VERSION "HNNBNNNYNNNNNNNNNNNNNNNNNNNNNNNNNNNNNNNNNN/4/%%%/4/'%**4NNN///"

NS_ :

BS_ :

BU_:  Airbag BAP_Tester ICAS1_Gateway ICAS1_KommunikationsServer LE1 LE2 Motor_BEV Schaltbetaetigung

BO_ 1648 Motor_18: 8 Motor_BEV
 SG_ MO_max_Ladedruck  : 0|6@1+ (0.100000,0.000000) [0.000000|6.300000] "Unit_Bar" ICAS1_Gateway
 SG_ MO_ANC_Kennfeld_Anf  : 6|2@1+ (1.000000,0.000000) [0.000000|3.000000] "" ICAS1_Gateway
 SG_ MO_Bremslicht_Reku  : 8|1@1+ (1.000000,0.000000) [0.000000|1.000000] "" ICAS1_Gateway
 SG_ MO_StartStopp_PopUp  : 9|2@1+ (1.000000,0.000000) [0.000000|3.000000] "" ICAS1_Gateway
 SG_ MO1_Sperr_Info_WFS  : 11|1@1+ (1.000000,0.000000) [0.000000|1.000000] "" ICAS1_Gateway
 SG_ MO1_Freigabe_Info_WFS  : 12|1@1+ (1.000000,0.000000) [0.000000|1.000000] "" ICAS1_Gateway
 SG_ MO_EPCL  : 13|3@1+ (1.000000,0.000000) [0.000000|7.000000] "" ICAS1_Gateway ICAS1_KommunikationsServer
 SG_ MO_Zylabsch_Texte_02  : 16|4@1+ (1.000000,0.000000) [0.000000|15.000000] "" ICAS1_Gateway
 SG_ MO_Fahrzeugtyp  : 20|3@1+ (1.000000,0.000000) [0.000000|7.000000] "" ICAS1_Gateway ICAS1_KommunikationsServer
 SG_ MO_NMAX_Schaltanzeige  : 23|9@1+ (25.000000,0.000000) [0.000000|12775.000000] "Unit_MinutInver" ICAS1_Gateway
 SG_ MO_Abstellzeit  : 32|8@1+ (8.000000,0.000000) [0.000000|2024.000000] "Unit_Minut" ICAS1_Gateway
 SG_ MO_Abstellzeit_Status  : 40|2@1+ (1.000000,0.000000) [0.000000|3.000000] "" ICAS1_Gateway
 SG_ MO1_Freigabe_Verfallsinfo_WFS  : 42|1@1+ (1.000000,0.000000) [0.000000|1.000000] "" ICAS1_Gateway
 SG_ MO_Hybrid_StartStopp_LED  : 43|2@1+ (1.000000,0.000000) [0.000000|3.000000] "" ICAS1_Gateway
 SG_ MO_Fehler_Zylabsch  : 45|2@1+ (1.000000,0.000000) [0.000000|3.000000] "" ICAS1_Gateway
 SG_ MO_Anzahl_Abgesch_Zyl  : 47|3@1+ (1.000000,0.000000) [0.000000|7.000000] "" ICAS1_Gateway
 SG_ MO_Zylabsch_Texte  : 50|2@1+ (1.000000,0.000000) [0.000000|3.000000] "" ICAS1_Gateway
 SG_ MO_Ethanol_BS_Texte  : 52|3@1+ (1.000000,0.000000) [0.000000|7.000000] "" ICAS1_Gateway
 SG_ MO_Drehzahl_Warnung  : 55|1@1+ (1.000000,0.000000) [0.000000|1.000000] "" ICAS1_Gateway
 SG_ MO_obere_Drehzahlgrenze  : 56|8@1+ (50.000000,0.000000) [50.000000|12750.000000] "Unit_MinutInver" ICAS1_Gateway

BO_ 967 Motor_26: 8 Motor_BEV
 SG_ MO_Kuehlerluefter_MUX M : 0|1@1+ (1.000000,0.000000) [0.000000|1.000000] "siema ooo" ICAS1_Gateway
 SG_ MO_Kuehlerluefter_1 m0 : 1|7@1+ (1.000000,0.000000) [0.000000|100.000000] "Unit_PerCent" ICAS1_Gateway
 SG_ MO_Kuehlerluefter_2 m1 : 1|7@1+ (1.000000,0.000000) [0.000000|100.000000] "Unit_PerCent" ICAS1_Gateway
 SG_ MO_EFLEX_Lampe  : 8|2@1+ (1.000000,0.000000) [0.000000|3.000000] "" ICAS1_Gateway
 SG_ MO_KJS_nicht_bereit  : 10|1@1+ (1.000000,0.000000) [0.000000|1.000000] "" ICAS1_Gateway
 SG_ MO_ITM_Warnung_Pumpe  : 11|1@1+ (1.000000,0.000000) [0.000000|1.000000] "" ICAS1_Gateway
 SG_ WIV_Anzeige_aktiv  : 12|1@1+ (1.000000,0.000000) [0.000000|1.000000] "" ICAS1_Gateway
 SG_ WIV_Oelmin_Warn  : 13|1@1+ (1.000000,0.000000) [0.000000|1.000000] "" ICAS1_Gateway
 SG_ WIV_Sensorfehler  : 14|1@1+ (1.000000,0.000000) [0.000000|1.000000] "" ICAS1_Gateway
 SG_ WIV_Schieflage  : 15|1@1+ (1.000000,0.000000) [0.000000|1.000000] "" ICAS1_Gateway
 SG_ WIV_Oelstand  : 16|4@1+ (12.500000,0.000000) [0.000000|100.000000] "Unit_PerCent" ICAS1_Gateway
 SG_ MO_Zustand_HWP  : 20|2@1+ (1.000000,0.000000) [0.000000|3.000000] "" ICAS1_Gateway
 SG_ OLEV_Systemstoerung  : 22|1@1+ (1.000000,0.000000) [0.000000|1.000000] "" ICAS1_Gateway
 SG_ MO_Oelwarnung_max  : 23|1@1+ (1.000000,0.000000) [0.000000|1.000000] "" ICAS1_Gateway
 SG_ WIV_Oelsystem_aktiv  : 24|1@1+ (1.000000,0.000000) [0.000000|1.000000] "" ICAS1_Gateway
 SG_ WIV_nicht_betriebswarm  : 25|1@1+ (1.000000,0.000000) [0.000000|1.000000] "" ICAS1_Gateway
 SG_ WIV_Ueberfuell_Warn  : 26|1@1+ (1.000000,0.000000) [0.000000|1.000000] "" ICAS1_Gateway
 SG_ WIV_laufender_Motor  : 27|1@1+ (1.000000,0.000000) [0.000000|1.000000] "" ICAS1_Gateway
 SG_ MO_E_Warnungen  : 28|4@1+ (1.000000,0.000000) [0.000000|15.000000] "" ICAS1_Gateway
 SG_ MO_Text_Motorstart  : 32|4@1+ (1.000000,0.000000) [0.000000|15.000000] "" ICAS1_Gateway
 SG_ MO_E_Texte  : 36|4@1+ (1.000000,0.000000) [0.000000|15.000000] "" ICAS1_Gateway
 SG_ WIV_Oeldyn_avl  : 40|1@1+ (1.000000,0.000000) [0.000000|1.000000] "" ICAS1_Gateway
 SG_ MO_Text_Partikelfil_Reg  : 41|1@1+ (1.000000,0.000000) [0.000000|1.000000] "" ICAS1_Gateway
 SG_ OLEV_Oelstand_nicht_vorhanden  : 42|1@1+ (1.000000,0.000000) [0.000000|1.000000] "" ICAS1_Gateway
 SG_ WIV_Oelmenge  : 43|5@1+ (125.000000,0.000000) [0.000000|3875.000000] "Unit_MilliLiter" ICAS1_Gateway
 SG_ MO_Systemlampe  : 48|1@1+ (1.000000,0.000000) [0.000000|1.000000] "" ICAS1_Gateway
 SG_ MO_OBD2_Lampe  : 49|1@1+ (1.000000,0.000000) [0.000000|1.000000] "" ICAS1_Gateway
 SG_ MO_Heissleuchte  : 50|1@1+ (1.000000,0.000000) [0.000000|1.000000] "" ICAS1_Gateway
 SG_ MO_Partikel_Lampe  : 51|1@1+ (1.000000,0.000000) [0.000000|1.000000] "" ICAS1_Gateway
 SG_ MO_RedFahrleistung_Lampe  : 52|1@1+ (1.000000,0.000000) [0.000000|1.000000] "" ICAS1_Gateway ICAS1_KommunikationsServer
 SG_ WIV_Oelstand_nicht_vorhanden  : 53|1@1+ (1.000000,0.000000) [0.000000|1.000000] "" ICAS1_Gateway
 SG_ WIV_nachfuellanzeige_ein  : 54|1@1+ (1.000000,0.000000) [0.000000|1.000000] "" ICAS1_Gateway
 SG_ WIV_Ueberfuell_deaktiv  : 55|1@1+ (1.000000,0.000000) [0.000000|1.000000] "" ICAS1_Gateway
 SG_ WIV_Unterfuell_Warn  : 56|1@1+ (1.000000,0.000000) [0.000000|1.000000] "" ICAS1_Gateway
 SG_ MO_Tankdeckel_Lampe  : 57|1@1+ (1.000000,0.000000) [0.000000|1.000000] "" ICAS1_Gateway
 SG_ MO_Text_Tankdeckelwarn  : 58|1@1+ (1.000000,0.000000) [0.000000|1.000000] "" ICAS1_Gateway
 SG_ MO_Vorglueh_Lampe  : 59|1@1+ (1.000000,0.000000) [0.000000|1.000000] "" ICAS1_Gateway
 SG_ WIV_Oeldr_Warn_Motor  : 60|1@1+ (1.000000,0.000000) [0.000000|1.000000] "" ICAS1_Gateway
 SG_ MO_E_Mode  : 61|3@1+ (1.000000,0.000000) [0.000000|7.000000] "" ICAS1_Gateway

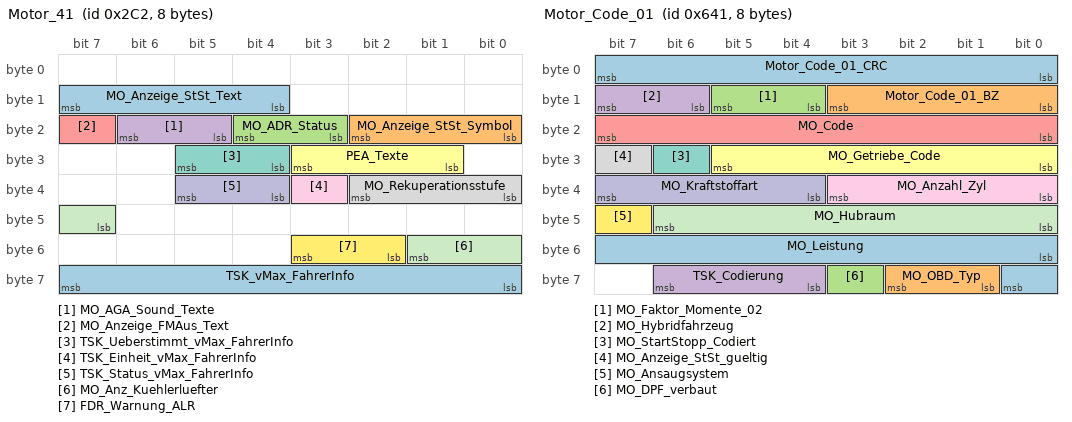
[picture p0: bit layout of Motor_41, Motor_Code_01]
BO_ 706 Motor_41: 8 Motor_BEV
 SG_ MO_Anzeige_StSt_Text  : 12|4@1+ (1.000000,0.000000) [0.000000|15.000000] "" Vector__XXX
 SG_ MO_Anzeige_StSt_Symbol  : 16|3@1+ (1.000000,0.000000) [0.000000|7.000000] "" Vector__XXX
 SG_ MO_ADR_Status  : 19|2@1+ (1.000000,0.000000) [0.000000|3.000000] "" Vector__XXX
 SG_ MO_AGA_Sound_Texte  : 21|2@1+ (1.000000,0.000000) [0.000000|3.000000] "" Vector__XXX
 SG_ MO_Anzeige_FMAus_Text  : 23|1@1+ (1.000000,0.000000) [0.000000|1.000000] "" Vector__XXX
 SG_ PEA_Texte  : 25|3@1+ (1.000000,0.000000) [0.000000|7.000000] "" Vector__XXX
 SG_ TSK_Ueberstimmt_vMax_FahrerInfo  : 28|2@1+ (1.000000,0.000000) [0.000000|3.000000] "" Vector__XXX
 SG_ MO_Rekuperationsstufe  : 32|3@1+ (1.000000,0.000000) [0.000000|7.000000] "" ICAS1_KommunikationsServer
 SG_ TSK_Einheit_vMax_FahrerInfo  : 35|1@1+ (1.000000,0.000000) [0.000000|1.000000] "" ICAS1_KommunikationsServer
 SG_ TSK_Status_vMax_FahrerInfo  : 36|2@1+ (1.000000,0.000000) [0.000000|3.000000] "" ICAS1_KommunikationsServer
 SG_ MO_Anz_Kuehlerluefter  : 47|3@1+ (1.000000,0.000000) [0.000000|7.000000] "" Vector__XXX
 SG_ FDR_Warnung_ALR  : 50|2@1+ (1.000000,0.000000) [0.000000|3.000000] "" ICAS1_KommunikationsServer
 SG_ TSK_vMax_FahrerInfo  : 56|8@1+ (1.000000,15.000000) [16.000000|270.000000] "" ICAS1_KommunikationsServer

BO_ 267 Motor_51: 32 Motor_BEV
 SG_ Motor_51_CRC  : 0|8@1+ (1.000000,0.000000) [0.000000|255.000000] "" ICAS1_Gateway
 SG_ Motor_51_BZ  : 8|4@1+ (1.000000,0.000000) [0.000000|15.000000] "" ICAS1_Gateway
 SG_ MO_Fahrpedalrohwert_01  : 12|8@1+ (0.400000,0.000000) [0.000000|101.600000] "Unit_PerCent" Airbag ICAS1_Gateway
 SG_ MO_QBit_Fahrpedalwerte_01  : 20|1@1+ (1.000000,0.000000) [0.000000|1.000000] "" Airbag ICAS1_Gateway
 SG_ MO_Fahrpedalgradient  : 21|8@1+ (25.000000,0.000000) [0.000000|6350.000000] "Unit_PerCentPerSecon" ICAS1_Gateway
 SG_ MO_Sig_Fahrpedalgradient  : 29|1@1+ (1.000000,0.000000) [0.000000|1.000000] "" ICAS1_Gateway
 SG_ MO_rel_Saugrohrdruck  : 30|6@1+ (18.000000,0.000000) [0.000000|1116.000000] "Unit_MilliBar" ICAS1_Gateway
 SG_ MO_rel_Saugrohrdruck_gem_err  : 36|1@1+ (1.000000,0.000000) [0.000000|1.000000] "" ICAS1_Gateway
 SG_ MO_Moment_im_Leerlauf  : 37|1@1+ (1.000000,0.000000) [0.000000|1.000000] "" ICAS1_Gateway
 SG_ MO_Schubabschaltung  : 38|1@1+ (1.000000,0.000000) [0.000000|1.000000] "" ICAS1_Gateway
 SG_ MO_Solldrehz_Leerlauf  : 40|8@1+ (10.000000,0.000000) [0.000000|2540.000000] "Unit_MinutInver" ICAS1_Gateway
 SG_ MO_Entkopplung_Sollschlupf  : 48|7@1+ (20.000000,0.000000) [0.000000|2480.000000] "Unit_MinutInver" ICAS1_Gateway
 SG_ MO_temporaere_Fahrerabwesenheit  : 55|1@1+ (1.000000,0.000000) [0.000000|1.000000] "" ICAS1_Gateway
 SG_ TSK_a_Soll_gradientenbegrenzt  : 57|7@1+ (0.100000,-7.200000) [-7.200000|5.400000] "Unit_MeterPerSeconSquar" ICAS1_Gateway
 SG_ TSK_Radbremsmom  : 76|12@1+ (8.000000,0.000000) [0.000000|32760.000000] "Unit_NewtoMeter" ICAS1_Gateway
 SG_ TSK_Status  : 88|3@1+ (1.000000,0.000000) [0.000000|7.000000] "" ICAS1_Gateway
 SG_ TSK_v_Begrenzung_aktiv  : 91|1@1+ (1.000000,0.000000) [0.000000|1.000000] "" ICAS1_Gateway
 SG_ TSK_Standby_Anf_ESP  : 92|1@1+ (1.000000,0.000000) [0.000000|1.000000] "" ICAS1_Gateway
 SG_ TSK_Freig_WU  : 93|1@1+ (1.000000,0.000000) [0.000000|1.000000] "" ICAS1_Gateway
 SG_ TSK_Freig_Verzoeg_Anf  : 94|1@1+ (1.000000,0.000000) [0.000000|1.000000] "" ICAS1_Gateway
 SG_ TSK_Limiter_ausgewaehlt  : 95|1@1+ (1.000000,0.000000) [0.000000|1.000000] "" ICAS1_Gateway
 SG_ TSK_Wunsch_Uebersetz  : 96|10@1+ (0.024500,0.000000) [0.024500|25.063500] "" ICAS1_Gateway
 SG_ TSK_Hauptschalter_GRA_ACC  : 106|2@1+ (1.000000,0.000000) [0.000000|3.000000] "" ICAS1_Gateway ICAS1_KommunikationsServer
 SG_ TSK_SRBM_Anf_ASIL  : 108|3@1+ (1.000000,0.000000) [0.000000|7.000000] "" ICAS1_Gateway
 SG_ TSK_ax_Getriebe_02  : 112|9@1+ (0.024000,-2.016000) [-2.016000|10.224000] "Unit_MeterPerSeconSquar" ICAS1_Gateway
 SG_ TSK_Zwangszusch_ESP  : 121|1@1+ (1.000000,0.000000) [0.000000|1.000000] "" ICAS1_Gateway
 SG_ TSK_zul_Regelabw  : 122|6@1+ (0.024000,0.000000) [0.000000|1.512000] "Unit_MeterPerSeconSquar" ICAS1_Gateway
 SG_ MO_Status_MinDrzEingriff  : 235|3@1+ (1.000000,0.000000) [0.000000|7.000000] "" ICAS1_Gateway
 SG_ MO_Status_MaxDrzEingriff  : 238|3@1+ (1.000000,0.000000) [0.000000|7.000000] "" ICAS1_Gateway
 SG_ MO_Status_MinDrzEingriff_sek  : 241|3@1+ (1.000000,0.000000) [0.000000|7.000000] "" ICAS1_Gateway
 SG_ MO_Status_MaxDrzEingriff_sek  : 244|3@1+ (1.000000,0.000000) [0.000000|7.000000] "" ICAS1_Gateway
 SG_ GRA_KuFu_aktiv  : 247|1@1+ (1.000000,0.000000) [0.000000|1.000000] "" ICAS1_Gateway
 SG_ TSK_SRBM_max_Gradient  : 248|7@1+ (50.000000,0.000000) [0.000000|6250.000000] "Unit_NewtoMeterPerSecon" ICAS1_Gateway
 SG_ LIM_KuFu_aktiv  : 255|1@1+ (1.000000,0.000000) [0.000000|1.000000] "" ICAS1_Gateway

BO_ 330 Motor_52: 32 Motor_BEV
 SG_ MO_Hochschaltdrehz  : 21|12@1+ (3.000000,0.000000) [3.000000|12282.000000] "Unit_MinutInver" Vector__XXX
 SG_ MO_Anzeige_Verbr_Einheit  : 33|2@1+ (1.000000,0.000000) [0.000000|3.000000] "" Vector__XXX
 SG_ MO_Schaltblitz_Anz  : 35|7@1+ (1.000000,0.000000) [0.000000|100.000000] "Unit_PerCent" Vector__XXX
 SG_ MO_Anzeige_Drehmoment  : 42|11@1+ (1.000000,0.000000) [0.000000|2045.000000] "Unit_NewtoMeter" Vector__XXX
 SG_ MO_Anzeige_Leistung  : 53|11@1+ (0.600000,0.000000) [0.000000|1227.000000] "Unit_KiloWatt" Vector__XXX
 SG_ MO_rel_Ladedruck  : 64|8@1+ (0.400000,0.000000) [0.000000|100.000000] "Unit_PerCent" Vector__XXX
 SG_ MO_Istgang  : 72|4@1+ (1.000000,0.000000) [0.000000|15.000000] "" Vector__XXX
 SG_ MO_Sollgang  : 76|4@1+ (1.000000,0.000000) [0.000000|15.000000] "" Vector__XXX
 SG_ MO_Oeldruck  : 80|8@1+ (0.040000,0.000000) [0.000000|10.000000] "Unit_Bar" Vector__XXX
 SG_ MO_Anzeigedrehz  : 88|12@1+ (3.000000,0.000000) [0.000000|12282.000000] "Unit_MinutInver" Vector__XXX
 SG_ MO_Effizienzmodus  : 100|1@1+ (1.000000,0.000000) [0.000000|1.000000] "" Vector__XXX
 SG_ MO_Fehler_Oeldrucksensor  : 101|1@1+ (1.000000,0.000000) [0.000000|1.000000] "" Vector__XXX
 SG_ MO_Schaltempf_verfbar  : 102|1@1+ (1.000000,0.000000) [0.000000|1.000000] "" Vector__XXX
 SG_ MO_Ladedruck  : 103|9@1+ (0.010000,0.000000) [0.000000|5.100000] "Unit_Bar" Vector__XXX
 SG_ MO_KVS  : 112|15@1+ (1.000000,0.000000) [0.000000|32767.000000] "Unit_MicroLiter" Vector__XXX
 SG_ MO_KVS_Ueberlauf  : 127|1@1+ (1.000000,0.000000) [0.000000|1.000000] "" Vector__XXX
 SG_ MO_ePowermeter  : 128|8@1+ (0.400000,-0.400000) [0.000000|100.800000] "Unit_PerCent" Vector__XXX
 SG_ MO_ePerformance  : 136|8@1+ (0.400000,-0.400000) [0.000000|100.800000] "Unit_PerCent" ICAS1_KommunikationsServer
 SG_ MO_Zust_Antrieb  : 144|4@1+ (1.000000,0.000000) [0.000000|15.000000] "" Vector__XXX
 SG_ MO_Zust_Betriebsstrategie  : 148|3@1+ (1.000000,0.000000) [0.000000|7.000000] "" Vector__XXX
 SG_ Ladezustand_02  : 152|8@1+ (0.500000,0.000000) [0.000000|100.000000] "Unit_PerCent" ICAS1_Gateway ICAS1_KommunikationsServer
 SG_ MO_Powermeter_Elm_02  : 168|12@1+ (0.050000,-102.400000) [-100.000000|100.000000] "Unit_PerCent" Vector__XXX
 SG_ MO_Powermeter  : 180|12@1+ (1.000000,0.000000) [0.000000|4092.000000] "" ICAS1_KommunikationsServer

BO_ 512 Motor_53: 32 Motor_BEV
 SG_ TSK_Wunschgeschw  : 12|10@1+ (0.320000,0.000000) [0.000000|326.720000] "Unit_KiloMeterPerHour" ICAS1_Gateway ICAS1_KommunikationsServer
 SG_ TSK_praediktiver_Hinweis  : 22|3@1+ (1.000000,0.000000) [0.000000|7.000000] "" ICAS1_Gateway
 SG_ TSK_naechstes_Event  : 25|6@1+ (1.000000,0.000000) [0.000000|63.000000] "" ICAS1_Gateway
 SG_ TSK_Fahrzeugstatus_praed_Fkt  : 31|3@1+ (1.000000,0.000000) [0.000000|7.000000] "" ICAS1_Gateway
 SG_ TSK_Texte  : 40|5@1+ (1.000000,0.000000) [0.000000|31.000000] "" ICAS1_Gateway ICAS1_KommunikationsServer
 SG_ TSK_Akustik  : 45|3@1+ (1.000000,0.000000) [0.000000|7.000000] "" ICAS1_Gateway ICAS1_KommunikationsServer
 SG_ TSK_Texte_Primaeranz  : 48|5@1+ (1.000000,0.000000) [0.000000|31.000000] "" ICAS1_Gateway ICAS1_KommunikationsServer
 SG_ TSK_Limiter_Fahrerinfo  : 53|2@1+ (1.000000,0.000000) [0.000000|3.000000] "" ICAS1_Gateway ICAS1_KommunikationsServer
 SG_ TSK_Limiter_Anzeige  : 55|1@1+ (1.000000,0.000000) [0.000000|1.000000] "" ICAS1_Gateway ICAS1_KommunikationsServer
 SG_ TSK_Fahrzeugstatus_GRA  : 56|1@1+ (1.000000,0.000000) [0.000000|1.000000] "" ICAS1_Gateway ICAS1_KommunikationsServer
 SG_ TSK_Fahrzeugstatus_Limiter  : 57|1@1+ (1.000000,0.000000) [0.000000|1.000000] "" ICAS1_Gateway ICAS1_KommunikationsServer
 SG_ MO_Motorlaufwarnung  : 58|1@1+ (1.000000,0.000000) [0.000000|1.000000] "" ICAS1_Gateway
 SG_ TSK_naechstes_Event_Einheit  : 60|1@1+ (1.000000,0.000000) [0.000000|1.000000] "" ICAS1_Gateway
 SG_ TSK_Status_Anzeige  : 61|3@1+ (1.000000,0.000000) [0.000000|7.000000] "" ICAS1_Gateway ICAS1_KommunikationsServer
 SG_ MO_Sperrung_FahrPr_BZS  : 64|8@1+ (1.000000,0.000000) [0.000000|255.000000] "" ICAS1_Gateway
 SG_ MO_Rampenzeit_Generator_Anf  : 72|4@1+ (1.000000,0.000000) [0.000000|15.000000] "" ICAS1_Gateway
 SG_ MO_Prio_MAX_Wunschdrehzahl  : 76|1@1+ (1.000000,0.000000) [0.000000|1.000000] "" ICAS1_Gateway
 SG_ MO_Prio_MIN_Wunschdrehzahl  : 77|1@1+ (1.000000,0.000000) [0.000000|1.000000] "" ICAS1_Gateway
 SG_ MO_Luftpfad_aktiv  : 78|1@1+ (1.000000,0.000000) [0.000000|1.000000] "" ICAS1_Gateway
 SG_ MO_v_Begrenz_Aktivierbar  : 79|1@1+ (1.000000,0.000000) [0.000000|1.000000] "" ICAS1_Gateway
 SG_ MO_Drehzahlbeeinflussung  : 80|8@1+ (0.390000,0.000000) [0.000000|99.450000] "Unit_PerCent" ICAS1_Gateway
 SG_ MO_MIN_Wunschdrehzahl  : 88|8@1+ (25.000000,0.000000) [0.000000|6350.000000] "Unit_MinutInver" ICAS1_Gateway
 SG_ MO_MAX_Wunschdrehzahl  : 96|9@1+ (25.000000,0.000000) [0.000000|12750.000000] "Unit_MinutInver" ICAS1_Gateway
 SG_ MO_Charisma_FahrPr  : 105|4@1+ (1.000000,0.000000) [0.000000|15.000000] "" ICAS1_Gateway
 SG_ MO_Charisma_Status  : 109|2@1+ (1.000000,0.000000) [0.000000|3.000000] "" ICAS1_Gateway
 SG_ MO_StSt_Charisma_FahrPr  : 111|4@1+ (1.000000,0.000000) [0.000000|15.000000] "" ICAS1_Gateway
 SG_ MO_StSt_Charisma_Status  : 115|2@1+ (1.000000,0.000000) [0.000000|3.000000] "" ICAS1_Gateway
 SG_ MO_BZS_Charisma_FahrPr  : 117|4@1+ (1.000000,0.000000) [0.000000|15.000000] "" ICAS1_Gateway
 SG_ MO_BZS_Charisma_Status  : 121|2@1+ (1.000000,0.000000) [0.000000|3.000000] "" ICAS1_Gateway
 SG_ MO_NGS_Position  : 123|1@1+ (1.000000,0.000000) [0.000000|1.000000] "" ICAS1_Gateway
 SG_ MO_NGS_Status  : 124|2@1+ (1.000000,0.000000) [0.000000|3.000000] "" ICAS1_Gateway
 SG_ MO_v_Begrenzung_Niveau  : 126|2@1+ (1.000000,0.000000) [0.000000|3.000000] "" ICAS1_Gateway
 SG_ MO_Anzeige_Rekuperation  : 128|8@1+ (0.500000,-0.500000) [0.000000|100.000000] "Unit_PerCent" ICAS1_Gateway
 SG_ PEA_Fortschrittsanzeige  : 136|7@1+ (1.000000,0.000000) [0.000000|100.000000] "Unit_PerCent" ICAS1_Gateway
 SG_ MO_Anzeige_Fahrbereitschaft  : 143|1@1+ (1.000000,0.000000) [0.000000|1.000000] "" ICAS1_Gateway ICAS1_KommunikationsServer
 SG_ MO_Boost_verfuegbar  : 144|8@1+ (0.400000,-0.400000) [0.000000|100.400000] "Unit_PerCent" ICAS1_Gateway
 SG_ MO_Overboost  : 152|1@1+ (1.000000,0.000000) [0.000000|1.000000] "" ICAS1_Gateway
 SG_ MO_Boost_aktiv  : 153|1@1+ (1.000000,0.000000) [0.000000|1.000000] "" ICAS1_Gateway
 SG_ MO_Anzeige_Betriebsmodus  : 154|4@1+ (1.000000,0.000000) [0.000000|15.000000] "" ICAS1_Gateway
 SG_ PEA_Hinweis  : 158|2@1+ (1.000000,0.000000) [0.000000|3.000000] "" ICAS1_Gateway
 SG_ PEA_Ereignisanzeige  : 160|5@1+ (1.000000,0.000000) [0.000000|31.000000] "" ICAS1_Gateway
 SG_ PEA_Ereignisanzeige_temporaer  : 165|1@1+ (1.000000,0.000000) [0.000000|1.000000] "" ICAS1_Gateway
 SG_ PEA_Abschalttexte  : 166|2@1+ (1.000000,0.000000) [0.000000|3.000000] "" ICAS1_Gateway
 SG_ PEA_Zielgeschw_Einheit  : 168|1@1+ (1.000000,0.000000) [0.000000|1.000000] "" ICAS1_Gateway
 SG_ PEA_Zielgeschw  : 169|5@1+ (1.000000,0.000000) [0.000000|31.000000] "" ICAS1_Gateway
 SG_ MO_Antriebsstrang_Warnung_HS  : 174|2@1+ (1.000000,0.000000) [0.000000|3.000000] "" ICAS1_Gateway
 SG_ MO_Anzeige_Verbrauch_oE  : 176|16@1+ (0.005000,0.000000) [0.000000|327.675000] "Unit_None" ICAS1_Gateway

BO_ 332 Motor_54: 32 Motor_BEV
 SG_ MO_Anforderung_HMS  : 12|3@1+ (1.000000,0.000000) [0.000000|7.000000] "" ICAS1_Gateway
 SG_ FoD_DTC_TSK_GRA  : 15|1@1+ (1.000000,0.000000) [0.000000|1.000000] "" ICAS1_Gateway
 SG_ TSK_vMax_aktuell  : 16|8@1+ (1.000000,0.000000) [0.000000|253.000000] "Unit_KiloMeterPerHour" ICAS1_Gateway
 SG_ TSK_Status_EA  : 32|3@1+ (1.000000,0.000000) [0.000000|7.000000] "" ICAS1_Gateway
 SG_ FoD_DTC_TSK_ACC  : 35|1@1+ (1.000000,0.000000) [0.000000|1.000000] "" ICAS1_Gateway
 SG_ TSK_ACC_FoD_Status  : 36|2@1+ (1.000000,0.000000) [0.000000|3.000000] "" ICAS1_Gateway
 SG_ TSK_GRA_FoD_Status  : 38|2@1+ (1.000000,0.000000) [0.000000|3.000000] "" ICAS1_Gateway
 SG_ TSK_vMax_Fahrerassistenz  : 40|9@1+ (1.000000,0.000000) [0.000000|510.000000] "" ICAS1_Gateway
 SG_ TSK_Einheit_vMax_Fahrerassistenz  : 49|1@1+ (1.000000,0.000000) [0.000000|1.000000] "" ICAS1_Gateway
 SG_ TSK_Status_PLA  : 50|3@1+ (1.000000,0.000000) [0.000000|7.000000] "" ICAS1_Gateway
 SG_ TSK_aktives_System  : 53|3@1+ (1.000000,0.000000) [0.000000|7.000000] "" ICAS1_Gateway
 SG_ TSK_erhoehter_Fahrwiderstand  : 56|1@1+ (1.000000,0.000000) [0.000000|1.000000] "" ICAS1_Gateway
 SG_ TSK_Anf_Antriebsmoment  : 57|1@1+ (1.000000,0.000000) [0.000000|1.000000] "" ICAS1_Gateway
 SG_ TSK_Status_ARA  : 58|3@1+ (1.000000,0.000000) [0.000000|7.000000] "" ICAS1_Gateway
 SG_ TSK_Status_IPA  : 61|3@1+ (1.000000,0.000000) [0.000000|7.000000] "" ICAS1_Gateway
 SG_ MO_Fahrbereitschaft  : 76|2@1+ (1.000000,0.000000) [0.000000|3.000000] "" ICAS1_Gateway LE1 LE2
 SG_ MO_Freilauf_Info  : 78|2@1+ (1.000000,0.000000) [0.000000|3.000000] "" ICAS1_Gateway
 SG_ MO_Krit_Heckobjekt  : 81|3@1+ (1.000000,0.000000) [0.000000|7.000000] "" ICAS1_Gateway
 SG_ MO_NGS_Gangpos  : 84|3@1+ (1.000000,0.000000) [0.000000|7.000000] "" ICAS1_Gateway
 SG_ MO_Freilauf_Status  : 87|3@1+ (1.000000,0.000000) [0.000000|7.000000] "" ICAS1_Gateway
 SG_ MO_EBoost_verf_praed  : 90|2@1+ (1.000000,0.000000) [0.000000|3.000000] "" ICAS1_Gateway
 SG_ MO_Heckspoiler_Anf  : 92|1@1+ (1.000000,0.000000) [0.000000|1.000000] "" ICAS1_Gateway
 SG_ MO_eLaunch_verf  : 93|2@1+ (1.000000,0.000000) [0.000000|3.000000] "" ICAS1_Gateway
 SG_ MO_Positionierung_aktiv  : 95|1@1+ (1.000000,0.000000) [0.000000|1.000000] "" ICAS1_Gateway
 SG_ MO_Freilauf_Typ  : 98|2@1+ (1.000000,0.000000) [0.000000|3.000000] "" ICAS1_Gateway
 SG_ MO_Startwunsch  : 100|1@1+ (1.000000,0.000000) [0.000000|1.000000] "" ICAS1_Gateway
 SG_ OBD_Calc_Load_Val  : 128|8@1+ (0.392157,0.000000) [0.000000|100.000000] "Unit_PerCent" ICAS1_Gateway LE1 LE2
 SG_ OBD_Eng_Cool_Temp  : 136|8@1+ (1.000000,-40.000000) [-40.000000|215.000000] "Unit_DegreCelsi" ICAS1_Gateway LE1 LE2
 SG_ OBD_Abs_Throttle_Pos  : 144|8@1+ (0.392157,0.000000) [0.000000|100.000000] "Unit_PerCent" ICAS1_Gateway LE1 LE2
 SG_ OBD_Abs_Load_Val  : 152|16@1+ (0.392157,0.000000) [0.000000|25700.000000] "Unit_PerCent" ICAS1_Gateway LE1 LE2
 SG_ OBD_Abs_Pedal_Pos  : 168|8@1+ (0.392157,0.000000) [0.000000|100.000000] "Unit_PerCent" ICAS1_Gateway LE1 LE2
 SG_ MO_Servicemodus  : 176|4@1+ (1.000000,0.000000) [0.000000|15.000000] "" ICAS1_Gateway LE1 LE2
 SG_ OBD_ClearMem_Inhibit  : 183|1@1+ (1.000000,0.000000) [0.000000|1.000000] "" ICAS1_Gateway LE1 LE2
 SG_ OBD_Sperrung_Kaltstart_Denom  : 184|1@1+ (1.000000,0.000000) [0.000000|1.000000] "" ICAS1_Gateway LE1 LE2
 SG_ MO_QBit_Aussen_Temp  : 185|1@1+ (1.000000,0.000000) [0.000000|1.000000] "" ICAS1_Gateway
 SG_ OBD_Sperrung_IUMPR  : 186|1@1+ (1.000000,0.000000) [0.000000|1.000000] "" ICAS1_Gateway LE1 LE2
 SG_ OBD_Kaltstart_Denominator  : 187|1@1+ (1.000000,0.000000) [0.000000|1.000000] "" ICAS1_Gateway LE1 LE2
 SG_ OBD_Minimum_Trip  : 188|1@1+ (1.000000,0.000000) [0.000000|1.000000] "" ICAS1_Gateway LE1 LE2
 SG_ OBD_Driving_Cycle  : 189|1@1+ (1.000000,0.000000) [0.000000|1.000000] "" ICAS1_Gateway LE1 LE2
 SG_ OBD_Warm_Up_Cycle  : 190|1@1+ (1.000000,0.000000) [0.000000|1.000000] "" ICAS1_Gateway LE1 LE2
 SG_ OBD_Normed_Trip  : 191|1@1+ (1.000000,0.000000) [0.000000|1.000000] "" ICAS1_Gateway LE1 LE2
 SG_ OBD_Aussen_Temp_gef  : 248|8@1+ (1.000000,-40.000000) [-40.000000|213.000000] "Unit_DegreCelsi" ICAS1_Gateway

BO_ 246 Motor_55: 32 Motor_BEV
 SG_ Motor_55_CRC  : 0|8@1+ (1.000000,0.000000) [0.000000|255.000000] "" ICAS1_Gateway
 SG_ Motor_55_BZ  : 8|4@1+ (1.000000,0.000000) [0.000000|15.000000] "" ICAS1_Gateway
 SG_ TS_Faktor_Radmomente  : 12|2@1+ (1.000000,0.000000) [0.000000|3.000000] "" ICAS1_Gateway
 SG_ TS_Status_MomRad_Ist  : 14|2@1+ (1.000000,0.000000) [0.000000|3.000000] "" ICAS1_Gateway
 SG_ TS_MomRad_verfuegb_maxReku_Summe  : 16|12@1+ (3.000000,-12279.000000) [-12279.000000|0.000000] "" ICAS1_Gateway
 SG_ TS_MomRad_Ist  : 28|13@1+ (3.000000,-12279.000000) [-12279.000000|12279.000000] "Unit_None" ICAS1_Gateway
 SG_ TS_MomRad_Soll_Summe  : 41|13@1+ (3.000000,-12279.000000) [-12279.000000|12279.000000] "Unit_None" ICAS1_Gateway
 SG_ TS_MomRad_Wunsch  : 54|13@1+ (3.000000,-12279.000000) [-12279.000000|12279.000000] "Unit_None" ICAS1_Gateway
 SG_ TS_MomRad_Wunsch_sek  : 67|13@1+ (3.000000,-12279.000000) [-12279.000000|12279.000000] "Unit_None" ICAS1_Gateway
 SG_ TS_MomRad_verfuegb_max  : 80|12@1+ (3.000000,0.000000) [0.000000|12279.000000] "Unit_None" ICAS1_Gateway
 SG_ TS_MomRad_verfuegb_max_sek  : 92|12@1+ (3.000000,0.000000) [0.000000|12279.000000] "Unit_None" ICAS1_Gateway
 SG_ TS_MomRad_verfuegb_maxReku  : 104|12@1+ (3.000000,-12279.000000) [-12279.000000|0.000000] "Unit_None" ICAS1_Gateway
 SG_ TS_MomRad_verfuegb_maxReku_sek  : 116|12@1+ (3.000000,-12279.000000) [-12279.000000|0.000000] "Unit_None" ICAS1_Gateway
 SG_ TS_MomRad_Ist_sek  : 128|13@1+ (3.000000,-12279.000000) [-12279.000000|12279.000000] "Unit_None" ICAS1_Gateway
 SG_ TS_Allrad_Anteil_sek  : 141|9@1+ (0.200000,0.000000) [0.000000|100.000000] "Unit_PerCent" ICAS1_Gateway
 SG_ FDR_Allrad_Anteil_max_sek  : 150|9@1+ (0.200000,0.000000) [0.000000|100.000000] "Unit_PerCent" ICAS1_Gateway
 SG_ FDR_Allrad_Anteil_min_sek  : 159|9@1+ (0.200000,0.000000) [0.000000|100.000000] "Unit_PerCent" ICAS1_Gateway
 SG_ FDR_MomRad_Eingriff  : 168|13@1+ (3.000000,-12279.000000) [-12279.000000|12279.000000] "Unit_NewtoMeter" ICAS1_Gateway
 SG_ FDR_Status_Eingriff  : 181|1@1+ (1.000000,0.000000) [0.000000|1.000000] "" ICAS1_Gateway
 SG_ FDR_MomRad_Eingriff_sek  : 182|13@1+ (3.000000,-12279.000000) [-12279.000000|12279.000000] "Unit_NewtoMeter" ICAS1_Gateway
 SG_ FDR_Status_Eingriff_sek  : 195|1@1+ (1.000000,0.000000) [0.000000|1.000000] "" ICAS1_Gateway

BO_ 190 Motor_56: 48 Motor_BEV
 SG_ Motor_56_CRC  : 0|8@1+ (1.000000,0.000000) [0.000000|255.000000] "" ICAS1_Gateway LE1 LE2
 SG_ Motor_56_BZ  : 8|4@1+ (1.000000,0.000000) [0.000000|15.000000] "" ICAS1_Gateway LE1 LE2
 SG_ MO_EM1_MinDrehzahl  : 12|14@1+ (2.000000,-10000.000000) [-10000.000000|22764.000000] "Unit_MinutInver" ICAS1_Gateway LE1
 SG_ MO_EM1_MaxDrehzahl  : 26|14@1+ (2.000000,-10000.000000) [-10000.000000|22764.000000] "Unit_MinutInver" ICAS1_Gateway LE1
 SG_ MO_EM1_DynLimit_AR  : 40|8@1+ (1.000000,0.000000) [0.000000|254.000000] "Unit_NewtoMeter" ICAS1_Gateway LE1
 SG_ MO_EM1_Periode_AR  : 48|8@1+ (0.001953,0.000000) [0.000000|0.496094] "Unit_Secon" ICAS1_Gateway LE1
 SG_ MO_EM1_SollMoment  : 56|12@1+ (0.500000,-1023.000000) [-1023.000000|1023.500000] "Unit_NewtoMeter" ICAS1_Gateway LE1
 SG_ MO_EM1_Sollmodus  : 68|4@1+ (1.000000,0.000000) [0.000000|15.000000] "" ICAS1_Gateway LE1
 SG_ MO_EM1_Min_Leistung  : 72|14@1+ (100.000000,-819000.000000) [-819000.000000|819100.000000] "Unit_Watt" ICAS1_Gateway LE1
 SG_ MO_EM1_Max_Leistung  : 86|14@1+ (100.000000,-819000.000000) [-819000.000000|819100.000000] "Unit_Watt" ICAS1_Gateway LE1
 SG_ MO_EM1_Min_Strom_Lim  : 100|13@1+ (0.500000,-2047.000000) [-2047.000000|2047.500000] "Unit_Amper" ICAS1_Gateway LE1
 SG_ MO_EM1_Max_Strom_Lim  : 113|13@1+ (0.500000,-2047.000000) [-2047.000000|2047.500000] "Unit_Amper" ICAS1_Gateway LE1
 SG_ MO_EM1_AR_Anf  : 126|3@1+ (1.000000,0.000000) [0.000000|7.000000] "" ICAS1_Gateway LE1
 SG_ MO_EM1_Kp_AR  : 129|9@1+ (0.003906,0.000000) [0.000000|1.992188] "Unit_NewtoMeterPerRPM" ICAS1_Gateway LE1
 SG_ MO_EM1_SollSpannung  : 138|12@1+ (0.500000,0.000000) [0.000000|2047.000000] "Unit_Volt" ICAS1_Gateway LE1
 SG_ MO_EM2_MinDrehzahl  : 156|14@1+ (2.000000,-10000.000000) [-10000.000000|22764.000000] "Unit_MinutInver" ICAS1_Gateway LE2
 SG_ MO_EM2_MaxDrehzahl  : 170|14@1+ (2.000000,-10000.000000) [-10000.000000|22764.000000] "Unit_MinutInver" ICAS1_Gateway LE2
 SG_ MO_EM2_DynLimit_AR  : 184|8@1+ (1.000000,0.000000) [0.000000|254.000000] "Unit_NewtoMeter" ICAS1_Gateway LE2
 SG_ MO_EM2_Periode_AR  : 192|8@1+ (0.001953,0.000000) [0.000000|0.496094] "Unit_Secon" ICAS1_Gateway LE2
 SG_ MO_EM2_SollMoment  : 200|12@1+ (0.500000,-1023.000000) [-1023.000000|1023.500000] "Unit_NewtoMeter" ICAS1_Gateway LE2
 SG_ MO_EM2_Sollmodus  : 212|4@1+ (1.000000,0.000000) [0.000000|15.000000] "" ICAS1_Gateway LE2
 SG_ MO_EM2_Min_Leistung  : 216|14@1+ (100.000000,-819000.000000) [-819000.000000|819100.000000] "Unit_Watt" ICAS1_Gateway LE2
 SG_ MO_EM2_Max_Leistung  : 230|14@1+ (100.000000,-819000.000000) [-819000.000000|819100.000000] "Unit_Watt" ICAS1_Gateway LE2
 SG_ MO_EM2_Min_Strom_Lim  : 244|13@1+ (0.500000,-2047.000000) [-2047.000000|2047.500000] "Unit_Amper" ICAS1_Gateway LE2
 SG_ MO_EM2_Max_Strom_Lim  : 257|13@1+ (0.500000,-2047.000000) [-2047.000000|2047.500000] "Unit_Amper" ICAS1_Gateway LE2
 SG_ MO_EM2_AR_Anf  : 270|3@1+ (1.000000,0.000000) [0.000000|7.000000] "" ICAS1_Gateway LE2
 SG_ MO_EM2_SollSpannung  : 282|12@1+ (0.500000,0.000000) [0.000000|2047.000000] "Unit_Volt" ICAS1_Gateway LE2
 SG_ MO_DC_Max_Strom_HV  : 296|8@1+ (0.200000,0.000000) [0.000000|50.800000] "Unit_Amper" ICAS1_Gateway
 SG_ MO_DC_SollSpannung_HV  : 304|8@1+ (2.000000,0.000000) [0.000000|508.000000] "Unit_Volt" ICAS1_Gateway
 SG_ MO_EM1_Max_Moment  : 312|12@1+ (0.500000,-1023.000000) [-1023.000000|1023.500000] "Unit_NewtoMeter" ICAS1_Gateway LE1
 SG_ MO_EM1_Min_Moment  : 324|12@1+ (0.500000,-1023.000000) [-1023.000000|1023.500000] "Unit_NewtoMeter" ICAS1_Gateway LE1
 SG_ MO_EM2_Max_Moment  : 336|12@1+ (0.500000,-1023.000000) [-1023.000000|1023.500000] "Unit_NewtoMeter" ICAS1_Gateway LE2
 SG_ MO_EM2_Min_Moment  : 348|12@1+ (0.500000,-1023.000000) [-1023.000000|1023.500000] "Unit_NewtoMeter" ICAS1_Gateway LE2

BO_ 2463978666 Motor_57: 32 Motor_BEV
 SG_ MO_EM1_Min_Spannung_Lim  : 12|10@1+ (1.000000,0.000000) [0.000000|1021.000000] "Unit_Volt" ICAS1_Gateway LE1
 SG_ MO_EM1_Max_Spannung_Lim  : 22|10@1+ (1.000000,0.000000) [0.000000|1021.000000] "Unit_Volt" ICAS1_Gateway LE1
 SG_ MO_EM1_Min_Leistung_Gesamt  : 32|13@1+ (200.000000,-819000.000000) [-819000.000000|818800.000000] "Unit_Watt" ICAS1_Gateway LE1
 SG_ MO_EM1_Max_Leistung_Gesamt  : 45|13@1+ (200.000000,-819000.000000) [-819000.000000|818800.000000] "Unit_Watt" ICAS1_Gateway LE1
 SG_ MO_EM2_Min_Leistung_Gesamt  : 58|13@1+ (200.000000,-819000.000000) [-819000.000000|818800.000000] "Unit_Watt" ICAS1_Gateway LE2
 SG_ MO_EM2_Max_Leistung_Gesamt  : 71|13@1+ (200.000000,-819000.000000) [-819000.000000|818800.000000] "Unit_Watt" ICAS1_Gateway LE2
 SG_ MO_EM2_Min_Spannung_Lim  : 84|10@1+ (1.000000,0.000000) [0.000000|1021.000000] "Unit_Volt" ICAS1_Gateway LE2
 SG_ MO_EM2_Max_Spannung_Lim  : 94|10@1+ (1.000000,0.000000) [0.000000|1021.000000] "Unit_Volt" ICAS1_Gateway LE2
 SG_ MO_EM1_Generator_Leistung  : 104|8@1+ (100.000000,0.000000) [0.000000|25300.000000] "Unit_Watt" ICAS1_Gateway LE1
 SG_ MO_Verbrauch_EM_Ges  : 120|15@1+ (10.000000,0.000000) [0.000000|327670.000000] "Unit_WattSecond" ICAS1_Gateway ICAS1_KommunikationsServer
 SG_ MO_Verbrauch_EM_Ges_Ueberlauf  : 135|1@1+ (1.000000,0.000000) [0.000000|1.000000] "" ICAS1_Gateway ICAS1_KommunikationsServer
 SG_ MO_Rekuperation_Ges_EM  : 136|15@1+ (10.000000,0.000000) [0.000000|327670.000000] "Unit_WattSecond" ICAS1_Gateway ICAS1_KommunikationsServer
 SG_ MO_Rekuperation_EM_Ges_Ueberlauf  : 151|1@1+ (1.000000,0.000000) [0.000000|1.000000] "" ICAS1_Gateway ICAS1_KommunikationsServer
 SG_ MO_Drehzahl_EM  : 152|13@1+ (8.000000,-32768.000000) [-32768.000000|32744.000000] "Unit_RevPerMinute" ICAS1_Gateway
 SG_ MO_Uebersetzung_EM  : 165|10@1+ (0.031250,0.000000) [0.031250|31.906250] "" ICAS1_Gateway
 SG_ MO_Drehzahl_EM_sek  : 175|13@1+ (8.000000,-32768.000000) [-32768.000000|32744.000000] "Unit_RevPerMinute" ICAS1_Gateway
 SG_ MO_Uebersetzung_EM_sek  : 188|10@1+ (0.031250,0.000000) [0.031250|31.906250] "" ICAS1_Gateway

BO_ 1601 Motor_Code_01: 8 Motor_BEV
 SG_ Motor_Code_01_CRC  : 0|8@1+ (1.000000,0.000000) [0.000000|255.000000] "" ICAS1_Gateway
 SG_ Motor_Code_01_BZ  : 8|4@1+ (1.000000,0.000000) [0.000000|15.000000] "" ICAS1_Gateway
 SG_ MO_Faktor_Momente_02  : 12|2@1+ (1.000000,0.000000) [1.000000|3.000000] "Unit_NewtoMeter" ICAS1_Gateway
 SG_ MO_Hybridfahrzeug  : 14|2@1+ (1.000000,0.000000) [0.000000|3.000000] "" ICAS1_Gateway
 SG_ MO_Code  : 16|8@1+ (1.000000,0.000000) [0.000000|255.000000] "" ICAS1_Gateway
 SG_ MO_Getriebe_Code  : 24|6@1+ (1.000000,0.000000) [0.000000|63.000000] "" ICAS1_Gateway
 SG_ MO_StartStopp_Codiert  : 30|1@1+ (1.000000,0.000000) [0.000000|1.000000] "" ICAS1_Gateway
 SG_ MO_Anzeige_StSt_gueltig  : 31|1@1+ (1.000000,0.000000) [0.000000|1.000000] "" ICAS1_Gateway
 SG_ MO_Anzahl_Zyl  : 32|4@1+ (1.000000,0.000000) [0.000000|15.000000] "" ICAS1_Gateway
 SG_ MO_Kraftstoffart  : 36|4@1+ (1.000000,0.000000) [0.000000|15.000000] "" ICAS1_Gateway ICAS1_KommunikationsServer
 SG_ MO_Hubraum  : 40|7@1+ (0.100000,0.000000) [0.000000|12.700000] "Unit_Liter" ICAS1_Gateway
 SG_ MO_Ansaugsystem  : 47|1@1+ (1.000000,0.000000) [0.000000|1.000000] "" ICAS1_Gateway
 SG_ MO_Leistung  : 48|9@1+ (1.000000,0.000000) [0.000000|511.000000] "Unit_KiloWatt" ICAS1_Gateway
 SG_ MO_OBD_Typ  : 57|2@1+ (1.000000,0.000000) [0.000000|3.000000] "" ICAS1_Gateway
 SG_ MO_DPF_verbaut  : 59|1@1+ (1.000000,0.000000) [0.000000|1.000000] "" ICAS1_Gateway
 SG_ TSK_Codierung  : 60|3@1+ (1.000000,0.000000) [0.000000|7.000000] "" ICAS1_Gateway

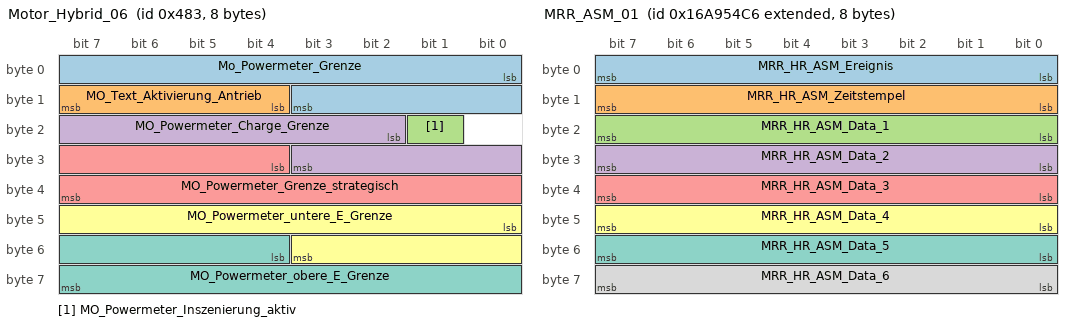
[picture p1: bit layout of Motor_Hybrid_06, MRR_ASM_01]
BO_ 1155 Motor_Hybrid_06: 8 Motor_BEV
 SG_ Mo_Powermeter_Grenze  : 0|12@1+ (1.000000,0.000000) [0.000000|4092.000000] "" ICAS1_KommunikationsServer
 SG_ MO_Text_Aktivierung_Antrieb  : 12|4@1+ (1.000000,0.000000) [0.000000|15.000000] "" ICAS1_KommunikationsServer
 SG_ MO_Powermeter_Inszenierung_aktiv  : 17|1@1+ (1.000000,0.000000) [0.000000|1.000000] "" Vector__XXX
 SG_ MO_Powermeter_Charge_Grenze  : 18|10@1+ (1.000000,0.000000) [0.000000|1021.000000] "Unit_None" ICAS1_KommunikationsServer
 SG_ MO_Powermeter_Grenze_strategisch  : 28|12@1+ (1.000000,0.000000) [0.000000|4093.000000] "Unit_None" ICAS1_KommunikationsServer
 SG_ MO_Powermeter_untere_E_Grenze  : 40|12@1+ (1.000000,0.000000) [0.000000|4093.000000] "Unit_None" Vector__XXX
 SG_ MO_Powermeter_obere_E_Grenze  : 52|12@1+ (1.000000,0.000000) [0.000000|4093.000000] "Unit_None" Vector__XXX

BO_ 2527679686 MRR_ASM_01: 8 ICAS1_Gateway
 SG_ MRR_HR_ASM_Ereignis  : 0|8@1+ (1.000000,0.000000) [1.000000|254.000000] "" Airbag
 SG_ MRR_HR_ASM_Zeitstempel  : 8|8@1+ (0.080000,0.000000) [0.000000|20.320000] "Unit_Secon" Airbag
 SG_ MRR_HR_ASM_Data_1  : 16|8@1+ (1.000000,0.000000) [0.000000|255.000000] "" Airbag
 SG_ MRR_HR_ASM_Data_2  : 24|8@1+ (1.000000,0.000000) [0.000000|255.000000] "" Airbag
 SG_ MRR_HR_ASM_Data_3  : 32|8@1+ (1.000000,0.000000) [0.000000|255.000000] "" Airbag
 SG_ MRR_HR_ASM_Data_4  : 40|8@1+ (1.000000,0.000000) [0.000000|255.000000] "" Airbag
 SG_ MRR_HR_ASM_Data_5  : 48|8@1+ (1.000000,0.000000) [0.000000|255.000000] "" Airbag
 SG_ MRR_HR_ASM_Data_6  : 56|8@1+ (1.000000,0.000000) [0.000000|255.000000] "" Airbag

BO_ 22 MSG3_WFS_Anfrage: 8 LE2
 SG_ WFS_MSG3_RND  : 0|32@1+ (1.000000,0.000000) [0.000000|4294967295.000000] "" ICAS1_Gateway
 SG_ WFS_MSG3_CRC  : 32|32@1+ (1.000000,0.000000) [0.000000|4294967295.000000] "" ICAS1_Gateway

BO_ 24 MSG4_WFS_Anfrage: 8 LE1
 SG_ WFS_MSG4_RND  : 0|32@1+ (1.000000,0.000000) [0.000000|4294967295.000000] "" ICAS1_Gateway
 SG_ WFS_MSG4_CRC  : 32|32@1+ (1.000000,0.000000) [0.000000|4294967295.000000] "" ICAS1_Gateway

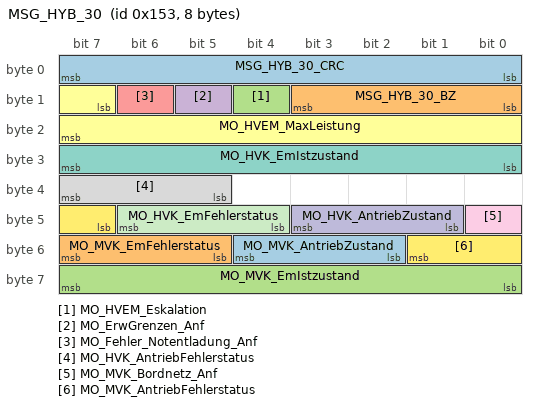
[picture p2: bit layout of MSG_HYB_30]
BO_ 339 MSG_HYB_30: 8 Motor_BEV
 SG_ MSG_HYB_30_CRC  : 0|8@1+ (1.000000,0.000000) [0.000000|255.000000] "" Vector__XXX
 SG_ MSG_HYB_30_BZ  : 8|4@1+ (1.000000,0.000000) [0.000000|15.000000] "" Vector__XXX
 SG_ MO_HVEM_Eskalation  : 12|1@1+ (1.000000,0.000000) [0.000000|1.000000] "" ICAS1_Gateway
 SG_ MO_ErwGrenzen_Anf  : 13|1@1+ (1.000000,0.000000) [0.000000|1.000000] "" LE1 LE2
 SG_ MO_Fehler_Notentladung_Anf  : 14|1@1+ (1.000000,0.000000) [0.000000|1.000000] "" Vector__XXX
 SG_ MO_HVEM_MaxLeistung  : 15|9@1+ (50.000000,0.000000) [0.000000|25450.000000] "Unit_Watt" ICAS1_Gateway
 SG_ MO_HVK_EmIstzustand  : 24|8@1+ (1.000000,0.000000) [0.000000|255.000000] "" Vector__XXX
 SG_ MO_HVK_AntriebFehlerstatus  : 37|3@1+ (1.000000,0.000000) [0.000000|7.000000] "" Vector__XXX
 SG_ MO_MVK_Bordnetz_Anf  : 40|1@1+ (1.000000,0.000000) [0.000000|1.000000] "" Vector__XXX
 SG_ MO_HVK_AntriebZustand  : 41|3@1+ (1.000000,0.000000) [0.000000|7.000000] "" Vector__XXX
 SG_ MO_HVK_EmFehlerstatus  : 44|3@1+ (1.000000,0.000000) [0.000000|7.000000] "" Vector__XXX
 SG_ MO_MVK_AntriebFehlerstatus  : 47|3@1+ (1.000000,0.000000) [0.000000|7.000000] "" Vector__XXX
 SG_ MO_MVK_AntriebZustand  : 50|3@1+ (1.000000,0.000000) [0.000000|7.000000] "" Vector__XXX
 SG_ MO_MVK_EmFehlerstatus  : 53|3@1+ (1.000000,0.000000) [0.000000|7.000000] "" Vector__XXX
 SG_ MO_MVK_EmIstzustand  : 56|8@1+ (1.000000,0.000000) [0.000000|255.000000] "" Vector__XXX

CM_ BO_ 1648 "Kombischnittstelle";
CM_ BO_ 967 "MQB-vorherMotor_06/Umbenennungwg.ID-Wechsel";
CM_ BO_ 1601 "abMQBmitCRC-8";
CM_ BO_ 339 "CAN-Botschaft";
CM_ SG_ 1648 MO_max_Ladedruck "maximalmöglicherLadedruck(zurAnpassungdesAnzeigebereichsbeiabsoluterLadedruckanzeige)";
CM_ SG_ 1648 MO_ANC_Kennfeld_Anf "AnforderungANCKennfeldumschaltung";
CM_ SG_ 1648 MO_Bremslicht_Reku "Bremslicht(ggf.beiRekuperationdurchE-Motor)wirdangesteuert";
CM_ SG_ 1648 MO_StartStopp_PopUp "DasSignalzeigtan,obderStSt-StatusmittelsDeaktivierungstastergeändertwurde.EinWechselaufdieWerte01oder10löstimKombieinentsprechendesPopUpaus.BeieinemStatuswechseldurchandereSignalquellen(z.B.Charisma,fehlerbedingteAbschal";
CM_ SG_ 1648 MO1_Sperr_Info_WFS "WFS-Sperrinformation";
CM_ SG_ 1648 MO1_Freigabe_Info_WFS "WFS-Freigabeinformation";
CM_ SG_ 1648 MO_EPCL "DieAnforderungderEPC-LampevomMSGansKombisolldurchdasBus-SignalMO_EPCLgemäßfolgenderLogikerfolgen:
MO_EPCL = 0 dez -> EPC Lampe aus, kein Text
MO_EPCL = 1 dez -> gelbe EPC-Symbolik, Text „Antrieb: Störung! Bitte Service aufsuchen“
MO_EPC";
CM_ SG_ 1648 MO_Zylabsch_Texte_02 "ZAS-AnzeigefürdenFahrerimKombi
0: kein ZAS (generell keinerlei ZAS-Anzeigen)  (Init für nicht ZAS-Motor)
1: ZAS im Vollmotorbetrieb  (Init für ZAS-Motor)
2: ZAS im Abschaltbetrieb: 1 Zyl aktiv
3: ZAS im Abschaltbetrieb: 2 Zyl aktiv
4: ZAS im Abs";
CM_ SG_ 1648 MO_Fahrzeugtyp "UnterscheidetdieFahrzeugtypenbzgl.derAntriebsart";
CM_ SG_ 1648 MO_NMAX_Schaltanzeige "MaximaldrehzahlfürSchaltanzeige";
CM_ SG_ 1648 MO_Abstellzeit "AbstelldauernachletztemKL15aus

Hinweis:
Ehemaliger Fehlerwert 0xFF wird senderseitig nicht unterstützt.
Diesen Wert aus Kompatibilitätsgründen nicht neu belegen!";
CM_ SG_ 1648 MO_Abstellzeit_Status "StatusinformationzurAbstellzeit
0: Die dem Status zugeordnete Variable konnte noch nicht berechnet werden.
1: Die dem Status zugehörige Variable wurde korrekt berechnet.
2: Der Wert der zugehörigen Variablen ist nur ein Minimalwert.
3: Der Wert d";
CM_ SG_ 1648 MO1_Freigabe_Verfallsinfo_WFS "WFS-Freigabeverfallsinformation";
CM_ SG_ 1648 MO_Hybrid_StartStopp_LED "AnsteuerungderFunktions-LEDderHybridTastebzw.Start/StopDeaktivierungstaste.
Der Start/Stopp-Master (derzeit im MSG) (oder ein künftiger Hybrid-Master) soll die Ansteuerung senden.";
CM_ SG_ 1648 MO_Fehler_Zylabsch "FehlerstatusderFunktionZylinderabschaltung";
CM_ SG_ 1648 MO_Anzahl_Abgesch_Zyl "GibtdieAnzahlderabgeschaltetenZylinderan.InÜbergangszuständenwirdderZielbetriebszustandangezeigt.";
CM_ SG_ 1648 MO_Zylabsch_Texte "ZylinderabschaltungmodeinKombi,fuerZylinderabschaltung";
CM_ SG_ 1648 MO_Ethanol_BS_Texte "EthanolBrennstoff-TexteimKombi

0 = kein Text
1 = E85 Warm_Up
2 = FlexFuel Warnung 3.Stufe (Too cold for ethanol)
3 = Warmfahrempfehlung MQB / FlexFuel Warnung 1.Stufe (Refuel with gasoline)
4 = FlexFuel Warnung 2. Stufe (Refuel with gasoline)
5";
CM_ SG_ 1648 MO_Drehzahl_Warnung "WarnhinweiszumKombiimFalleinerfehlerbehaftetenDrehzahlbegrenzung";
CM_ SG_ 1648 MO_obere_Drehzahlgrenze "obereDrehzahlgrenzedesMotors";
CM_ SG_ 967 MO_Kuehlerluefter_MUX "MultiplexerfürdasSignal'MO_Kuehlerlüfter'";
CM_ SG_ 967 MO_Kuehlerluefter_1 "Ansteuertastverhaeltnis(PWM)derKuehlerluefterendstufe1";
CM_ SG_ 967 MO_Kuehlerluefter_2 "Ansteuertastverhaeltnis(PWM)derKuehlerluefterendstufe2";
CM_ SG_ 967 MO_EFLEX_Lampe "UmeinStartenmitE100zuermöglichen,wirdKraftstoffggf.vorgeheizt.DasSignaldientderAnzeigedesHeizungsstatus.

Heizung aus -> Lampe aus
Heizung ein -> Lampe ein
Heizung ein und Startversuch -> Lampe blinkend
Heizung nicht möglich -> Lampe";
CM_ SG_ 967 MO_KJS_nicht_bereit "DiesesSignalzeigeneinenFehlerderKühlerjalousiemitunbekannterStellungderLamellen.";
CM_ SG_ 967 MO_ITM_Warnung_Pumpe "Textanzeige:'Motorsofortabstellen,geschalteteWasserpumpedefekt/klemmt'";
CM_ SG_ 967 WIV_Anzeige_aktiv "Peilstabsanzeigefunktionaktiv";
CM_ SG_ 967 WIV_Oelmin_Warn "SignalgibtanwennderÖlstanddieMin-Schwelleunterschrittenhat";
CM_ SG_ 967 WIV_Sensorfehler "Ölstand/Öltemperatursensor(TOG)defekt";
CM_ SG_ 967 WIV_Schieflage "Fahrzeugstehtnichtwaagerecht,Messungungenau";
CM_ SG_ 967 WIV_Oelstand "8SegmentezurBalkenanzeigedesÖlstands";
CM_ SG_ 967 MO_Zustand_HWP "RückmeldungdesAnsteuerzustandderHauptwasserpumpeandasKlima-SG.
Der Zustand 'HWP fördert' wird übermittelt, wenn die Schaufeln der Hauptwasserpumpe frei drehen können und die Motordrehzahl und damit die Wasserpumpendrehzahl größer als Null ist. B";
CM_ SG_ 967 OLEV_Systemstoerung "SystemstörungimÖlsystem";
CM_ SG_ 967 MO_Oelwarnung_max "ÖlstandswarnungmitderAufforderungzumÖlwechsel.
Hintergrund: Bei Kraftstoffeintrag (B20) ins Öl verbleibt der RME-Anteil irreversibel im Öl.";
CM_ SG_ 967 WIV_Oelsystem_aktiv "Gesamtölsystemaktiv(entsprichtÖlsensorverbaut)unddasÖlstand-UntermenuimMMIaktiv";
CM_ SG_ 967 WIV_nicht_betriebswarm "Motornichtbetriebswarm,Messungungenau";
CM_ SG_ 967 WIV_Ueberfuell_Warn "ÖlstandhatdieÜberfüllschwelleüberschritten";
CM_ SG_ 967 WIV_laufender_Motor "MessungbeilaufendemMotornichtmöglich";
CM_ SG_ 967 MO_E_Warnungen "AnforderungvonWarnanzeigendesE-SystemsseparatfürHEV/BEVbzw.erweiterbarfürPHEV";
CM_ SG_ 967 MO_Text_Motorstart "AnzeigetextefürStart/StoppundMotor-Start
0xB Fehler_Kupplungsschalter nur für PAG-MLB";
CM_ SG_ 967 MO_E_Texte "AnforderungvonHinweistextendesE-SystemsseparatfürHEV/BEVbzw.erweiterbarfürPHEV";
CM_ SG_ 967 WIV_Oeldyn_avl "ÖlstandausdynamischerMessungvorhanden";
CM_ SG_ 967 MO_Text_Partikelfil_Reg "ÜberdiesesBitimKombiwirdeinKlartextanzeigeerzeugtwerden:'PartikelfilterbenötigtRegeneration'.
";
CM_ SG_ 967 OLEV_Oelstand_nicht_vorhanden "KeinaktuellerÖlstandvorhanden";
CM_ SG_ 967 WIV_Oelmenge "ÖlmengezwischenMinundMax";
CM_ SG_ 967 MO_Systemlampe "EGasSystemlampe(EPC)oderVorglühlampeimKombi,Kombisteuertimmergleiche
LED an, nur über Ziffernblatt wird die EPC von der Vorglühlampe differenziert";
CM_ SG_ 967 MO_OBD2_Lampe "OBDbzw.MIL-LampewirdvomMotorsteuergerätangesteuert,dieInformationimSignalGE_OBD_StatuswirdvomMotorsteuergerätandasKombiweitergereicht";
CM_ SG_ 967 MO_Heissleuchte "AnsteuerungderKühlwassertemperatur-Heißleuchte(SensornurnochamMotorsteuergerät):TemperaturschaltschwellenmitHysterese(beiVWD1/ColoradoKombiderzeitnochnichtgenutzt).";
CM_ SG_ 967 MO_Partikel_Lampe "Partikelfilter-Lampewirdeingeschaltet";
CM_ SG_ 967 MO_RedFahrleistung_Lampe "AnsteuerungderTurtle-ModeLampefürE-TraktionFahrzeuge";
CM_ SG_ 967 WIV_Oelstand_nicht_vorhanden "KeinaktuellerÖlstandvorhanden";
CM_ SG_ 967 WIV_nachfuellanzeige_ein "SteuertdasAufblendenderNachfüllanzeigeimKombi,nachKlemme15einundgeöffneterMotorhaube";
CM_ SG_ 967 WIV_Ueberfuell_deaktiv "UnterdrückungderWarnungimKombidiedurchSignalWIV_Ueberfuel_Warnausgelöstwird";
CM_ SG_ 967 WIV_Unterfuell_Warn "ÖlstandhatdieUnterfüllschwelleunterschritten";
CM_ SG_ 967 MO_Tankdeckel_Lampe "AnsteuerungTankdeckel-WarnlampeKombiinstrument(nurOttomotoren)z.Zt.VorhaltVW";
CM_ SG_ 967 MO_Text_Tankdeckelwarn "TextbitderTankdeckelwarnung,z.Zt.VorhaltVW";
CM_ SG_ 967 MO_Vorglueh_Lampe "VorglühlampeimKombi,KombisteuertimmergleicheLEDan.
Mit Einführung des Einheits-Kombis sind getrennte Signalwege für Vorglühlampe und EPCL notwendig.";
CM_ SG_ 967 WIV_Oeldr_Warn_Motor "LöstimKombiinstrumentdierotePrio1-Öldruckwarnung(inkl.3xBeep)aus.
nur MLB: die Warnauslösung erfolgt nur bei gleichzeitig gesetztem 'WIV_Enable_Oeldr_Motor'";
CM_ SG_ 967 MO_E_Mode "AnforderungderE-ModeStatusanzeige";
CM_ SG_ 706 MO_Anzeige_StSt_Text "SteuertdieAnzeigederStSt-TexteimKombi";
CM_ SG_ 706 MO_Anzeige_StSt_Symbol "SteuertdieAnzeigederStSt-SymbolikimKombi";
CM_ SG_ 706 MO_ADR_Status "StatusderArbeitsdrehzahlregelung";
CM_ SG_ 706 MO_AGA_Sound_Texte "TextausgabedesaktuellenSound-ZustandesderAbgasklappensteuerung";
CM_ SG_ 706 MO_Anzeige_FMAus_Text "FehlerstatusdesFMAus-Systems(z.B.FehlerimZusatzspeicher)";
CM_ SG_ 706 PEA_Texte "StatusderFunktionPEA";
CM_ SG_ 706 TSK_Ueberstimmt_vMax_FahrerInfo "InformationueberdenZustandwanndievMax-LimitierungvomFahrerueberstimmtwird.";
CM_ SG_ 706 MO_Rekuperationsstufe "InProjektenmitvariablenoderanwählbarenRekuperationsstufensolldemFahrerdieaktuellausgewählteStufeübereinIconindenAnzeigeinstrumentenvisualisiertwerdenkönnen.DiesdientderNachvollziehbarkeitfürdenKundeninBezugaufeinezukünfti";
CM_ SG_ 706 TSK_Einheit_vMax_FahrerInfo "EinheitzuTSK_vMax_FahrerInfo.DasMSGspiegelthierKBI_MFA_v_EinheitundstelltdenAnzeigewertindieserEinheitzurVerfügung(keinzyklischesMux)";
CM_ SG_ 706 TSK_Status_vMax_FahrerInfo "StatusderTSK_vMax_FahrerInfozurSteuerungvonPopUps,Fahrzeugstatusundggf.einerLED.BeiWert0inTSK_vMax_FahrerinfosollaufeineunspezifischeBegrenzunghingewiesenwerden(z.B.wegenMomentenbegrenzung),beiallenanderenWertensolldiesera";
CM_ SG_ 706 MO_Anz_Kuehlerluefter "SignalbeiaktivemKühlerlüfternachlauf(Motoraus)imAllgemeinenfürdieAnzeigeimKombi-InstumentzurInformationdesKundenüberdiesenLüfterlauf";
CM_ SG_ 706 FDR_Warnung_ALR "WarnmeldungenderAllradverteilung";
CM_ SG_ 706 TSK_vMax_FahrerInfo "anzuzeigendeBegrenzungsgeschwindigkeitbeiaktiverHGB";
CM_ SG_ 267 Motor_51_CRC "FürMLB:
Berechnung siehe Lastenheft 'Kommunikationsabsicherung für FlexRay und CAN'
Ab MQB und MLBevo:
Berechnung siehe Lastenheft 'End-to-End Kommunikationsabsicherung'

Endwerte siehe Begleitdokument 'S-PDU Kennungsfolgen'";
CM_ SG_ 267 Motor_51_BZ "4bitBotschaftszähler,wirdmitjederSendebotschaftinkrementiert";
CM_ SG_ 267 MO_Fahrpedalrohwert_01 "AUDID4:Zykluszeit:10ms(sieheZykluszeitschnell/CycletimeFast)

Stellung des Fahrpedales (Rohwert, ohne Überlagerung durch GRA-Eingriffe etc.)

Die Funktionen zur Berechung des Fahrpedalrohwerts laufen im 10ms Raster. Der Fahrpedalwert berechnet ";
CM_ SG_ 267 MO_QBit_Fahrpedalwerte_01 "AUDID4:Zykluszeit:10ms(sieheZykluszeitschnell/CycletimeFast)

QBit für beide Fahrpedalwerte des Motors (Fahrpedalrohsignal für ESP, EPB, ACC; Fahrpedalwert für Getriebe)

Achtung:
Reduktion der Zykluszeit Motor_03 auf 10ms geplant.
Projektabh";
CM_ SG_ 267 MO_Fahrpedalgradient "DasMotorsteuergerätbesitzt2analogeFahrpedalsignale.DasSignaldeserstenKanalswirdalle4msabgetastet.UmBitschwankungendesA/D-WandlerherauszufilternwirddasSignalentjittert.AnschließendwirdderGradientberechnet.EntsprechendderZyklu";
CM_ SG_ 267 MO_Sig_Fahrpedalgradient "KennzeichnetdasVorzeichendesSignal'Fahrpedalgradient'.DieAusgabeerfolgtnurparallelstatischmitgesendetemSignal:'SteuerungsbitFahrpedalgradient'";
CM_ SG_ 267 MO_rel_Saugrohrdruck "DerWertgibtan,umwievielmbarderSaugrohrdruckunterhalbdesUmgebungsdrucksliegt.ÜberdruckimSaugrohrwirdnichtausgegeben.
0: Saugrohrdruck=Umgebungsdruck";
CM_ SG_ 267 MO_rel_Saugrohrdruck_gem_err "0:mind.eineModellrechnungwirdzurBerechnungdesrelativenSaugdrucksherangezogen
1: Relativer Saugrohrdruck wird ausschließlich über Messgrößen bestimmt";
CM_ SG_ 267 MO_Moment_im_Leerlauf "Fahrerwunschmomentistminimal:keineMomentenanforderungdurchFahrpedal,ACCoderGRA+;(DasSignalistunabhängigvonMomentenerhöhungendurchLeerlaufregleroderMSR).

AUDI D4: Zykluszeit: 10ms (siehe Zykluszeit schnell/Cycletime Fast)

Achtung:";
CM_ SG_ 267 MO_Schubabschaltung "ESPplausibilisiertUnterdrucksensornurbeiaktiverSchubabschaltung

MLBevo:
Signal wird nur in MLBevo Projekten mit PDKII Getriebe bedient. In allen anderen MLBevo Projekten wird das Signal mit '0' bedient
PDKII berücksichtigt Verzugszeiten, die in";
CM_ SG_ 267 MO_Solldrehz_Leerlauf "Leerlaufsolldrehzahl,dieimMotoreingestelltist(BeiParallelhybridimE-Fahr-BetriebLeerlaufsolldrehzahlderE-Maschine).DerMotorpaßtaufgrundderAnforderungvonanderenSteuergerätenseineLeerlaufsolldrehzahlan,bspw.Kat-Heizen,Anforderungv";
CM_ SG_ 267 MO_Entkopplung_Sollschlupf "MSGfordertvonGSGan,dasAnfahrelement(Fahr-/Wandlerkupplung)zuentkoppeln;dasGSGsolldiegesendeteDrehzahlalsSchlupfeinstellenundggf.dieRegler-Parameterumschalten,damitRuckeausdemAntriebnichtimFahrzeugspürbarwerden;nutzbarz.B";
CM_ SG_ 267 MO_temporaere_Fahrerabwesenheit "DasSignaldientzurSignalisierungeinertemporärenAbwesenheitdesFahrers.IndieserZeitistesihmmöglich,sichdurchgewisse¿imVerlassenskonzeptdefinierte¿FahreraktionenimaktuellenFahrzykluszurückzumelden.
Das Signal wird gesetzt, sobald";
CM_ SG_ 267 TSK_a_Soll_gradientenbegrenzt "TSKSollbeschleunigungfürFahrerassistenzsystememitaktiverLängsführung(GRA,ACC,IPA...).DerWertstelltdenruckbegrenztenSollwertderTSK-RegelungdarundistBasisderTSK-Antriebs-undBremsmomentenvorsteuerung.";
CM_ SG_ 267 TSK_Radbremsmom "BeiderSchnittstellevomTSKzumESPsollinFolgeprojektendesB8undinsbesonderebeiVW-ProjektendieAnsteuerungderBremsenichtüberSollbeschleunigungsondernBremsmomenterfolgen.EshandeltsichgenauerumdasSummenradbremsmoment,welchesdie";
CM_ SG_ 267 TSK_Status "BetriebszustanddesTSK-Reglers";
CM_ SG_ 267 TSK_v_Begrenzung_aktiv "LimiteroderHGBbegrenzendieBeschleunigung/dasMoment";
CM_ SG_ 267 TSK_Standby_Anf_ESP "MitdiesemBitwirddasaktiveBremssystemaufeineanstehendeTSK-Verzögerungsanforderungvorbereitet(ÜberfahrenLeerweg,AnlegenBremsbeläge)";
CM_ SG_ 267 TSK_Freig_WU "FreigabedesTSK_ÜbersetzungswunschesbeiACC/GRABetriebbergabfürdieVerstellungnachkurzbzw.RückschaltungimGetriebe.";
CM_ SG_ 267 TSK_Freig_Verzoeg_Anf "FreigabederVerzögerungsanforderungderACCoderggf.GRA+FunktionfürECDRegelungimESP";
CM_ SG_ 267 TSK_Limiter_ausgewaehlt "ACC/GRA-BetriebnurbeinichtausgewähltemLimitermöglich";
CM_ SG_ 267 TSK_Wunsch_Uebersetz "BeiACC/GRABetriebbergabteiltderTSKdemGetriebemit,dasseineDrehzahlerhöhungerwünschtist,ummehrSchleppmomentunddamitverbundendienötigeVerzögerungzuerzeugen,umdieGeschwindigkeitkonstantzuhalten.

Nutzung im VL: das Getriebe v";
CM_ SG_ 267 TSK_Hauptschalter_GRA_ACC "StellungdesGRA/ACCHauptschalters.DasSignalwirdauchbeiFehlerabschaltungenvonGRA/ACCweiterhinbedientundermöglichtfürACCdieSteuerungderACC-AnzeigeauchinFehlerfällen.";
CM_ SG_ 267 TSK_SRBM_Anf_ASIL "ASIL-LeveldesTSK-Anforderers,deraktuelleineBremsmomentenanforderungauslöst";
CM_ SG_ 267 TSK_ax_Getriebe_02 "BeschleunigungsanforderungdesBeschleunigungsreglers(u.a.fürACC,GRA,SpeedLimiter).DasSignalwirdvomGetriebebenutzt,umdievonGRA/ACCgeforderteSollbeschleunigungindemverbrauchsgünstigstenGangeinzustellen.
MQB: Im MQB wird die Sollbes";
CM_ SG_ 267 TSK_Zwangszusch_ESP "MitdiesemBitwirddasESP/ASRzwangsweiseaktiviert.BeigesetztemBitisteinausgetastetesESP(oderASR)wiederaktiviertbzw.wirddieAustastungverhindert.";
CM_ SG_ 267 TSK_zul_Regelabw "AnforderungderzulässigenRegelabweichungvomTriebstrangkoordinator.ZulässigerBetragderAbweichungzwischenangeforderter'TSK_Sollbeschleunigung_Getriebe'undumzusetzenderSollbeschleunigungimGetriebe.ImTSKwird,abhängigvomArbeitspunktdie";
CM_ SG_ 267 MO_Status_MinDrzEingriff "AktuelldrehzahlführenderAnfordererderMinimaldrehzahl(Begrenzungsregelung)desPulswechselrichtersderPrimärachse";
CM_ SG_ 267 MO_Status_MaxDrzEingriff "AktuelldrehzahlführenderAnfordererderMaximaldrehzahl(Begrenzungsregelung)desPulswechselrichtersderPrimärachse";
CM_ SG_ 267 MO_Status_MinDrzEingriff_sek "AktuelldrehzahlführenderAnfordererderMinimaldrehzahl(Begrenzungsregelung)desPulswechselrichtersderSekundärachse";
CM_ SG_ 267 MO_Status_MaxDrzEingriff_sek "AktuelldrehzahlführenderAnfordererderMaximaldrehzahl(Begrenzungsregelung)desPulswechselrichtersderSekundärachse";
CM_ SG_ 267 GRA_KuFu_aktiv "StatusderKundenfunktionGeschwindigkeitsregelanlagefürVMM1.0";
CM_ SG_ 267 TSK_SRBM_max_Gradient "IndiesemSignalwirddervomTSKmaximalgeforderteSummenRadBremsMomentengradientgesendet,dervonderBremsebeiderUmsetzungderTSK-Verzögerungnichtüberschrittenwerdendarf.";
CM_ SG_ 267 LIM_KuFu_aktiv "StatusderKundenfunktionbedienbarerSpeedLimiterfürVMM1.0";
CM_ SG_ 330 MO_Hochschaltdrehz "HochschaltdrehzahlbeimanuellemGangwechselüberLenkradTip-UpoderGangwahlhebelfallsdieserinTippgasse.
Nur AUDI RS-Modelle!";
CM_ SG_ 330 MO_Anzeige_Verbr_Einheit "SignalstehtimKontextMO_Anzeige_VerbrauchundüberträgtdieVerbrauchseinheitderaktuellenAntriebsart.SignalmussindergleichenBotschaftwieMO_Anzeige_Verbrauchübertragenwerden";
CM_ SG_ 330 MO_Schaltblitz_Anz "SignalisierungderdrehzahlabhängigenSchaltblitzanzeigeimKombiinstrument(0-100%)";
CM_ SG_ 330 MO_Anzeige_Drehmoment "DrehmomentssignalfürSport-HMIimKombi.";
CM_ SG_ 330 MO_Anzeige_Leistung "LeistungssignalfürSport-HMIimKombi.";
CM_ SG_ 330 MO_rel_Ladedruck "relativerLadedruck(fürBoostanzeige)";
CM_ SG_ 330 MO_Istgang "AktuellerGangfürAnzeigeHochschaltempfehlung(gültig,wennMO_Schaltempf_verfbar=1).

Anzeige im Kombi:
Sollgang == Istgang         ==> Anzeige Istgang
Sollgang !=   Istgang         ==> Schaltempfehlung
Sollgang == Istgang == 0 ==> keine Anzeige";
CM_ SG_ 330 MO_Sollgang "MotorsendetdenSollgangindenderFahrerschaltensoll.WirdimKombialsHochschaltempfehlunghervorgehoben(gültig,wennMO_Schaltempf_verfbar=1).

Anzeige im Kombi:
Sollgang == Istgang          ==> Anzeige Istgang
Sollgang !=  Istgang         ";
CM_ SG_ 330 MO_Oeldruck "ÖldruckanalogzurAnzeige";
CM_ SG_ 330 MO_Anzeigedrehz "OptimierteAnzeigedrehzahlwegensportlicheremDrehzahlmesserimKombi.
Bei Parallelhybrid: Anzeige VKM- Drehzahl nach Anzeigekonzept

Hinweis: Ehemaliger Fehlerwert 0xFFF wird senderseitig nicht unterstützt. Diesen Wert aus Kompatibilitätsgründen nic";
CM_ SG_ 330 MO_Effizienzmodus "BeiHandschalternwirddasFahrprogrammEffizienzsignalisiert.
Bei Automatikgetrieben wird das Fahrprogramm 'D' durch 'E' ersetzt.";
CM_ SG_ 330 MO_Fehler_Oeldrucksensor "SteuertimKombiinstrumentdiegelbezentraleWarnlampeunddasSymbol'gelbeÖlkanne'mitderTextmeldung'Sensorfehler:Werkstattaufsuchen'an
";
CM_ SG_ 330 MO_Schaltempf_verfbar "Info,obSchaltempfehlungimFzg.verfügbar.StatischerWert,ändertsichfüreinFzg.nicht!";
CM_ SG_ 330 MO_Ladedruck "absoluterLadedruck";
CM_ SG_ 330 MO_KVS "MotorsteuergerätinternerVerbrauchszähler,dervomKombizyklischausgelesenwird,umdieEinspritzmengezurVerbrauchsmessungaufzusummieren;ausdiesemZählerstandwerdenMomentan-undDurchschnittsverbrauchberechnet;dasÜberlauf-Bitistzuberücksich";
CM_ SG_ 330 MO_KVS_Ueberlauf "DermotorsteuergeräteinterneVerbrauchszähleristmindestenseinmalübergelaufen.DiesesBitwirdgenutzt,umerkennenzukönnen,daßdasMotorsteuergerätausdemReset-Zustandhochläuft.";
CM_ SG_ 330 MO_ePowermeter "AnzeigeePowermeter(FahrreserveelektrischbisStartVerbrennungsmotor(Verbrennerstartetbei100%))";
CM_ SG_ 330 MO_ePerformance "ZeigtdieelektrischeLeistungreservebeiBEVundPHEVProjektenan.
Bei Init und Fehler soll keine Anzeige erfolgen. ";
CM_ SG_ 330 MO_Zust_Antrieb "SignalisiertdieZuordnungderAntriebsverbräuchezudenAntriebsmaschinenfürdieRestreichweitenberechnung,nichtgleichbedeutendmitMotorlaufEModerVM";
CM_ SG_ 330 MO_Zust_Betriebsstrategie "SignalisiertdenaktuellenZustandderBetriebsstrategie";
CM_ SG_ 330 Ladezustand_02 "AktuellerrelativerLadezustandderHV-Batterie
";
CM_ SG_ 330 MO_Powermeter_Elm_02 "relativesMoment/relativeLeistungderelektrischenMaschine";
CM_ SG_ 330 MO_Powermeter "AnzeigewerteimKombi
0       = Unteres Ende Bremsen/gra";
CM_ SG_ 512 TSK_Wunschgeschw "ZurAnzeigederWunschgeschwindigkeitvonGRA/SpeedlimiterimKombiinstrument";
CM_ SG_ 512 TSK_praediktiver_Hinweis "AnzeigesteuerungobGeschwindigkeitshinweisalsVorschlag(zurÜbernahme)oderalsHinweis(beiautomatischerÜbernahme)behandeltwerdensoll";
CM_ SG_ 512 TSK_naechstes_Event "AnzeigedesnaechstenStreckenereignisses,welchesinderPGRA-PLIMRegelungeineÄnderungderZielgeschwindigkeitzurFolgehat";
CM_ SG_ 512 TSK_Fahrzeugstatus_praed_Fkt "ZeigtdenStatusderPrädiktionderKundenfunktionenP_LIMundP_GRAan";
CM_ SG_ 512 TSK_Texte "TextmeldungendesTSKzurDarstellungimKombi";
CM_ SG_ 512 TSK_Akustik "AnforderungzurAusgabeAkustischerMeldungendesTriebstrangkoordinators";
CM_ SG_ 512 TSK_Texte_Primaeranz "TriggerfürAnzeigetextevonGRAundLimiter,GRATemporäranzeige(Audi)undLimiterWarnungen

0 keine Anzeige
1 GRA Symbol passiv xxx km/h / mph (nur Audi)
2 GRA Symbol aktiv xxx km/h / mph (nur Audi)
3 Bremse überhitzt ! (reserv.)
4 Limiter Modu";
CM_ SG_ 512 TSK_Limiter_Fahrerinfo "FahrerhinweiseundWarnungendesSpeedlimiters";
CM_ SG_ 512 TSK_Limiter_Anzeige "SignalisiertdenWunschdesMSGandasKombiinstrument,seineAnzeigeaufLimiterumzuschalten";
CM_ SG_ 512 TSK_Fahrzeugstatus_GRA "ZurAnzeigederNicht-VerfuegbarkeitdesGeschwindigkeitsregelanlageimFahrzeugstatus";
CM_ SG_ 512 TSK_Fahrzeugstatus_Limiter "ZurAnzeigederNicht-VerfuegbarkeitdesSpeedlimitersimFahrzeugstatus";
CM_ SG_ 512 MO_Motorlaufwarnung "SignalzurAnforderungder'Motorlaufwarnung'imKombi.";
CM_ SG_ 512 TSK_naechstes_Event_Einheit "DasSignalzeigtaninwelcherEinheitderHinweisanzuzeigenist.Bspw.SchilderinmphundAnzeigeinKm/h";
CM_ SG_ 512 TSK_Status_Anzeige "SignalisiertdenStatusvonGRAoderLimiterzurAnzeigeimKombiinstrument.
Der Signalwert 'Limitierung_aktiv' wird nur verwendet für den Audi Speedlimiter und zeigt bei aktivier Funktion an, dass nahe an der Abregelgeschwindigkeit gefahren wird und die";
CM_ SG_ 512 MO_Sperrung_FahrPr_BZS "SperrungeinzelnerBetriebszuständebzgl.KommunikationzwischenMotor-SGundCharisma-SG(Gateway)";
CM_ SG_ 512 MO_Rampenzeit_Generator_Anf "DasMotorsteuergerätkanneineLoad-Response-ZeitdesGeneratorsvomNiedervoltenergiemanagement(NVEM)anfordern.DieLoad-Response-ZeitwirdvomNVEMumgesetzt,wenndiesbordnetzverträglichmöglichist.";
CM_ SG_ 512 MO_Prio_MAX_Wunschdrehzahl "PrioritätsbitderMotorwunschdrehzahlalsMAX";
CM_ SG_ 512 MO_Prio_MIN_Wunschdrehzahl "PrioritätsbitderMotorwunschdrehzahlalsMIN";
CM_ SG_ 512 MO_Luftpfad_aktiv "GetriebeeingriffwirdzusätzlichzumZündungspfadauchüberdenLuftpfadumgesetzt,kommtzuMLBneuindiePL48-Getriebe";
CM_ SG_ 512 MO_v_Begrenz_Aktivierbar "FehlerbitwirdvomMotor-SGgesetzt,wenndiesesnichtindieGeschwindigkeits-begrenzunggehenkann,einFehlerwährendderv-Begrenzungauftrittoderv>v_Begrenzung-v_Delta";
CM_ SG_ 512 MO_Drehzahlbeeinflussung "FaktorzurAnhebungderFahrdrehzahlimWarmlauf";
CM_ SG_ 512 MO_MIN_Wunschdrehzahl "minimaleMotorwunschdrehzahlaufgrundRegeneration,dievomGetriebenichtunterschrittenwerdendarf

Hinweis:
Ehemaliger Fehlerwert 0xFF wird senderseitig nicht unterstützt.
Diesen Wert aus Kompatibilitätsgründen nicht neu belegen!";
CM_ SG_ 512 MO_MAX_Wunschdrehzahl "maximaleMotorwunschdrehzahl,dievomGetriebenichtüberschrittenwerdendarf

Signal darf GE_Synchro_Wunschdrehzahl nicht spiegeln";
CM_ SG_ 512 MO_Charisma_FahrPr "MLBevo:AktuellesFahrprogrammdesCharisma-Teilnehmers(sieheSystemlastenheftDriveSelect)
MQB: Istwert der Kennlinie (siehe Systemlastenheft MQB FPA)";
CM_ SG_ 512 MO_Charisma_Status "CharismaSystemstatusdesCharisma-Teilnehmers

Wert 0x3 ist nur für Fahrzeuge ab MQB relevant";
CM_ SG_ 512 MO_StSt_Charisma_FahrPr "MLBevo:AktuellesFahrprogrammdesCharisma-Teilnehmers(sieheSystemlastenheftDriveSelect)
MQB: Istwert der Kennlinie (siehe Systemlastenheft MQB FPA)";
CM_ SG_ 512 MO_StSt_Charisma_Status "CharismaSystemstatusdesCharisma-Teilnehmers

Wert 0x3 ist nur für Fahrzeuge ab MQB relevant";
CM_ SG_ 512 MO_BZS_Charisma_FahrPr "RückmeldungdesaktuellenCharisma-FahrprogrammsderMSGBetriebsstrategie

MLBevo: Aktuelles Fahrprogramm des Charisma-Teilnehmers (siehe Systemlastenheft Drive Select)
MQB: Istwert der Kennlinie (siehe Systemlastenheft MQB FPA)";
CM_ SG_ 512 MO_BZS_Charisma_Status "CharismaSystemstatusdesCharisma-TeilnehmersMSG(Betriebszustände)

Wert 0x3 ist nur für Fahrzeuge ab MQB relevant";
CM_ SG_ 512 MO_NGS_Position "MesswertdesNeutralgangsensors
(nur Handschalter)";
CM_ SG_ 512 MO_NGS_Status "StatusdesSignalsMO_NGS_Position.DasMSGprüftdiePlausibilitätnurhinsichtlichsichergeöffnetemTriebstrang.";
CM_ SG_ 512 MO_v_Begrenzung_Niveau "Zeigtan,obeinev-BegrenzungaufgrundAnforderungderNiveauregelungimMSGaktivistodernicht(SignalfürNiveauzumSteuernderKombianzeige).";
CM_ SG_ 512 MO_Anzeige_Rekuperation "SignalstehtimKontextzuMO_Anzeige_VerbrauchundwirdfürdieAnzeigedesReku-BereichesimgrafischenMomentanverbrauchverwendet";
CM_ SG_ 512 PEA_Fortschrittsanzeige "AblaufbalkenfürPEA-Hinweise";
CM_ SG_ 512 MO_Anzeige_Fahrbereitschaft "SignalisiertdauerhaftandasKombi,obdieFahrbereitschaftvorhandenist(DrehzahlmesseraufREADY)";
CM_ SG_ 512 MO_Boost_verfuegbar "AnzeigedesaktuellverfügbarenBoostpotentialsimKombiinstrument.";
CM_ SG_ 512 MO_Overboost "NurTurbo.AnzeigeeinesOverboostpfeilsimKombiwährendOverboostzustandderLadedruckregelung.";
CM_ SG_ 512 MO_Boost_aktiv "AnzeigeimKombiobBoostaktivist.
Die Anzeige wird zusätzlich über das Signal MO_Boost_verfuegbar gesteuert.
";
CM_ SG_ 512 MO_Anzeige_Betriebsmodus "InfoandasKombizurAnzeigeverschiedenerBetriebsmodi";
CM_ SG_ 512 PEA_Hinweis "AufforderungfürFahrerhandlungdurchPEA";
CM_ SG_ 512 PEA_Ereignisanzeige "DasSignaldientderAnzeigedesHinweisgrundes";
CM_ SG_ 512 PEA_Ereignisanzeige_temporaer "SignaldientzurSteuerungeinerTPAAnzeigeimKombi";
CM_ SG_ 512 PEA_Abschalttexte "DasSignaldientdemAnzeigenvonAbschalttexten,wennPEAnichtverfügbarist";
CM_ SG_ 512 PEA_Zielgeschw_Einheit "EinheitderanzuzeigendenZielgeschwindigkeitfürPEA(PrädiktiverEffizienzAssistent)";
CM_ SG_ 512 PEA_Zielgeschw "DasSignaldientderAnzeigeeinerGeschwindigkeiteinesGeschwindigkeitsereignissesfürPEA";
CM_ SG_ 512 MO_Antriebsstrang_Warnung_HS "StatusderFehlerlampen-AnsteuerungundTextausgabefürFehlerspeichereinträgeausderKupplungsschutz-FunktionfürHandschaltgetriebe.";
CM_ SG_ 512 MO_Anzeige_Verbrauch_oE "AnzeigeVerbrauchssignalfürsKombi.ImBezugaufVerbrennerbeteiligung.DasSignalisteinheitenlos.DiezugehörigeEinheitwirdinMO_Anzeige_Verbr_Einheitübertragen.";
CM_ SG_ 332 MO_Anforderung_HMS "HalteanforderungvomMotoranHMS";
CM_ SG_ 332 FoD_DTC_TSK_GRA "DTCistentwederbereitseingetragenoderwirdeingetragen,sobalddiezugehörigeFoDFunktionfreigeschaltetwird.";
CM_ SG_ 332 TSK_vMax_aktuell "ImaktuellenBetriebszustandglobalgültigeGeschwindigkeitslimitierung.";
CM_ SG_ 332 TSK_Status_EA "FunktionsstatusdesTriebstrangkoordinatorsfürdenAnfordererEmergencyAssist";
CM_ SG_ 332 FoD_DTC_TSK_ACC "DTCistentwederbereitseingetragenoderwirdeingetragen,sobalddiezugehörigeFODFunktionfreigeschaltetwird.";
CM_ SG_ 332 TSK_ACC_FoD_Status "Information,obdieTSK-ACC-Funktionfreigeschaltetistodernicht.";
CM_ SG_ 332 TSK_GRA_FoD_Status "Information,obdieTSK-GRA-Funktionfreigeschaltetistodernicht.";
CM_ SG_ 332 TSK_vMax_Fahrerassistenz "maximaleSollgeschwindigkeitfürGRA/ACC/Limiter
Hinweis: Signal ist mit Signal TSK_Einheit_vMax_Fahrerassistenz zu interpretieren.  Das Signal wird abwechselnd in km/h und mph gesendet.";
CM_ SG_ 332 TSK_Einheit_vMax_Fahrerassistenz "EinheitzuSignalTSK_vMax_Fahrerassistenz";
CM_ SG_ 332 TSK_Status_PLA "FunktionsstatusdesTriebstrangkoordinatorsfürdenSpeedlimiterdesParkassistenten";
CM_ SG_ 332 TSK_aktives_System "AnzeigederinderTSK-LängsführungaktivenFunktion";
CM_ SG_ 332 TSK_erhoehter_Fahrwiderstand "RueckmeldungvomTriebstrangkoordinator,dasseinegroßeReglerdifferenzdetektiertwurde.Sollermoeglichen,einenggfs.unbekanntenFahrwiderstandamBodenzuerkennen.";
CM_ SG_ 332 TSK_Anf_Antriebsmoment "DasSignalzeigtan,obdieTSK-LaengsregelungaktuellAntriebsmomentanfordert,zurVerwendunginderASR/EDS-Funktion";
CM_ SG_ 332 TSK_Status_ARA "FunktionsstatusdesTriebstrangkoordinatorsfürdenAnhängerrangierassistenten";
CM_ SG_ 332 TSK_Status_IPA "FunktionsstatusdesTriebstrangkoordinatorsfürdieLängsführungdesEinparkassistenten";
CM_ SG_ 332 MO_Fahrbereitschaft "DasSignalMO_FahrbereitschaftzeigtinmehrerenStufenan,obderMotorineinemanfahrbereitenZustandist.";
CM_ SG_ 332 MO_Freilauf_Info "FreilaufInformationssignalvomMotorsteuergerätzumGetriebesteuergerät.DasMotorsteuergerätkannüberdiesesSignaldenFreilauffreigeben,verhindernbzw.explizitanfordern.";
CM_ SG_ 332 MO_Krit_Heckobjekt "BeschreibtdieKritikalitätdeshintereineminderSpurfahrendenFahrzeuges";
CM_ SG_ 332 MO_NGS_Gangpos "Gang-bzw.NeutralinformationdeserweitertenNeutralgangsensors.BedingtdurchdeneingeschränktenErfassungssbereichdesSensorssinddieGanginformationenalseingelegtbzw.fasteingelegt/vorausgewähltzuinterpretieren(nurHandschalter)";
CM_ SG_ 332 MO_Freilauf_Status "Freilauf-Status-SignalvomFrailauf-MasteranaktiveFreilauf-Teilnehmer.IndiesemSignalzeigtderFreilauf-Masteran,welchenaktuellenStatusdieFreilauf-Betriebsstrategiehat.";
CM_ SG_ 332 MO_EBoost_verf_praed "Zeigtan,obfüreineimProjektdefinierteZeit(max.10s)E-BoostinHöhevonEM1_maxPred_Momentverfügbarseinwird.

0 - Init_oder_nicht_verfügbar
1 - EBoost_kurzzeit_verfügbar (~3Sek.)
2 - EBoost_langzeit_verfügbar (~10Sek)";
CM_ SG_ 332 MO_Heckspoiler_Anf "AnforderungdenHeckspoilerzurLadeluft-bzw.Motorraumkühlungauszufahren.";
CM_ SG_ 332 MO_eLaunch_verf "Zeigtan,obausAntriebssichtE-Launchverfügbarist.";
CM_ SG_ 332 MO_Positionierung_aktiv "Zeigtan,dassdieMotorpositionierungmitHilfedesRiemenstartergeneratormomentanaktivist.";
CM_ SG_ 332 MO_Freilauf_Typ "BeschreibtdievomMSGunterstützteFreilauffunktionalität:
Koordinator GSG = Freilauf nur in Eco
Koordinator GSG mit FP-Grad = Freilauf 'Default on', GSG kann Freilauf auch in D und in Abhängigkeit des Fahrpedalgradienten steuern
Koordinator MSG = Fr";
CM_ SG_ 332 MO_Startwunsch "o	SetzenbeiErfüllungderkomplettenFahrerbedienhandlung(z.B.Zündanlasstaster+Bremse+FahrstufeP/N[klassisch]oderFahrstufeD/R+Bremse[MEB]),jenachFahrzeugz.T.bereitsvoroderimmererstnachEinschaltenderKlemme1";
CM_ SG_ 332 OBD_Calc_Load_Val "CalculatedLoadValue

Übertragung von Meßgrößen an das Getriebesteuergerät für Freeze Frame Abspeicherung bei Getriebefehlern

PID $04 Calculated Load Value; 0 .. 100% mit 100/255 % per bit
";
CM_ SG_ 332 OBD_Eng_Cool_Temp "EngineCoolantTemperature

Übertragung von Meßgrößen an das Getriebesteuergerät für Freeze Frame Abspeicherung bei Getriebefehlern

PID $05 Engine Coolant Temperature; -40 .. +215°C mit 1°C/bit und 40°C Offset";
CM_ SG_ 332 OBD_Abs_Throttle_Pos "AbsoluteThrottlePosition

Übertragung von Meßgrößen an das Getriebesteuergerät für Freeze Frame Abspeicherung bei Getriebefehlern

PID $11 Absolute Throttle Position; 0 .. 100% mit 100/255 %/bit";
CM_ SG_ 332 OBD_Abs_Load_Val "AbsoluteLoadValue

Übertragung von Meßgrößen an das Getriebesteuergerät für Freeze Frame Abspeicherung bei Getriebefehlern

PID $43 Absolute Load Value; 0 .. 25700%  mit 100/255 %/bit";
CM_ SG_ 332 OBD_Abs_Pedal_Pos "AbsolutePedalPosition

Übertragung von Meßgrößen an das Getriebesteuergerät für Freeze Frame Abspeicherung bei Getriebefehlern

PID $49 Accelerator Pedal Position D; 0 .. 100% mit 100/255 %/bit";
CM_ SG_ 332 MO_Servicemodus "AusgabeaktiverService-Mode";
CM_ SG_ 332 OBD_ClearMem_Inhibit "DasFehlerspeicherlöschensollnurnochbeistehendemFahrzeugüberService-04hexausgeführtwerden,dafürwirdvomMIL-MastereinCANSignalbenötigt,dasdasLöschenunterbestimmtenRandbedingungennichtzulässigist";
CM_ SG_ 332 OBD_Sperrung_Kaltstart_Denom "InformationvomMILMaster,dassdieBildungdesEVAPDenominatorsimMotornichtmöglichistunddamitdernoECM-Denominatorgesperrtwerdendarf.";
CM_ SG_ 332 MO_QBit_Aussen_Temp "QBitderAussentemperatur.GesetztbeiErsatzwert,InitoderFehler.";
CM_ SG_ 332 OBD_Sperrung_IUMPR "WennderGeneralDenominatoraufGrundeinesFehlersindenEingangsgrößengesperrtwird,wirddieseInformationüberBussystemalsOBD-StatusinformationOBD_Sperrung_IUMPRfürandereOBD-Steuergerätebereitgestellt.

Das MSG (MIL-Master) setzt dieses ";
CM_ SG_ 332 OBD_Kaltstart_Denominator "BestimmteDiagnosenwerdennurunterKaltstartbedingungendurchgeführt,derentsprechendeDenominatorbeiIUMPR-pflichtigenSystemenwirdanhanddiesesvomMSGgebildetenSignalsinkrementiert.(EntsprichtEVAP-Denominator)";
CM_ SG_ 332 OBD_Minimum_Trip "GrundlageOBD-GesetzCCR1968.2(d)(4.3)DenominatorSpecifications
Bildung des General Denominator 'Normed Trip':
600 sec. (kumulativ) Zeit nach Motorstart
300 sec. (kumulativ) mit Fahrzeuggeschwindigkeit > 25 mph (40 km/h)
30 sec. (kontinuierlich";
CM_ SG_ 332 OBD_Warm_Up_Cycle "MitdemWarm-Up-CyclewirdderzentraleVerlernzählervomGatewayinkrementiert";
CM_ SG_ 332 OBD_Normed_Trip "Gesetzlichdefinierte'NormedCondition'erfüllt,'GeneralDenominator'darferhöhtwerden";
CM_ SG_ 332 OBD_Aussen_Temp_gef "GefilterteAussentemperaturvomMotorfürOBDFunktionen.";
CM_ SG_ 246 Motor_55_CRC "FürMLB:
Berechnung siehe Lastenheft 'Kommunikationsabsicherung für FlexRay und CAN'
Ab MQB und MLBevo:
Berechnung siehe Lastenheft 'End-to-End Kommunikationsabsicherung'

Endwerte siehe Begleitdokument 'S-PDU Kennungsfolgen'";
CM_ SG_ 246 Motor_55_BZ "4bitBotschaftszähler,wirdmitjederSendebotschaftinkrementiert";
CM_ SG_ 246 TS_Faktor_Radmomente "SchaltetdenWertebereichvonRad-Momenten-SignalediverserSGum,sodasszumeinendiemax.möglichenWerteübertragenwerdenkönnenundzumanderendieAuflösungmöglichsthochist.
Faktor ist über Laufzeit konstant, variiert nur zwischen Fahrzeug-Pro";
CM_ SG_ 246 TS_Status_MomRad_Ist "QualitätsstatuszuTS_MomRad_IstundTS_MomRad_Ist_Sek
Qualifiziert bei antriebstechnisch getrennten Achsen sowohl das Moment der primären Achse als auch das Moment der sekundären Achse, und bei mechanischem Allradantrieb das Gesamtmoment für beide Achse";
CM_ SG_ 246 TS_MomRad_verfuegb_maxReku_Summe "ImaktuellenBetriebszustandkurzfristig(ca.100..200ms)verfügbaresmax.negativesSummenmoment;definiertaufBezugsebeneRad.
Faktor in TS_Faktor_Radmomente beachten!";
CM_ SG_ 246 TS_MomRad_Ist "Gesamt-IstmomentderAntriebsmaschinen,umgerechnetaufRadebene,unterBerücksichtigungderMassenträgheitenderAntriebsmaschinenunddesGetriebes,unterBerücksichtigungderVerlustederAntriebsmaschinen,derNebenaggregateunddesGetriebes(d.h.ke";
CM_ SG_ 246 TS_MomRad_Soll_Summe "FaktorinTS_Faktor_Radmomentebeachten!

Momentenanforderung aus Fahrpedal bzw. von ACC/GRA bzw. aus dem Leerlaufregler (quasistatischer Anteil); keine Begrenzungen, keine Fahrverhaltensformung, keine Abbildung externer Eingriffsanforderungen; definier";
CM_ SG_ 246 TS_MomRad_Wunsch "FaktorinTS_Faktor_Radmomentebeachten!

Wunsch-Moment nach MSG-Betriebs-Strategie-Aufteilung und Umverteilung der Achs-Aufteilung durch EF; nach Lastschlagdämpfung der jeweiligen Achse; incl. Deckelung aufgrund von Schutz-Eingriffen, ohne Berücksichti";
CM_ SG_ 246 TS_MomRad_Wunsch_sek "FaktorinTS_Faktor_Radmomentebeachten!

Wunsch-Moment nach MSG-Betriebs-Strategie-Aufteilung und Umverteilung der Achs-Aufteilung durch EF; nach Lastschlagdämpfung der jeweiligen Achse; incl. Deckelung aufgrund von Schutz-Eingriffen, ohne Berücksichti";
CM_ SG_ 246 TS_MomRad_verfuegb_max "FaktorinTS_Faktor_Radmomentebeachten!

In aktuellem Betriebszustand (u.a. Übersetzung) kurzfristig (ca. 100..200 ms) verfügbares max. positives Momen";
CM_ SG_ 246 TS_MomRad_verfuegb_max_sek "FaktorinTS_Faktor_Radmomentebeachten!

In aktuellem Betriebszustand (u.a. Übersetzung) kurzfristig (ca. 100..200 ms) verfügbares max. positives Momen";
CM_ SG_ 246 TS_MomRad_verfuegb_maxReku "FaktorinTS_Faktor_Radmomentebeachten!

In aktuellem Betriebszustand (u.a. Übersetzung) kurzfristig (ca. 100..200 ms) verfügbares max. negatives Momen";
CM_ SG_ 246 TS_MomRad_verfuegb_maxReku_sek "FaktorinTS_Faktor_Radmomentebeachten!

In aktuellem Betriebszustand (u.a. Übersetzung) kurzfristig (ca. 100..200 ms) verfügbares max. negatives Momen";
CM_ SG_ 246 TS_MomRad_Ist_sek "Gesamt-IstmomentderAntriebsmaschinen,umgerechnetaufRadebene,unterBerücksichtigungderMassenträgheitenderAntriebsmaschinenunddesGetriebes,unterBerücksichtigungderVerlustederAntriebsmaschinen,derNebenaggregateunddesGetriebes.
Zeigt ";
CM_ SG_ 246 TS_Allrad_Anteil_sek "VomAntriebgewünschterprozentualerAnteildersekundärenAntriebsachseamGesamtmoment";
CM_ SG_ 246 FDR_Allrad_Anteil_max_sek "MaximalerprozentualerAnteildersekundärenAntriebsachseamGesamtmoment-wirdsoweitdiesdurchdieLeistungsfähigkeitderAchsemöglichisteingehalten";
CM_ SG_ 246 FDR_Allrad_Anteil_min_sek "MinimalerprozentualerAnteildersekundärenAntriebsachseamGesamtmoment-wirdsoweitdiesdurchdieLeistungsfähigkeitderAchsemöglichisteingehalten";
CM_ SG_ 246 FDR_MomRad_Eingriff "maximalzulässigesMomentprimäreAntriebsachse";
CM_ SG_ 246 FDR_Status_Eingriff "EingriffprimäreAntriebsachseaktiv";
CM_ SG_ 246 FDR_MomRad_Eingriff_sek "maximalzulässigesMomentsekundäreAntriebsachse";
CM_ SG_ 246 FDR_Status_Eingriff_sek "EingriffsekundäreAntriebsachseaktiv";
CM_ SG_ 190 Motor_56_CRC "FürMLB:
Berechnung siehe Lastenheft 'Kommunikationsabsicherung für FlexRay und CAN'
Ab MQB und MLBevo:
Berechnung siehe Lastenheft 'End-to-End Kommunikationsabsicherung'

Endwerte siehe Begleitdokument 'S-PDU Kennungsfolgen'";
CM_ SG_ 190 Motor_56_BZ "4bitBotschaftszähler,wirdmitjederSendebotschaftinkrementiert";
CM_ SG_ 190 MO_EM1_MinDrehzahl "MinimaleE-Maschinen-Drehzahl";
CM_ SG_ 190 MO_EM1_MaxDrehzahl "MaximaleE-Maschinen-Drehzahl";
CM_ SG_ 190 MO_EM1_DynLimit_AR "AuslöseschwellefürdynamischeRuckeldämpfung

Der Momentenwert ergibt sich aus der Multiplikation mit dem Faktor MO_EM1_Faktor_AR_Momente (Skalierung Wertebereich und Auflösung).";
CM_ SG_ 190 MO_EM1_Periode_AR "Zeitkonstante(Periodendauer)derRuckelschwingung(abhängigvomGangundggf.elektrischem/hybridischemFahren)";
CM_ SG_ 190 MO_EM1_SollMoment "E-MaschinenSoll-MomentvomHybridcontroller";
CM_ SG_ 190 MO_EM1_Sollmodus "Werte:
Anforderung der Betriebsart der E-Maschine
0: Standby; Kommunikation aktiv; aktiver Kurzschluss
1: Momentenregelung
2: Drehzahlregelung (interner Regelkreis)
3: Spannungsregelung
4: Drehzahlregelung (externer Regelkreis)
5: nicht verfügbar";
CM_ SG_ 190 MO_EM1_Min_Leistung "zugeteilteelektrischeLeistungfürdengeneratorischenBetrieb(betragsmäßigmaximalaberi.d.R.negativ,daher‚Min‘);;elektrischeLeistungzurBerechnungeinesmomentanmöglichenminimalenMomentsundeinermomentanmöglichenminimalenmechanischenLe";
CM_ SG_ 190 MO_EM1_Max_Leistung "zugeteilteelektrischeLeistungfürdenmotorischenBetrieb;elektrischeLeistungzurBerechnungeinesmomentanmöglichenmaximalenMomentsundeinermomentanmöglichenmaximalenmechanischenLeistung";
CM_ SG_ 190 MO_EM1_Min_Strom_Lim "minimalzulässigerHV-Strom,dervonderLEimgeneratorischenBetriebabgegebenwerdendarf(betragsmäßigmaximalaberi.d.R.negativ,daher‚Min‘);AbregelstromzurBegrenzungdesminimalenMomentsimgeneratorischenBetrieb";
CM_ SG_ 190 MO_EM1_Max_Strom_Lim "maximalzulässigerHV-Strom,dervonderLEimmotorischenBetriebaufgenommenwerdendarf;AbregelstromzurBegrenzungdesmaximalenMomentsimmotorischenBetrieb";
CM_ SG_ 190 MO_EM1_AR_Anf "AnforderungderAnti-RuckelFunktionaufderE-Maschine

0: aus
1: nicht belegt
2: D2T2 Regelung
3: Referenzdrehzahl Regelung
4: interne Referenzdrehzahlregelung";
CM_ SG_ 190 MO_EM1_Kp_AR "dynamischerVerstärkungsfaktorzurUmrechnungDrehzahlschwingunginEingriffsmoment";
CM_ SG_ 190 MO_EM1_SollSpannung "E-MaschinenSoll-Spannung";
CM_ SG_ 190 MO_EM2_MinDrehzahl "MinimaleE-Maschinen-Drehzahl";
CM_ SG_ 190 MO_EM2_MaxDrehzahl "MaximaleE-Maschinen-Drehzahl";
CM_ SG_ 190 MO_EM2_DynLimit_AR "AuslöseschwellefürdynamischeRuckeldämpfung

Der Momentenwert ergibt sich aus der Multiplikation mit dem Faktor MO_EM2_Faktor_AR_Momente (Skalierung Wertebereich und Auflösung).";
CM_ SG_ 190 MO_EM2_Periode_AR "Zeitkonstante(Periodendauer)derRuckelschwingung(abhängigvomGangundggf.elektrischem/hybridischemFahren)";
CM_ SG_ 190 MO_EM2_SollMoment "E-MaschinenSoll-MomentvomHybridcontroller";
CM_ SG_ 190 MO_EM2_Sollmodus "Werte:
Anforderung der Betriebsart der E-Maschine
0: Standby; Kommunikation aktiv; aktiver Kurzschluss
1: Momentenregelung
2: Drehzahlregelung (interner Regelkreis)
3: Spannungsregelung
4: Drehzahlregelung (externer Regelkreis)
5: nicht verfügbar";
CM_ SG_ 190 MO_EM2_Min_Leistung "zugeteilteelektrischeLeistungfürdengeneratorischenBetrieb(betragsmäßigmaximalaberi.d.R.negativ,daher‚Min‘);;elektrischeLeistungzurBerechnungeinesmomentanmöglichenminimalenMomentsundeinermomentanmöglichenminimalenmechanischenLe";
CM_ SG_ 190 MO_EM2_Max_Leistung "zugeteilteelektrischeLeistungfürdenmotorischenBetrieb;elektrischeLeistungzurBerechnungeinesmomentanmöglichenmaximalenMomentsundeinermomentanmöglichenmaximalenmechanischenLeistung";
CM_ SG_ 190 MO_EM2_Min_Strom_Lim "minimalzulässigerHV-Strom,dervonderLEimgeneratorischenBetriebabgegebenwerdendarf(betragsmäßigmaximalaberi.d.R.negativ,daher‚Min‘);AbregelstromzurBegrenzungdesminimalenMomentsimgeneratorischenBetrieb";
CM_ SG_ 190 MO_EM2_Max_Strom_Lim "maximalzulässigerHV-Strom,dervonderLEimmotorischenBetriebaufgenommenwerdendarf;AbregelstromzurBegrenzungdesmaximalenMomentsimmotorischenBetrieb";
CM_ SG_ 190 MO_EM2_AR_Anf "AnforderungderAnti-RuckelFunktionaufderE-Maschine

0: aus
1: nicht belegt
2: D2T2 Regelung
3: Referenzdrehzahl Regelung
4: interne Referenzdrehzahlregelung";
CM_ SG_ 190 MO_EM2_SollSpannung "E-MaschinenSoll-Spannung";
CM_ SG_ 190 MO_DC_Max_Strom_HV "Abregelgrenze:maximalfreigegebenerStromaufderHochvolt-SeiteimTiefsetzbetrieb(StromausdemTraktionsnetzinsBordnetz)";
CM_ SG_ 190 MO_DC_SollSpannung_HV "SollwertfürdieTraktionsnetzspannungimHochsetzbetriebvomBordnetzinsTraktionsnetz
vorgehaltenes Signal; wird in PQ35/PL71 nicht berücksichtigt";
CM_ SG_ 190 MO_EM1_Max_Moment "maximalerlaubtespositives(motorisches)MomentderE-MaschineausHybridstrategie";
CM_ SG_ 190 MO_EM1_Min_Moment "maximalerlaubtesnegatives(generatorisches)MomentderE-MaschineausHybridstrategie";
CM_ SG_ 190 MO_EM2_Max_Moment "maximalerlaubtespositives(motorisches)MomentderE-MaschineausHybridstrategie";
CM_ SG_ 190 MO_EM2_Min_Moment "maximalerlaubtesnegatives(generatorisches)MomentderE-MaschineausHybridstrategie";
CM_ SG_ 2463978666 MO_EM1_Min_Spannung_Lim "minimalzulässigeHV-Spannung(DC),dievonderLEimmotorischenBetriebnichtunterschrittenwerdendarf;AbregelspannungzurBegrenzungdesmaximalenMomentsimmotorischenBetrieb";
CM_ SG_ 2463978666 MO_EM1_Max_Spannung_Lim "maximalzulässigeHV-Spannung(DC),dievonderLEimgeneratorischenBetriebnichtüberschrittenwerdendarf;AbregelspannungzurBegrenzungdesminimalenMomentsimgeneratorischenBetrieb";
CM_ SG_ 2463978666 MO_EM1_Min_Leistung_Gesamt "vomGesamtsystemaufnehmbareelektrischeLeistungfürdengeneratorischenBetrieb(betragsmäßigmaximalaberi.d.R.negativ,daher‚Min‘);elektrischeLeistungzurBerechnungeinesmomentanmöglichenminimalenMoments(maximalgenaratorisch)";
CM_ SG_ 2463978666 MO_EM1_Max_Leistung_Gesamt "imGesamtsystemverfügbareelektrischeLeistungfürdenmotorischenBetrieb;elektrischeLeistungzurBerechnungeinesmomentanmöglichen";
CM_ SG_ 2463978666 MO_EM2_Min_Leistung_Gesamt "vomGesamtsystemaufnehmbareelektrischeLeistungfürdengeneratorischenBetrieb(betragsmäßigmaximalaberi.d.R.negativ,daher‚Min‘);elektrischeLeistungzurBerechnungeinesmomentanmöglichenminimalenMoments(maximalgenaratorisch)";
CM_ SG_ 2463978666 MO_EM2_Max_Leistung_Gesamt "imGesamtsystemverfügbareelektrischeLeistungfürdenmotorischenBetrieb;elektrischeLeistungzurBerechnungeinesmomentanmöglichen";
CM_ SG_ 2463978666 MO_EM2_Min_Spannung_Lim "minimalzulässigeHV-Spannung(DC),dievonderLEimmotorischenBetriebnichtunterschrittenwerdendarf;AbregelspannungzurBegrenzungdesmaximalenMomentsimmotorischenBetrieb";
CM_ SG_ 2463978666 MO_EM2_Max_Spannung_Lim "maximalzulässigeHV-Spannung(DC),dievonderLEimgeneratorischenBetriebnichtüberschrittenwerdendarf;AbregelspannungzurBegrenzungdesminimalenMomentsimgeneratorischenBetrieb";
CM_ SG_ 2463978666 MO_EM1_Generator_Leistung "elektrischeWunschleistungzurBerechnungeinesmomentanerforderlichenMomentsimGeneratorbetrieb";
CM_ SG_ 2463978666 MO_Verbrauch_EM_Ges "Antriebs-EnergiedesAntriebs";
CM_ SG_ 2463978666 MO_Verbrauch_EM_Ges_Ueberlauf "Verbrauchssignalmindest1xübergelaufen";
CM_ SG_ 2463978666 MO_Rekuperation_Ges_EM "Rekuperation-EnergiedesAntriebs";
CM_ SG_ 2463978666 MO_Rekuperation_EM_Ges_Ueberlauf "Rekuperationleistungssignalmindest1xübergelaufen";
CM_ SG_ 2463978666 MO_Drehzahl_EM "Effektivdrehzahl,dieamE-Maschinenausgangermitteltwird,diefürdiePrimärachsezurVerfügungsteht";
CM_ SG_ 2463978666 MO_Uebersetzung_EM "ÜbersetzungvonMO_Drehzahl_EMzurPrimärachse,wenneineVerbindungsicherhergestelltist";
CM_ SG_ 2463978666 MO_Drehzahl_EM_sek "Effektivdrehzahl,dieamE-Maschinenausgangermitteltwird,diefürdieSekundärachsezurVerfügungsteht";
CM_ SG_ 2463978666 MO_Uebersetzung_EM_sek "ÜbersetzungvonMO_Drehzahl_EM_sekzurSekundärachse,wenneineVerbindungsicherhergestelltist";
CM_ SG_ 1601 Motor_Code_01_CRC "FürMLB:
'Berechnung siehe Lastenheft 'Kommunikationsabsicherung für FlexRay und CAN''

Ab MQB und MLBevo:
'Berechnung siehe Lastenheft 'End-to-End Kommunikationsabsicherung''

Endwerte siehe Begleitdokument 'S-PDU Kennungsfolgen'";
CM_ SG_ 1601 MO_Faktor_Momente_02 "DiesesSignalschaltetdenWertebereichallerMomentevomMotor,Getriebe,TSK,Bremse...um!DieMomentebesitzensomiteinenvariablenWertebereich,weilsichdurchdenFaktordieMomentesowohlinAuflösungalsauchMaximalwertenändert.

0x0 nicht ";
CM_ SG_ 1601 MO_Hybridfahrzeug "AnhanddiesesSignalsplausibilisiertdieLenkhilfedasBitFahrbereitschaft.

Im Projekt Cayenne PHEV (und ggf. auch VW526 PHEV) ist aus Gründen der Abwärtskompatibilität der Wert '2' zu senden.";
CM_ SG_ 1601 MO_Code "MotorcodierinformationVersion13(DetailssieheAnhang)";
CM_ SG_ 1601 MO_Getriebe_Code "GetriebecodierungdesMotors";
CM_ SG_ 1601 MO_StartStopp_Codiert "FunktionStartStoppimaktuellenKlemmenzyklusverbaut";
CM_ SG_ 1601 MO_Anzeige_StSt_gueltig "ZeigtdieGültigkeitderneuenStSt-Anzeigesignalean,MO_Anzeige_StSt_TextundMO_Anzeige_Symbol.Mo_Text_Motorstart1..5sindzuignorieren.";
CM_ SG_ 1601 MO_Anzahl_Zyl "ZylinderzahldesVerbrennungsmotors";
CM_ SG_ 1601 MO_Kraftstoffart "PrimärkraftstoffzumAntriebdesFahrzeugs";
CM_ SG_ 1601 MO_Hubraum "HubraumdesVerbrennungsmotors";
CM_ SG_ 1601 MO_Ansaugsystem "ArtdesAnsaugsystemsdesVerbrennungsmotors";
CM_ SG_ 1601 MO_Leistung "NennleistungdesVerbrennungsmotors";
CM_ SG_ 1601 MO_OBD_Typ "AbgastypOBD";
CM_ SG_ 1601 MO_DPF_verbaut "VerbauinformationDiesel-Partikel-Filter
";
CM_ SG_ 1601 TSK_Codierung "InformationüberdenplausibilisiertenCodierungszustanddesTriebstrangskoordinatorsaufACCoderGRA.";
CM_ SG_ 1155 Mo_Powermeter_Grenze "AnzeigedesverfügbarenPowermeterstandsimKombi.BeiEVUnterscheidungzwischenBoost-undDauerbereich,beiHEVfürdieZustartgrenzenutzber";
CM_ SG_ 1155 MO_Text_Aktivierung_Antrieb "FahrerinformationzurAntriebsstrangaktivierung.";
CM_ SG_ 1155 MO_Powermeter_Inszenierung_aktiv "MitHilfedesSignalskanneineDynamikabfahrtfürdenKundeninszeniertwerden.DieInszenierungwirdimPowermeterdesKombi-Instrumentsverortet.";
CM_ SG_ 1155 MO_Powermeter_Charge_Grenze "ZeigteineEinschränkungderRekuperationsleistungan
";
CM_ SG_ 1155 MO_Powermeter_Grenze_strategisch "ZeigteinestrategischeLeistungsbeschränkungdesAntriebs,
zum Beispiel kein Boost im Efficiency Modus";
CM_ SG_ 1155 MO_Powermeter_untere_E_Grenze "ZeigtdieuntereGrenzefürdaselektrischeFahrenan";
CM_ SG_ 1155 MO_Powermeter_obere_E_Grenze "ZeigtdieobereGrenzefürdaselektrischeFahrenan";
CM_ SG_ 2527679686 MRR_HR_ASM_Ereignis "DiesesSignaldefiniert,welcheFunktionundwelcheArtvonAktivitätdasSendenderBotschaftandenAssistenzsystemmonitorASMveranlassthat.";
CM_ SG_ 2527679686 MRR_HR_ASM_Zeitstempel "DiesesSignalermöglichtdiezeitlicheZuordnungdervonmehrerenFunktionenaufdemMRRandenAssistenzsystemmonitorASMgesendetenStatusbot-schaften.";
CM_ SG_ 2527679686 MRR_HR_ASM_Data_1 "DiesesSignalwirdvonMRR_HRbefülltundandenAssistenzsystemmonitorASM(HostSG:SafetyComputer)gesendet.";
CM_ SG_ 2527679686 MRR_HR_ASM_Data_2 "DiesesSignalwirdvonMRR_HRbefülltundandenAssistenzsystemmonitorASM(HostSG:SafetyComputer)gesendet.";
CM_ SG_ 2527679686 MRR_HR_ASM_Data_3 "DiesesSignalwirdvonMRR_HRbefülltundandenAssistenzsystemmonitorASM(HostSG:SafetyComputer)gesendet.";
CM_ SG_ 2527679686 MRR_HR_ASM_Data_4 "DiesesSignalwirdvonMRR_HRbefülltundandenAssistenzsystemmonitorASM(HostSG:SafetyComputer)gesendet.";
CM_ SG_ 2527679686 MRR_HR_ASM_Data_5 "DiesesSignalwirdvonMRR_HRbefülltundandenAssistenzsystemmonitorASM(HostSG:SafetyComputer)gesendet.";
CM_ SG_ 2527679686 MRR_HR_ASM_Data_6 "DiesesSignalwirdvonMRR_HRbefülltundandenAssistenzsystemmonitorASM(HostSG:SafetyComputer)gesendet.";
CM_ SG_ 339 MSG_HYB_30_CRC "CRCfürdieBotschaftMSG_HYB_30";
CM_ SG_ 339 MSG_HYB_30_BZ "BZfürdieBotschaftMSG_HYB_30";
CM_ SG_ 339 MO_HVEM_Eskalation "Eskalationsbit,mitdiesemzusammendarfMO_HVEM_MaxLeistung<derminimalangefordertenLeistungseinundistdurchdasHVEMdurchErgreifungallerEskalationsmaßnahmenumzusetzen(Beineg.Ladebilanzz.B.imLeerlaufnötig,umdieHVBattvorEntladunge";
CM_ SG_ 339 MO_ErwGrenzen_Anf "temporäreAnforderungerweiterterLeistungsgrenzen
0 = normaler Betrieb angefordert
1 = erweiterte Leistungsgrenzen angefordert
BMS und EMS liefern ggf. erweiterte Leistungsgrenzen, um VKM-Start auch unter schwierigen Bedingungen gewährleisten zu könne";
CM_ SG_ 339 MO_Fehler_Notentladung_Anf "AufforderungzurschnellstmöglichenEntladeungdesHV-ZwischenkreisesaufgrundCrash-Erkennung/AbrissPilotlinie";
CM_ SG_ 339 MO_HVEM_MaxLeistung "MaximalzulässigeLeistung,diedasHVEMeinzustellenhat.
Ohne Eskalationsbit ist diese Anforderung >= der Minimal benötigten Leistung des HVEM

Hinweis: Ehemaliger Fehlerwert 0x1FF wird senderseitig nicht unterstützt. Diesen Wert aus Kompatibilitäts";
CM_ SG_ 339 MO_HVK_EmIstzustand "AktuellerIstzustandderElm_State
0 : HvOff
1 : HvStbyReq
2 : HvStbyOk
3 : HvBattOnReq
4 : HvBattOnOk
10 : HvOnIdle
18 : HvOnDrvReq
19 : HvOnDrvOk
20 : HvOnDrvRdy          ";
CM_ SG_ 339 MO_HVK_AntriebFehlerstatus "aktuellerFehlerstatusdesAntriebs
0: Komponente IO (keine HVK relevanter Fehler)
1 - 5: reserve
6: Keine Komponentenfunktion (Aus)
7: Init";
CM_ SG_ 339 MO_MVK_Bordnetz_Anf "ExpliziteAnforderungdesMotorszurAktivierungbzw.AufrechterhaltungdesMittelvolt-BordnetzesfürdieAusführungvonMotorfunktionen";
CM_ SG_ 339 MO_HVK_AntriebZustand "AktuellerZustanddesAntriebs:
0 : Antrieb_AUS
1 : Antrieb_Startphase
2 : E-Fahren
3 : Hybrid-Fahren
4 : reserve
5 : reserve
6 : Keine_Komponentenfunktion ";
CM_ SG_ 339 MO_HVK_EmFehlerstatus "aktuellerFehlerstatusdeselektrischenAntriebes(E-MaschineundPWR)

0: Komponente IO (keine HVK relevanter Fehler)
1: Eingeschränkter Betrieb wg. Teilbetrieb
2: reserve
3: Eingeschr_KompFkt_Interlock
4 - 5: reserve
6: Keine Komponentenfunktion ";
CM_ SG_ 339 MO_MVK_AntriebFehlerstatus "aktuellerFehlerstatusdesAntriebs
0: Komponente IO (keine MVK relevanter Fehler)
1 - 5: reserve
6: Keine Komponentenfunktion (Aus)
7: Init";
CM_ SG_ 339 MO_MVK_AntriebZustand "AktuellerZustanddesAntriebs:
0 : Antrieb_AUS
1 : Antrieb_Startphase
2 : FreilaufMotorAus
3 : reserve
4 : reserve
5 : reserve
6 : Keine_Komponentenfunktio";
CM_ SG_ 339 MO_MVK_EmFehlerstatus "aktuellerFehlerstatusderelektrischenMaschine(RSG)

0: Komponente IO (keine MVK relevanter Fehler)
1: Eingeschränkter Betrieb wg. Teilbetrieb
2: reserve
3 - 5: reserve
6: Keine Komponentenfunktion (Aus)
7: Init";
CM_ SG_ 339 MO_MVK_EmIstzustand "AktuellerIstzustandderElm_State
0 : MvOff
1 : MvStbyReq
2 : MvStbyOk
3 : MvBattOnReq
4 : MvBattOnOk
10 : MvOnIdle
18 : MvOnDrvReq
19 : MvOnDrvOk
20 : MvOnDrv
";
BA_DEF_ BO_ "DiagRequest" ENUM "No", "Yes";
BA_DEF_ BO_ "DiagResponse" ENUM "No", "Yes";
BA_DEF_ BO_ "DiagState" ENUM "No", "Yes";
BA_DEF_ BO_ "GenMsgChkConstant" HEX 0 4095;
BA_DEF_ BO_ "GenMsgCycleTime" INT 0 65535;
BA_DEF_ BO_ "GenMsgCycleTimeFast" INT 0 65535;
BA_DEF_ BO_ "GenMsgDelayTime" INT 0 100000;
BA_DEF_ BO_ "GenMsgILSupport" ENUM "No", "Yes";
BA_DEF_ BO_ "GenMsgNrOfRepetition" INT 0 100;
BA_DEF_ BO_ "GenMsgPDUConstants" STRING;
BA_DEF_ BO_ "GenMsgSendType" ENUM "Cyclic", "not_used", "not_used", "not_used", "not_used", "not_used", "not_used", "IfActive", "NoMsgSendType";
BA_DEF_ BO_ "GenMsgStartDelayTime" INT 0 100000;
BA_DEF_ BO_ "NmMessage" ENUM "No", "Yes";
BA_DEF_ BO_ "NmhMessage" ENUM "No", "Yes";
BA_DEF_ BO_ "MsgType" ENUM "Application", "NM", "NMH", "TP2.0", "ISO-TP", "BAP", "EID", "KS";
BA_DEF_ BO_ "VAGTP20_API" HEX 0 255;
BA_DEF_ BO_ "VAGTP20_DynConnection" ENUM "No", "Yes";
BA_DEF_ BO_ "VAGTP20_DynSetup" ENUM "No", "Yes";
BA_DEF_ BO_ "VAGTP20_StatConnection" ENUM "No", "Yes";
BA_DEF_ BO_ "CANFD_BRS" ENUM "0", "1";
BA_DEF_ BO_ "VFrameFormat" ENUM "StandardCAN", "ExtendedCAN", "reserved", "reserved", "reserved", "reserved", "reserved", "reserved", "reserved", "reserved", "reserved", "reserved", "reserved", "reserved", "StandardCAN_FD", "ExtendedCAN_FD";
BA_DEF_ SG_ "GenSigActiveRepetitions" INT -2147483648 2147483647;
BA_DEF_ SG_ "GenSigInactiveValue" INT -2147483648 2147483647;
BA_DEF_ SG_ "GenSigSendType" ENUM "Cyclic", "OnWrite", "OnWriteWithRepetition", "OnChange", "OnChangeWithRepetition", "IfActive", "IfActiveWithRepetition", "NoSigSendType", "OnChangeAndIfActive", "OnChangeAndIfActiveWithRepetition";
BA_DEF_ SG_ "GenSigStartValue" INT -2147483648 2147483647;
BA_DEF_ SG_ "NWM-WakeupAllowed" ENUM "No", "Yes";
BA_DEF_ SG_ "GenSigFuncType" ENUM "NoFunction", "MsgCounter", "CRC-8", "XOR", "XOR-2", "DatedBit", "SW-Kl15", "CHK", "Constant", "Protocol", "CRC-8-SAE_J1850";
BA_DEF_ SG_ "GenSigSwitchedByIgnition" ENUM "No", "Yes";
BA_DEF_ SG_ "Fehlerwert" HEX 0 2147483647;
BA_DEF_ SG_ "GenSigMissingSourceValue" HEX 0 2147483647;
BA_DEF_DEF_  "DiagRequest" "No";
BA_DEF_DEF_  "DiagResponse" "No";
BA_DEF_DEF_  "DiagState" "No";
BA_DEF_DEF_  "GenMsgChkConstant" 0;
BA_DEF_DEF_  "GenMsgCycleTime" 0;
BA_DEF_DEF_  "GenMsgCycleTimeFast" 0;
BA_DEF_DEF_  "GenMsgDelayTime" 0;
BA_DEF_DEF_  "GenMsgILSupport" "No";
BA_DEF_DEF_  "GenMsgNrOfRepetition" 0;
BA_DEF_DEF_  "GenMsgPDUConstants" "";
BA_DEF_DEF_  "GenMsgSendType" "NoMsgSendType";
BA_DEF_DEF_  "GenMsgStartDelayTime" 0;
BA_DEF_DEF_  "NmMessage" "No";
BA_DEF_DEF_  "NmhMessage" "No";
BA_DEF_DEF_  "MsgType" "Application";
BA_DEF_DEF_  "VAGTP20_API" 0;
BA_DEF_DEF_  "VAGTP20_DynConnection" "No";
BA_DEF_DEF_  "VAGTP20_DynSetup" "No";
BA_DEF_DEF_  "VAGTP20_StatConnection" "No";
BA_DEF_DEF_  "CANFD_BRS" "1";
BA_DEF_DEF_  "VFrameFormat" "StandardCAN";
BA_DEF_DEF_  "GenSigActiveRepetitions" 0;
BA_DEF_DEF_  "GenSigInactiveValue" 0;
BA_DEF_DEF_  "GenSigSendType" "NoSigSendType";
BA_DEF_DEF_  "GenSigStartValue" 0;
BA_DEF_DEF_  "NWM-WakeupAllowed" "No";
BA_DEF_DEF_  "GenSigFuncType" "NoFunction";
BA_DEF_DEF_  "GenSigSwitchedByIgnition" "Yes";
BA_DEF_DEF_  "Fehlerwert" 0;
BA_DEF_DEF_  "GenSigMissingSourceValue" 0;
BA_ "GenMsgCycleTime" BO_ 1648 500;
BA_ "GenMsgDelayTime" BO_ 1648 20;
BA_ "GenMsgILSupport" BO_ 1648 "Yes";
BA_ "GenMsgSendType" BO_ 1648 "Cyclic";
BA_ "VFrameFormat" BO_ 1648 "StandardCAN_FD";
BA_ "GenMsgCycleTime" BO_ 967 100;
BA_ "GenMsgILSupport" BO_ 967 "Yes";
BA_ "GenMsgSendType" BO_ 967 "Cyclic";
BA_ "VFrameFormat" BO_ 967 "StandardCAN_FD";
BA_ "GenMsgCycleTime" BO_ 706 500;
BA_ "GenMsgDelayTime" BO_ 706 100;
BA_ "GenMsgILSupport" BO_ 706 "Yes";
BA_ "GenMsgSendType" BO_ 706 "Cyclic";
BA_ "VFrameFormat" BO_ 706 "StandardCAN_FD";
BA_ "GenMsgCycleTime" BO_ 267 20;
BA_ "GenMsgILSupport" BO_ 267 "Yes";
BA_ "GenMsgPDUConstants" BO_ 267 "0x77,0x5c,0xa0,0x89,0x4b,0x7c,0xbb,0xd6,0x1f,0x6c,0x4f,0xf6,0x20,0x2b,0x43,0xdd";
BA_ "GenMsgSendType" BO_ 267 "Cyclic";
BA_ "VFrameFormat" BO_ 267 "StandardCAN_FD";
BA_ "GenMsgCycleTime" BO_ 330 20;
BA_ "GenMsgILSupport" BO_ 330 "Yes";
BA_ "GenMsgSendType" BO_ 330 "Cyclic";
BA_ "VFrameFormat" BO_ 330 "StandardCAN_FD";
BA_ "GenMsgCycleTime" BO_ 512 50;
BA_ "GenMsgILSupport" BO_ 512 "Yes";
BA_ "GenMsgSendType" BO_ 512 "Cyclic";
BA_ "VFrameFormat" BO_ 512 "StandardCAN_FD";
BA_ "GenMsgCycleTime" BO_ 332 100;
BA_ "GenMsgDelayTime" BO_ 332 10;
BA_ "GenMsgILSupport" BO_ 332 "Yes";
BA_ "GenMsgSendType" BO_ 332 "Cyclic";
BA_ "VFrameFormat" BO_ 332 "StandardCAN_FD";
BA_ "GenMsgCycleTime" BO_ 246 10;
BA_ "GenMsgILSupport" BO_ 246 "Yes";
BA_ "GenMsgPDUConstants" BO_ 246 "0x89,0xd6,0xf6,0xdd,0xe7,0x74,0x0f,0xd2,0x26,0x5a,0x44,0x70,0xd5,0x67,0x79,0x3d";
BA_ "GenMsgSendType" BO_ 246 "Cyclic";
BA_ "VFrameFormat" BO_ 246 "StandardCAN_FD";
BA_ "GenMsgCycleTime" BO_ 190 10;
BA_ "GenMsgILSupport" BO_ 190 "Yes";
BA_ "GenMsgPDUConstants" BO_ 190 "0x18,0x71,0x10,0x8d,0xd7,0xaa,0xb0,0x78,0xac,0x12,0xae,0x0c,0xdd,0xf1,0x85,0x68";
BA_ "GenMsgSendType" BO_ 190 "Cyclic";
BA_ "VFrameFormat" BO_ 190 "StandardCAN_FD";
BA_ "GenMsgCycleTime" BO_ 2463978666 100;
BA_ "GenMsgILSupport" BO_ 2463978666 "Yes";
BA_ "GenMsgSendType" BO_ 2463978666 "Cyclic";
BA_ "VFrameFormat" BO_ 2463978666 "ExtendedCAN_FD";
BA_ "GenMsgChkConstant" BO_ 1601 71;
BA_ "GenMsgCycleTime" BO_ 1601 1000;
BA_ "GenMsgILSupport" BO_ 1601 "Yes";
BA_ "GenMsgPDUConstants" BO_ 1601 "0x47,0x47,0x47,0x47,0x47,0x47,0x47,0x47,0x47,0x47,0x47,0x47,0x47,0x47,0x47,0x47";
BA_ "GenMsgSendType" BO_ 1601 "Cyclic";
BA_ "VFrameFormat" BO_ 1601 "StandardCAN_FD";
BA_ "GenMsgCycleTime" BO_ 1155 500;
BA_ "GenMsgDelayTime" BO_ 1155 50;
BA_ "GenMsgILSupport" BO_ 1155 "Yes";
BA_ "GenMsgSendType" BO_ 1155 "Cyclic";
BA_ "VFrameFormat" BO_ 1155 "StandardCAN_FD";
BA_ "GenMsgCycleTime" BO_ 2527679686 2000;
BA_ "GenMsgDelayTime" BO_ 2527679686 100;
BA_ "GenMsgILSupport" BO_ 2527679686 "Yes";
BA_ "GenMsgSendType" BO_ 2527679686 "Cyclic";
BA_ "VFrameFormat" BO_ 2527679686 "ExtendedCAN_FD";
BA_ "GenMsgILSupport" BO_ 22 "Yes";
BA_ "VFrameFormat" BO_ 22 "StandardCAN_FD";
BA_ "GenMsgILSupport" BO_ 24 "Yes";
BA_ "VFrameFormat" BO_ 24 "StandardCAN_FD";
BA_ "GenMsgCycleTime" BO_ 339 200;
BA_ "GenMsgDelayTime" BO_ 339 10;
BA_ "GenMsgILSupport" BO_ 339 "Yes";
BA_ "GenMsgPDUConstants" BO_ 339 "0x03,0x13,0x23,0x7a,0x40,0x51,0x68,0xba,0xa8,0xbe,0x55,0x02,0x11,0x31,0x76,0xec";
BA_ "GenMsgSendType" BO_ 339 "Cyclic";
BA_ "VFrameFormat" BO_ 339 "StandardCAN_FD";
BA_ "GenSigSendType" SG_ 1648 MO_max_Ladedruck "Cyclic";
BA_ "GenSigFuncType" SG_ 1648 MO_max_Ladedruck "Constant";
BA_ "GenSigSwitchedByIgnition" SG_ 1648 MO_max_Ladedruck "No";
BA_ "GenSigSendType" SG_ 1648 MO_ANC_Kennfeld_Anf "OnChange";
BA_ "GenSigSwitchedByIgnition" SG_ 1648 MO_ANC_Kennfeld_Anf "No";
BA_ "GenSigSendType" SG_ 1648 MO_Bremslicht_Reku "OnChange";
BA_ "GenSigSwitchedByIgnition" SG_ 1648 MO_Bremslicht_Reku "No";
BA_ "GenSigSendType" SG_ 1648 MO_StartStopp_PopUp "OnChange";
BA_ "GenSigSwitchedByIgnition" SG_ 1648 MO_StartStopp_PopUp "No";
BA_ "GenSigSendType" SG_ 1648 MO1_Sperr_Info_WFS "OnChange";
BA_ "GenSigSwitchedByIgnition" SG_ 1648 MO1_Sperr_Info_WFS "No";
BA_ "GenSigSendType" SG_ 1648 MO1_Freigabe_Info_WFS "OnChange";
BA_ "GenSigSwitchedByIgnition" SG_ 1648 MO1_Freigabe_Info_WFS "No";
BA_ "GenSigSendType" SG_ 1648 MO_EPCL "OnChange";
BA_ "GenSigSwitchedByIgnition" SG_ 1648 MO_EPCL "No";
BA_ "GenSigSendType" SG_ 1648 MO_Zylabsch_Texte_02 "OnChange";
BA_ "GenSigSwitchedByIgnition" SG_ 1648 MO_Zylabsch_Texte_02 "No";
BA_ "GenSigSendType" SG_ 1648 MO_Fahrzeugtyp "Cyclic";
BA_ "GenSigFuncType" SG_ 1648 MO_Fahrzeugtyp "Constant";
BA_ "GenSigSwitchedByIgnition" SG_ 1648 MO_Fahrzeugtyp "No";
BA_ "GenSigSendType" SG_ 1648 MO_NMAX_Schaltanzeige "OnChange";
BA_ "GenSigSwitchedByIgnition" SG_ 1648 MO_NMAX_Schaltanzeige "No";
BA_ "GenSigSendType" SG_ 1648 MO_Abstellzeit "Cyclic";
BA_ "GenSigStartValue" SG_ 1648 MO_Abstellzeit 254;
BA_ "GenSigSwitchedByIgnition" SG_ 1648 MO_Abstellzeit "No";
BA_ "GenSigSendType" SG_ 1648 MO_Abstellzeit_Status "Cyclic";
BA_ "GenSigSwitchedByIgnition" SG_ 1648 MO_Abstellzeit_Status "No";
BA_ "GenSigSendType" SG_ 1648 MO1_Freigabe_Verfallsinfo_WFS "OnChange";
BA_ "GenSigSwitchedByIgnition" SG_ 1648 MO1_Freigabe_Verfallsinfo_WFS "No";
BA_ "GenSigSendType" SG_ 1648 MO_Hybrid_StartStopp_LED "OnChange";
BA_ "GenSigSwitchedByIgnition" SG_ 1648 MO_Hybrid_StartStopp_LED "No";
BA_ "GenSigSendType" SG_ 1648 MO_Fehler_Zylabsch "Cyclic";
BA_ "GenSigSwitchedByIgnition" SG_ 1648 MO_Fehler_Zylabsch "No";
BA_ "GenSigSendType" SG_ 1648 MO_Anzahl_Abgesch_Zyl "OnChange";
BA_ "GenSigSwitchedByIgnition" SG_ 1648 MO_Anzahl_Abgesch_Zyl "No";
BA_ "GenSigSendType" SG_ 1648 MO_Zylabsch_Texte "Cyclic";
BA_ "GenSigSwitchedByIgnition" SG_ 1648 MO_Zylabsch_Texte "No";
BA_ "GenSigSendType" SG_ 1648 MO_Ethanol_BS_Texte "Cyclic";
BA_ "GenSigSwitchedByIgnition" SG_ 1648 MO_Ethanol_BS_Texte "No";
BA_ "GenSigSendType" SG_ 1648 MO_Drehzahl_Warnung "Cyclic";
BA_ "GenSigSwitchedByIgnition" SG_ 1648 MO_Drehzahl_Warnung "No";
BA_ "GenSigSendType" SG_ 1648 MO_obere_Drehzahlgrenze "Cyclic";
BA_ "GenSigSwitchedByIgnition" SG_ 1648 MO_obere_Drehzahlgrenze "No";
BA_ "GenSigSendType" SG_ 967 MO_Kuehlerluefter_MUX "Cyclic";
BA_ "GenSigSwitchedByIgnition" SG_ 967 MO_Kuehlerluefter_MUX "No";
BA_ "GenSigStartValue" SG_ 967 MO_Kuehlerluefter_1 126;
BA_ "GenSigSwitchedByIgnition" SG_ 967 MO_Kuehlerluefter_1 "No";
BA_ "Fehlerwert" SG_ 967 MO_Kuehlerluefter_1 127;
BA_ "GenSigStartValue" SG_ 967 MO_Kuehlerluefter_2 126;
BA_ "GenSigSwitchedByIgnition" SG_ 967 MO_Kuehlerluefter_2 "No";
BA_ "Fehlerwert" SG_ 967 MO_Kuehlerluefter_2 127;
BA_ "GenSigSendType" SG_ 967 MO_EFLEX_Lampe "Cyclic";
BA_ "GenSigSwitchedByIgnition" SG_ 967 MO_EFLEX_Lampe "No";
BA_ "GenSigSendType" SG_ 967 MO_KJS_nicht_bereit "Cyclic";
BA_ "GenSigSwitchedByIgnition" SG_ 967 MO_KJS_nicht_bereit "No";
BA_ "Fehlerwert" SG_ 967 MO_KJS_nicht_bereit 1;
BA_ "GenSigSendType" SG_ 967 MO_ITM_Warnung_Pumpe "Cyclic";
BA_ "GenSigSwitchedByIgnition" SG_ 967 MO_ITM_Warnung_Pumpe "No";
BA_ "GenSigSendType" SG_ 967 WIV_Anzeige_aktiv "Cyclic";
BA_ "GenSigSwitchedByIgnition" SG_ 967 WIV_Anzeige_aktiv "No";
BA_ "GenSigSendType" SG_ 967 WIV_Oelmin_Warn "Cyclic";
BA_ "GenSigSwitchedByIgnition" SG_ 967 WIV_Oelmin_Warn "No";
BA_ "GenSigSendType" SG_ 967 WIV_Sensorfehler "Cyclic";
BA_ "GenSigSwitchedByIgnition" SG_ 967 WIV_Sensorfehler "No";
BA_ "GenSigSendType" SG_ 967 WIV_Schieflage "Cyclic";
BA_ "GenSigSwitchedByIgnition" SG_ 967 WIV_Schieflage "No";
BA_ "GenSigSendType" SG_ 967 WIV_Oelstand "Cyclic";
BA_ "GenSigSwitchedByIgnition" SG_ 967 WIV_Oelstand "No";
BA_ "GenSigSendType" SG_ 967 MO_Zustand_HWP "Cyclic";
BA_ "GenSigStartValue" SG_ 967 MO_Zustand_HWP 1;
BA_ "GenSigSwitchedByIgnition" SG_ 967 MO_Zustand_HWP "No";
BA_ "GenSigSendType" SG_ 967 OLEV_Systemstoerung "Cyclic";
BA_ "GenSigSwitchedByIgnition" SG_ 967 OLEV_Systemstoerung "No";
BA_ "GenSigSendType" SG_ 967 MO_Oelwarnung_max "Cyclic";
BA_ "GenSigSwitchedByIgnition" SG_ 967 MO_Oelwarnung_max "No";
BA_ "GenSigSendType" SG_ 967 WIV_Oelsystem_aktiv "Cyclic";
BA_ "GenSigSwitchedByIgnition" SG_ 967 WIV_Oelsystem_aktiv "No";
BA_ "GenSigSendType" SG_ 967 WIV_nicht_betriebswarm "Cyclic";
BA_ "GenSigSwitchedByIgnition" SG_ 967 WIV_nicht_betriebswarm "No";
BA_ "GenSigSendType" SG_ 967 WIV_Ueberfuell_Warn "Cyclic";
BA_ "GenSigSwitchedByIgnition" SG_ 967 WIV_Ueberfuell_Warn "No";
BA_ "GenSigSendType" SG_ 967 WIV_laufender_Motor "Cyclic";
BA_ "GenSigSwitchedByIgnition" SG_ 967 WIV_laufender_Motor "No";
BA_ "GenSigSendType" SG_ 967 MO_E_Warnungen "Cyclic";
BA_ "GenSigSwitchedByIgnition" SG_ 967 MO_E_Warnungen "No";
BA_ "GenSigSendType" SG_ 967 MO_Text_Motorstart "Cyclic";
BA_ "GenSigSwitchedByIgnition" SG_ 967 MO_Text_Motorstart "No";
BA_ "GenSigSendType" SG_ 967 MO_E_Texte "Cyclic";
BA_ "GenSigSwitchedByIgnition" SG_ 967 MO_E_Texte "No";
BA_ "GenSigSendType" SG_ 967 WIV_Oeldyn_avl "Cyclic";
BA_ "GenSigSwitchedByIgnition" SG_ 967 WIV_Oeldyn_avl "No";
BA_ "GenSigSendType" SG_ 967 MO_Text_Partikelfil_Reg "Cyclic";
BA_ "GenSigSwitchedByIgnition" SG_ 967 MO_Text_Partikelfil_Reg "No";
BA_ "GenSigSendType" SG_ 967 OLEV_Oelstand_nicht_vorhanden "Cyclic";
BA_ "GenSigSwitchedByIgnition" SG_ 967 OLEV_Oelstand_nicht_vorhanden "No";
BA_ "GenSigSendType" SG_ 967 WIV_Oelmenge "Cyclic";
BA_ "GenSigSwitchedByIgnition" SG_ 967 WIV_Oelmenge "No";
BA_ "GenSigSendType" SG_ 967 MO_Systemlampe "Cyclic";
BA_ "GenSigSwitchedByIgnition" SG_ 967 MO_Systemlampe "No";
BA_ "GenSigSendType" SG_ 967 MO_OBD2_Lampe "Cyclic";
BA_ "GenSigSwitchedByIgnition" SG_ 967 MO_OBD2_Lampe "No";
BA_ "GenSigSendType" SG_ 967 MO_Heissleuchte "Cyclic";
BA_ "GenSigSwitchedByIgnition" SG_ 967 MO_Heissleuchte "No";
BA_ "GenSigSendType" SG_ 967 MO_Partikel_Lampe "Cyclic";
BA_ "GenSigSwitchedByIgnition" SG_ 967 MO_Partikel_Lampe "No";
BA_ "GenSigSendType" SG_ 967 MO_RedFahrleistung_Lampe "Cyclic";
BA_ "GenSigSwitchedByIgnition" SG_ 967 MO_RedFahrleistung_Lampe "No";
BA_ "GenSigSendType" SG_ 967 WIV_Oelstand_nicht_vorhanden "Cyclic";
BA_ "GenSigSwitchedByIgnition" SG_ 967 WIV_Oelstand_nicht_vorhanden "No";
BA_ "GenSigSendType" SG_ 967 WIV_nachfuellanzeige_ein "Cyclic";
BA_ "GenSigSwitchedByIgnition" SG_ 967 WIV_nachfuellanzeige_ein "No";
BA_ "GenSigSendType" SG_ 967 WIV_Ueberfuell_deaktiv "Cyclic";
BA_ "GenSigSwitchedByIgnition" SG_ 967 WIV_Ueberfuell_deaktiv "No";
BA_ "GenSigSendType" SG_ 967 WIV_Unterfuell_Warn "Cyclic";
BA_ "GenSigSwitchedByIgnition" SG_ 967 WIV_Unterfuell_Warn "No";
BA_ "GenSigSendType" SG_ 967 MO_Tankdeckel_Lampe "Cyclic";
BA_ "GenSigSwitchedByIgnition" SG_ 967 MO_Tankdeckel_Lampe "No";
BA_ "GenSigSendType" SG_ 967 MO_Text_Tankdeckelwarn "Cyclic";
BA_ "GenSigSwitchedByIgnition" SG_ 967 MO_Text_Tankdeckelwarn "No";
BA_ "GenSigSendType" SG_ 967 MO_Vorglueh_Lampe "Cyclic";
BA_ "GenSigSwitchedByIgnition" SG_ 967 MO_Vorglueh_Lampe "No";
BA_ "GenSigSendType" SG_ 967 WIV_Oeldr_Warn_Motor "Cyclic";
BA_ "GenSigSwitchedByIgnition" SG_ 967 WIV_Oeldr_Warn_Motor "No";
BA_ "GenSigSendType" SG_ 967 MO_E_Mode "Cyclic";
BA_ "GenSigSwitchedByIgnition" SG_ 967 MO_E_Mode "No";
BA_ "GenSigSendType" SG_ 706 MO_Anzeige_StSt_Text "OnChange";
BA_ "GenSigSwitchedByIgnition" SG_ 706 MO_Anzeige_StSt_Text "No";
BA_ "GenSigSendType" SG_ 706 MO_Anzeige_StSt_Symbol "OnChange";
BA_ "GenSigSwitchedByIgnition" SG_ 706 MO_Anzeige_StSt_Symbol "No";
BA_ "GenSigSendType" SG_ 706 MO_ADR_Status "OnChange";
BA_ "GenSigSwitchedByIgnition" SG_ 706 MO_ADR_Status "No";
BA_ "GenSigSendType" SG_ 706 MO_AGA_Sound_Texte "OnChange";
BA_ "GenSigSwitchedByIgnition" SG_ 706 MO_AGA_Sound_Texte "No";
BA_ "GenSigSendType" SG_ 706 MO_Anzeige_FMAus_Text "OnChange";
BA_ "GenSigSwitchedByIgnition" SG_ 706 MO_Anzeige_FMAus_Text "No";
BA_ "GenSigSendType" SG_ 706 PEA_Texte "OnChange";
BA_ "GenSigSwitchedByIgnition" SG_ 706 PEA_Texte "No";
BA_ "GenSigSendType" SG_ 706 TSK_Ueberstimmt_vMax_FahrerInfo "OnChange";
BA_ "GenSigSwitchedByIgnition" SG_ 706 TSK_Ueberstimmt_vMax_FahrerInfo "No";
BA_ "GenSigSendType" SG_ 706 MO_Rekuperationsstufe "OnChange";
BA_ "GenSigStartValue" SG_ 706 MO_Rekuperationsstufe 7;
BA_ "GenSigSwitchedByIgnition" SG_ 706 MO_Rekuperationsstufe "No";
BA_ "GenSigSendType" SG_ 706 TSK_Einheit_vMax_FahrerInfo "Cyclic";
BA_ "GenSigSwitchedByIgnition" SG_ 706 TSK_Einheit_vMax_FahrerInfo "No";
BA_ "GenSigSendType" SG_ 706 TSK_Status_vMax_FahrerInfo "Cyclic";
BA_ "GenSigSwitchedByIgnition" SG_ 706 TSK_Status_vMax_FahrerInfo "No";
BA_ "GenSigSendType" SG_ 706 MO_Anz_Kuehlerluefter "Cyclic";
BA_ "GenSigSwitchedByIgnition" SG_ 706 MO_Anz_Kuehlerluefter "No";
BA_ "GenSigSendType" SG_ 706 FDR_Warnung_ALR "OnChange";
BA_ "GenSigSwitchedByIgnition" SG_ 706 FDR_Warnung_ALR "No";
BA_ "GenSigSendType" SG_ 706 TSK_vMax_FahrerInfo "Cyclic";
BA_ "GenSigSwitchedByIgnition" SG_ 706 TSK_vMax_FahrerInfo "No";
BA_ "GenSigSendType" SG_ 267 Motor_51_CRC "Cyclic";
BA_ "GenSigFuncType" SG_ 267 Motor_51_CRC "CRC-8";
BA_ "GenSigSwitchedByIgnition" SG_ 267 Motor_51_CRC "No";
BA_ "GenSigSendType" SG_ 267 Motor_51_BZ "Cyclic";
BA_ "GenSigFuncType" SG_ 267 Motor_51_BZ "MsgCounter";
BA_ "GenSigSwitchedByIgnition" SG_ 267 Motor_51_BZ "No";
BA_ "GenSigSendType" SG_ 267 MO_Fahrpedalrohwert_01 "Cyclic";
BA_ "GenSigSwitchedByIgnition" SG_ 267 MO_Fahrpedalrohwert_01 "No";
BA_ "Fehlerwert" SG_ 267 MO_Fahrpedalrohwert_01 255;
BA_ "GenSigSendType" SG_ 267 MO_QBit_Fahrpedalwerte_01 "Cyclic";
BA_ "GenSigStartValue" SG_ 267 MO_QBit_Fahrpedalwerte_01 1;
BA_ "GenSigSwitchedByIgnition" SG_ 267 MO_QBit_Fahrpedalwerte_01 "No";
BA_ "GenSigSendType" SG_ 267 MO_Fahrpedalgradient "Cyclic";
BA_ "GenSigSwitchedByIgnition" SG_ 267 MO_Fahrpedalgradient "No";
BA_ "Fehlerwert" SG_ 267 MO_Fahrpedalgradient 255;
BA_ "GenSigSendType" SG_ 267 MO_Sig_Fahrpedalgradient "Cyclic";
BA_ "GenSigSwitchedByIgnition" SG_ 267 MO_Sig_Fahrpedalgradient "No";
BA_ "GenSigSendType" SG_ 267 MO_rel_Saugrohrdruck "Cyclic";
BA_ "GenSigSwitchedByIgnition" SG_ 267 MO_rel_Saugrohrdruck "No";
BA_ "Fehlerwert" SG_ 267 MO_rel_Saugrohrdruck 63;
BA_ "GenSigSendType" SG_ 267 MO_rel_Saugrohrdruck_gem_err "Cyclic";
BA_ "GenSigSwitchedByIgnition" SG_ 267 MO_rel_Saugrohrdruck_gem_err "No";
BA_ "GenSigSendType" SG_ 267 MO_Moment_im_Leerlauf "Cyclic";
BA_ "GenSigSwitchedByIgnition" SG_ 267 MO_Moment_im_Leerlauf "No";
BA_ "GenSigSendType" SG_ 267 MO_Schubabschaltung "Cyclic";
BA_ "GenSigSwitchedByIgnition" SG_ 267 MO_Schubabschaltung "No";
BA_ "GenSigSendType" SG_ 267 MO_Solldrehz_Leerlauf "Cyclic";
BA_ "GenSigSwitchedByIgnition" SG_ 267 MO_Solldrehz_Leerlauf "No";
BA_ "GenSigSendType" SG_ 267 MO_Entkopplung_Sollschlupf "Cyclic";
BA_ "GenSigStartValue" SG_ 267 MO_Entkopplung_Sollschlupf 126;
BA_ "GenSigSwitchedByIgnition" SG_ 267 MO_Entkopplung_Sollschlupf "No";
BA_ "GenSigSendType" SG_ 267 MO_temporaere_Fahrerabwesenheit "Cyclic";
BA_ "GenSigSwitchedByIgnition" SG_ 267 MO_temporaere_Fahrerabwesenheit "No";
BA_ "GenSigSendType" SG_ 267 TSK_a_Soll_gradientenbegrenzt "Cyclic";
BA_ "GenSigStartValue" SG_ 267 TSK_a_Soll_gradientenbegrenzt 127;
BA_ "GenSigSwitchedByIgnition" SG_ 267 TSK_a_Soll_gradientenbegrenzt "No";
BA_ "GenSigSendType" SG_ 267 TSK_Radbremsmom "Cyclic";
BA_ "GenSigSwitchedByIgnition" SG_ 267 TSK_Radbremsmom "No";
BA_ "GenSigSendType" SG_ 267 TSK_Status "Cyclic";
BA_ "GenSigStartValue" SG_ 267 TSK_Status 1;
BA_ "GenSigSwitchedByIgnition" SG_ 267 TSK_Status "No";
BA_ "GenSigSendType" SG_ 267 TSK_v_Begrenzung_aktiv "Cyclic";
BA_ "GenSigSwitchedByIgnition" SG_ 267 TSK_v_Begrenzung_aktiv "No";
BA_ "GenSigSendType" SG_ 267 TSK_Standby_Anf_ESP "Cyclic";
BA_ "GenSigSwitchedByIgnition" SG_ 267 TSK_Standby_Anf_ESP "No";
BA_ "GenSigSendType" SG_ 267 TSK_Freig_WU "Cyclic";
BA_ "GenSigSwitchedByIgnition" SG_ 267 TSK_Freig_WU "No";
BA_ "GenSigSendType" SG_ 267 TSK_Freig_Verzoeg_Anf "Cyclic";
BA_ "GenSigSwitchedByIgnition" SG_ 267 TSK_Freig_Verzoeg_Anf "No";
BA_ "GenSigSendType" SG_ 267 TSK_Limiter_ausgewaehlt "Cyclic";
BA_ "GenSigSwitchedByIgnition" SG_ 267 TSK_Limiter_ausgewaehlt "No";
BA_ "GenSigSendType" SG_ 267 TSK_Wunsch_Uebersetz "Cyclic";
BA_ "GenSigSwitchedByIgnition" SG_ 267 TSK_Wunsch_Uebersetz "No";
BA_ "GenSigSendType" SG_ 267 TSK_Hauptschalter_GRA_ACC "Cyclic";
BA_ "GenSigSwitchedByIgnition" SG_ 267 TSK_Hauptschalter_GRA_ACC "No";
BA_ "Fehlerwert" SG_ 267 TSK_Hauptschalter_GRA_ACC 3;
BA_ "GenSigSendType" SG_ 267 TSK_SRBM_Anf_ASIL "Cyclic";
BA_ "GenSigSwitchedByIgnition" SG_ 267 TSK_SRBM_Anf_ASIL "No";
BA_ "GenSigSendType" SG_ 267 TSK_ax_Getriebe_02 "Cyclic";
BA_ "GenSigStartValue" SG_ 267 TSK_ax_Getriebe_02 511;
BA_ "GenSigSwitchedByIgnition" SG_ 267 TSK_ax_Getriebe_02 "No";
BA_ "GenSigSendType" SG_ 267 TSK_Zwangszusch_ESP "Cyclic";
BA_ "GenSigSwitchedByIgnition" SG_ 267 TSK_Zwangszusch_ESP "No";
BA_ "GenSigSendType" SG_ 267 TSK_zul_Regelabw "Cyclic";
BA_ "GenSigSwitchedByIgnition" SG_ 267 TSK_zul_Regelabw "No";
BA_ "GenSigSendType" SG_ 267 MO_Status_MinDrzEingriff "Cyclic";
BA_ "GenSigSwitchedByIgnition" SG_ 267 MO_Status_MinDrzEingriff "No";
BA_ "GenSigSendType" SG_ 267 MO_Status_MaxDrzEingriff "Cyclic";
BA_ "GenSigSwitchedByIgnition" SG_ 267 MO_Status_MaxDrzEingriff "No";
BA_ "GenSigSendType" SG_ 267 MO_Status_MinDrzEingriff_sek "Cyclic";
BA_ "GenSigSwitchedByIgnition" SG_ 267 MO_Status_MinDrzEingriff_sek "No";
BA_ "GenSigSendType" SG_ 267 MO_Status_MaxDrzEingriff_sek "Cyclic";
BA_ "GenSigSwitchedByIgnition" SG_ 267 MO_Status_MaxDrzEingriff_sek "No";
BA_ "GenSigSendType" SG_ 267 GRA_KuFu_aktiv "Cyclic";
BA_ "GenSigSwitchedByIgnition" SG_ 267 GRA_KuFu_aktiv "No";
BA_ "GenSigSendType" SG_ 267 TSK_SRBM_max_Gradient "Cyclic";
BA_ "GenSigStartValue" SG_ 267 TSK_SRBM_max_Gradient 126;
BA_ "GenSigSwitchedByIgnition" SG_ 267 TSK_SRBM_max_Gradient "No";
BA_ "Fehlerwert" SG_ 267 TSK_SRBM_max_Gradient 127;
BA_ "GenSigSendType" SG_ 267 LIM_KuFu_aktiv "Cyclic";
BA_ "GenSigSwitchedByIgnition" SG_ 267 LIM_KuFu_aktiv "No";
BA_ "GenSigSendType" SG_ 330 MO_Hochschaltdrehz "Cyclic";
BA_ "GenSigSwitchedByIgnition" SG_ 330 MO_Hochschaltdrehz "No";
BA_ "Fehlerwert" SG_ 330 MO_Hochschaltdrehz 4095;
BA_ "GenSigSendType" SG_ 330 MO_Anzeige_Verbr_Einheit "Cyclic";
BA_ "GenSigSwitchedByIgnition" SG_ 330 MO_Anzeige_Verbr_Einheit "No";
BA_ "GenSigSendType" SG_ 330 MO_Schaltblitz_Anz "Cyclic";
BA_ "GenSigStartValue" SG_ 330 MO_Schaltblitz_Anz 126;
BA_ "GenSigSwitchedByIgnition" SG_ 330 MO_Schaltblitz_Anz "No";
BA_ "Fehlerwert" SG_ 330 MO_Schaltblitz_Anz 127;
BA_ "GenSigSendType" SG_ 330 MO_Anzeige_Drehmoment "Cyclic";
BA_ "GenSigSwitchedByIgnition" SG_ 330 MO_Anzeige_Drehmoment "No";
BA_ "Fehlerwert" SG_ 330 MO_Anzeige_Drehmoment 2047;
BA_ "GenSigSendType" SG_ 330 MO_Anzeige_Leistung "Cyclic";
BA_ "GenSigSwitchedByIgnition" SG_ 330 MO_Anzeige_Leistung "No";
BA_ "Fehlerwert" SG_ 330 MO_Anzeige_Leistung 2047;
BA_ "GenSigSendType" SG_ 330 MO_rel_Ladedruck "Cyclic";
BA_ "GenSigSwitchedByIgnition" SG_ 330 MO_rel_Ladedruck "No";
BA_ "Fehlerwert" SG_ 330 MO_rel_Ladedruck 255;
BA_ "GenSigSendType" SG_ 330 MO_Istgang "Cyclic";
BA_ "GenSigSwitchedByIgnition" SG_ 330 MO_Istgang "No";
BA_ "GenSigSendType" SG_ 330 MO_Sollgang "Cyclic";
BA_ "GenSigSwitchedByIgnition" SG_ 330 MO_Sollgang "No";
BA_ "GenSigSendType" SG_ 330 MO_Oeldruck "Cyclic";
BA_ "GenSigStartValue" SG_ 330 MO_Oeldruck 254;
BA_ "GenSigSwitchedByIgnition" SG_ 330 MO_Oeldruck "No";
BA_ "Fehlerwert" SG_ 330 MO_Oeldruck 255;
BA_ "GenSigSendType" SG_ 330 MO_Anzeigedrehz "Cyclic";
BA_ "GenSigSwitchedByIgnition" SG_ 330 MO_Anzeigedrehz "No";
BA_ "GenSigSendType" SG_ 330 MO_Effizienzmodus "Cyclic";
BA_ "GenSigSwitchedByIgnition" SG_ 330 MO_Effizienzmodus "No";
BA_ "GenSigSendType" SG_ 330 MO_Fehler_Oeldrucksensor "Cyclic";
BA_ "GenSigSwitchedByIgnition" SG_ 330 MO_Fehler_Oeldrucksensor "No";
BA_ "Fehlerwert" SG_ 330 MO_Fehler_Oeldrucksensor 1;
BA_ "GenSigSendType" SG_ 330 MO_Schaltempf_verfbar "Cyclic";
BA_ "GenSigSwitchedByIgnition" SG_ 330 MO_Schaltempf_verfbar "No";
BA_ "GenSigSendType" SG_ 330 MO_Ladedruck "Cyclic";
BA_ "GenSigSwitchedByIgnition" SG_ 330 MO_Ladedruck "No";
BA_ "Fehlerwert" SG_ 330 MO_Ladedruck 511;
BA_ "GenSigSendType" SG_ 330 MO_KVS "Cyclic";
BA_ "GenSigSwitchedByIgnition" SG_ 330 MO_KVS "No";
BA_ "GenSigSendType" SG_ 330 MO_KVS_Ueberlauf "Cyclic";
BA_ "GenSigSwitchedByIgnition" SG_ 330 MO_KVS_Ueberlauf "No";
BA_ "GenSigSendType" SG_ 330 MO_ePowermeter "Cyclic";
BA_ "GenSigSwitchedByIgnition" SG_ 330 MO_ePowermeter "No";
BA_ "GenSigSendType" SG_ 330 MO_ePerformance "Cyclic";
BA_ "GenSigSwitchedByIgnition" SG_ 330 MO_ePerformance "No";
BA_ "Fehlerwert" SG_ 330 MO_ePerformance 255;
BA_ "GenSigSendType" SG_ 330 MO_Zust_Antrieb "Cyclic";
BA_ "GenSigSwitchedByIgnition" SG_ 330 MO_Zust_Antrieb "No";
BA_ "GenSigSendType" SG_ 330 MO_Zust_Betriebsstrategie "Cyclic";
BA_ "GenSigSwitchedByIgnition" SG_ 330 MO_Zust_Betriebsstrategie "No";
BA_ "GenSigSendType" SG_ 330 Ladezustand_02 "Cyclic";
BA_ "GenSigStartValue" SG_ 330 Ladezustand_02 254;
BA_ "GenSigSwitchedByIgnition" SG_ 330 Ladezustand_02 "No";
BA_ "Fehlerwert" SG_ 330 Ladezustand_02 255;
BA_ "GenSigSendType" SG_ 330 MO_Powermeter_Elm_02 "Cyclic";
BA_ "GenSigStartValue" SG_ 330 MO_Powermeter_Elm_02 4094;
BA_ "GenSigSwitchedByIgnition" SG_ 330 MO_Powermeter_Elm_02 "No";
BA_ "GenSigSendType" SG_ 330 MO_Powermeter "Cyclic";
BA_ "GenSigStartValue" SG_ 330 MO_Powermeter 4093;
BA_ "GenSigSwitchedByIgnition" SG_ 330 MO_Powermeter "No";
BA_ "GenSigSendType" SG_ 512 TSK_Wunschgeschw "Cyclic";
BA_ "GenSigSwitchedByIgnition" SG_ 512 TSK_Wunschgeschw "No";
BA_ "GenSigSendType" SG_ 512 TSK_praediktiver_Hinweis "Cyclic";
BA_ "GenSigSwitchedByIgnition" SG_ 512 TSK_praediktiver_Hinweis "No";
BA_ "GenSigSendType" SG_ 512 TSK_naechstes_Event "Cyclic";
BA_ "GenSigSwitchedByIgnition" SG_ 512 TSK_naechstes_Event "No";
BA_ "GenSigSendType" SG_ 512 TSK_Fahrzeugstatus_praed_Fkt "Cyclic";
BA_ "GenSigSwitchedByIgnition" SG_ 512 TSK_Fahrzeugstatus_praed_Fkt "No";
BA_ "GenSigSendType" SG_ 512 TSK_Texte "Cyclic";
BA_ "GenSigSwitchedByIgnition" SG_ 512 TSK_Texte "No";
BA_ "GenSigSendType" SG_ 512 TSK_Akustik "Cyclic";
BA_ "GenSigSwitchedByIgnition" SG_ 512 TSK_Akustik "No";
BA_ "GenSigSendType" SG_ 512 TSK_Texte_Primaeranz "Cyclic";
BA_ "GenSigSwitchedByIgnition" SG_ 512 TSK_Texte_Primaeranz "No";
BA_ "GenSigSendType" SG_ 512 TSK_Limiter_Fahrerinfo "Cyclic";
BA_ "GenSigSwitchedByIgnition" SG_ 512 TSK_Limiter_Fahrerinfo "No";
BA_ "GenSigSendType" SG_ 512 TSK_Limiter_Anzeige "Cyclic";
BA_ "GenSigSwitchedByIgnition" SG_ 512 TSK_Limiter_Anzeige "No";
BA_ "GenSigSendType" SG_ 512 TSK_Fahrzeugstatus_GRA "Cyclic";
BA_ "GenSigSwitchedByIgnition" SG_ 512 TSK_Fahrzeugstatus_GRA "No";
BA_ "GenSigSendType" SG_ 512 TSK_Fahrzeugstatus_Limiter "Cyclic";
BA_ "GenSigSwitchedByIgnition" SG_ 512 TSK_Fahrzeugstatus_Limiter "No";
BA_ "GenSigSendType" SG_ 512 MO_Motorlaufwarnung "Cyclic";
BA_ "GenSigSwitchedByIgnition" SG_ 512 MO_Motorlaufwarnung "No";
BA_ "GenSigSendType" SG_ 512 TSK_naechstes_Event_Einheit "Cyclic";
BA_ "GenSigSwitchedByIgnition" SG_ 512 TSK_naechstes_Event_Einheit "No";
BA_ "GenSigSendType" SG_ 512 TSK_Status_Anzeige "Cyclic";
BA_ "GenSigStartValue" SG_ 512 TSK_Status_Anzeige 1;
BA_ "GenSigSwitchedByIgnition" SG_ 512 TSK_Status_Anzeige "No";
BA_ "GenSigSendType" SG_ 512 MO_Sperrung_FahrPr_BZS "Cyclic";
BA_ "GenSigSwitchedByIgnition" SG_ 512 MO_Sperrung_FahrPr_BZS "No";
BA_ "GenSigSendType" SG_ 512 MO_Rampenzeit_Generator_Anf "Cyclic";
BA_ "GenSigStartValue" SG_ 512 MO_Rampenzeit_Generator_Anf 15;
BA_ "GenSigSwitchedByIgnition" SG_ 512 MO_Rampenzeit_Generator_Anf "No";
BA_ "GenSigSendType" SG_ 512 MO_Prio_MAX_Wunschdrehzahl "Cyclic";
BA_ "GenSigSwitchedByIgnition" SG_ 512 MO_Prio_MAX_Wunschdrehzahl "No";
BA_ "GenSigSendType" SG_ 512 MO_Prio_MIN_Wunschdrehzahl "Cyclic";
BA_ "GenSigSwitchedByIgnition" SG_ 512 MO_Prio_MIN_Wunschdrehzahl "No";
BA_ "GenSigSendType" SG_ 512 MO_Luftpfad_aktiv "Cyclic";
BA_ "GenSigSwitchedByIgnition" SG_ 512 MO_Luftpfad_aktiv "No";
BA_ "GenSigSendType" SG_ 512 MO_v_Begrenz_Aktivierbar "Cyclic";
BA_ "GenSigSwitchedByIgnition" SG_ 512 MO_v_Begrenz_Aktivierbar "No";
BA_ "GenSigSendType" SG_ 512 MO_Drehzahlbeeinflussung "Cyclic";
BA_ "GenSigSwitchedByIgnition" SG_ 512 MO_Drehzahlbeeinflussung "No";
BA_ "GenSigSendType" SG_ 512 MO_MIN_Wunschdrehzahl "Cyclic";
BA_ "GenSigSwitchedByIgnition" SG_ 512 MO_MIN_Wunschdrehzahl "No";
BA_ "GenSigSendType" SG_ 512 MO_MAX_Wunschdrehzahl "Cyclic";
BA_ "GenSigSwitchedByIgnition" SG_ 512 MO_MAX_Wunschdrehzahl "No";
BA_ "GenSigSendType" SG_ 512 MO_Charisma_FahrPr "Cyclic";
BA_ "GenSigSwitchedByIgnition" SG_ 512 MO_Charisma_FahrPr "No";
BA_ "GenSigSendType" SG_ 512 MO_Charisma_Status "Cyclic";
BA_ "GenSigSwitchedByIgnition" SG_ 512 MO_Charisma_Status "No";
BA_ "GenSigSendType" SG_ 512 MO_StSt_Charisma_FahrPr "Cyclic";
BA_ "GenSigSwitchedByIgnition" SG_ 512 MO_StSt_Charisma_FahrPr "No";
BA_ "GenSigSendType" SG_ 512 MO_StSt_Charisma_Status "Cyclic";
BA_ "GenSigSwitchedByIgnition" SG_ 512 MO_StSt_Charisma_Status "No";
BA_ "GenSigSendType" SG_ 512 MO_BZS_Charisma_FahrPr "Cyclic";
BA_ "GenSigSwitchedByIgnition" SG_ 512 MO_BZS_Charisma_FahrPr "No";
BA_ "GenSigSendType" SG_ 512 MO_BZS_Charisma_Status "Cyclic";
BA_ "GenSigSwitchedByIgnition" SG_ 512 MO_BZS_Charisma_Status "No";
BA_ "GenSigSendType" SG_ 512 MO_NGS_Position "Cyclic";
BA_ "GenSigSwitchedByIgnition" SG_ 512 MO_NGS_Position "No";
BA_ "GenSigSendType" SG_ 512 MO_NGS_Status "Cyclic";
BA_ "GenSigSwitchedByIgnition" SG_ 512 MO_NGS_Status "No";
BA_ "Fehlerwert" SG_ 512 MO_NGS_Status 3;
BA_ "GenSigSendType" SG_ 512 MO_v_Begrenzung_Niveau "Cyclic";
BA_ "GenSigSwitchedByIgnition" SG_ 512 MO_v_Begrenzung_Niveau "No";
BA_ "GenSigSendType" SG_ 512 MO_Anzeige_Rekuperation "Cyclic";
BA_ "GenSigSwitchedByIgnition" SG_ 512 MO_Anzeige_Rekuperation "No";
BA_ "GenSigSendType" SG_ 512 PEA_Fortschrittsanzeige "Cyclic";
BA_ "GenSigStartValue" SG_ 512 PEA_Fortschrittsanzeige 127;
BA_ "GenSigSwitchedByIgnition" SG_ 512 PEA_Fortschrittsanzeige "No";
BA_ "GenSigSendType" SG_ 512 MO_Anzeige_Fahrbereitschaft "Cyclic";
BA_ "GenSigSwitchedByIgnition" SG_ 512 MO_Anzeige_Fahrbereitschaft "No";
BA_ "GenSigSendType" SG_ 512 MO_Boost_verfuegbar "Cyclic";
BA_ "GenSigSwitchedByIgnition" SG_ 512 MO_Boost_verfuegbar "No";
BA_ "Fehlerwert" SG_ 512 MO_Boost_verfuegbar 255;
BA_ "GenSigSendType" SG_ 512 MO_Overboost "Cyclic";
BA_ "GenSigSwitchedByIgnition" SG_ 512 MO_Overboost "No";
BA_ "GenSigSendType" SG_ 512 MO_Boost_aktiv "Cyclic";
BA_ "GenSigSwitchedByIgnition" SG_ 512 MO_Boost_aktiv "No";
BA_ "GenSigSendType" SG_ 512 MO_Anzeige_Betriebsmodus "Cyclic";
BA_ "GenSigSwitchedByIgnition" SG_ 512 MO_Anzeige_Betriebsmodus "No";
BA_ "GenSigSendType" SG_ 512 PEA_Hinweis "Cyclic";
BA_ "GenSigSwitchedByIgnition" SG_ 512 PEA_Hinweis "No";
BA_ "GenSigSendType" SG_ 512 PEA_Ereignisanzeige "Cyclic";
BA_ "GenSigSwitchedByIgnition" SG_ 512 PEA_Ereignisanzeige "No";
BA_ "GenSigSendType" SG_ 512 PEA_Ereignisanzeige_temporaer "Cyclic";
BA_ "GenSigSwitchedByIgnition" SG_ 512 PEA_Ereignisanzeige_temporaer "No";
BA_ "GenSigSendType" SG_ 512 PEA_Abschalttexte "Cyclic";
BA_ "GenSigSwitchedByIgnition" SG_ 512 PEA_Abschalttexte "No";
BA_ "GenSigSendType" SG_ 512 PEA_Zielgeschw_Einheit "Cyclic";
BA_ "GenSigSwitchedByIgnition" SG_ 512 PEA_Zielgeschw_Einheit "No";
BA_ "GenSigSendType" SG_ 512 PEA_Zielgeschw "Cyclic";
BA_ "GenSigSwitchedByIgnition" SG_ 512 PEA_Zielgeschw "No";
BA_ "GenSigSendType" SG_ 512 MO_Antriebsstrang_Warnung_HS "Cyclic";
BA_ "GenSigSwitchedByIgnition" SG_ 512 MO_Antriebsstrang_Warnung_HS "No";
BA_ "GenSigSendType" SG_ 512 MO_Anzeige_Verbrauch_oE "Cyclic";
BA_ "GenSigSwitchedByIgnition" SG_ 512 MO_Anzeige_Verbrauch_oE "No";
BA_ "GenSigSendType" SG_ 332 MO_Anforderung_HMS "OnChange";
BA_ "GenSigSwitchedByIgnition" SG_ 332 MO_Anforderung_HMS "No";
BA_ "GenSigSendType" SG_ 332 FoD_DTC_TSK_GRA "Cyclic";
BA_ "GenSigSwitchedByIgnition" SG_ 332 FoD_DTC_TSK_GRA "No";
BA_ "GenSigSendType" SG_ 332 TSK_vMax_aktuell "Cyclic";
BA_ "GenSigStartValue" SG_ 332 TSK_vMax_aktuell 255;
BA_ "GenSigSendType" SG_ 332 TSK_Status_EA "OnChange";
BA_ "GenSigStartValue" SG_ 332 TSK_Status_EA 1;
BA_ "GenSigSwitchedByIgnition" SG_ 332 TSK_Status_EA "No";
BA_ "Fehlerwert" SG_ 332 TSK_Status_EA 7;
BA_ "GenSigSendType" SG_ 332 FoD_DTC_TSK_ACC "Cyclic";
BA_ "GenSigSwitchedByIgnition" SG_ 332 FoD_DTC_TSK_ACC "No";
BA_ "GenSigSendType" SG_ 332 TSK_ACC_FoD_Status "Cyclic";
BA_ "GenSigSwitchedByIgnition" SG_ 332 TSK_ACC_FoD_Status "No";
BA_ "GenSigSendType" SG_ 332 TSK_GRA_FoD_Status "Cyclic";
BA_ "GenSigSwitchedByIgnition" SG_ 332 TSK_GRA_FoD_Status "No";
BA_ "GenSigSendType" SG_ 332 TSK_vMax_Fahrerassistenz "Cyclic";
BA_ "GenSigStartValue" SG_ 332 TSK_vMax_Fahrerassistenz 511;
BA_ "GenSigSwitchedByIgnition" SG_ 332 TSK_vMax_Fahrerassistenz "No";
BA_ "GenSigSendType" SG_ 332 TSK_Einheit_vMax_Fahrerassistenz "Cyclic";
BA_ "GenSigSwitchedByIgnition" SG_ 332 TSK_Einheit_vMax_Fahrerassistenz "No";
BA_ "GenSigSendType" SG_ 332 TSK_Status_PLA "OnChange";
BA_ "GenSigStartValue" SG_ 332 TSK_Status_PLA 1;
BA_ "GenSigSwitchedByIgnition" SG_ 332 TSK_Status_PLA "No";
BA_ "Fehlerwert" SG_ 332 TSK_Status_PLA 7;
BA_ "GenSigSendType" SG_ 332 TSK_aktives_System "OnChange";
BA_ "GenSigSwitchedByIgnition" SG_ 332 TSK_aktives_System "No";
BA_ "GenSigSendType" SG_ 332 TSK_erhoehter_Fahrwiderstand "OnChange";
BA_ "GenSigSwitchedByIgnition" SG_ 332 TSK_erhoehter_Fahrwiderstand "No";
BA_ "GenSigSendType" SG_ 332 TSK_Anf_Antriebsmoment "OnChange";
BA_ "GenSigSwitchedByIgnition" SG_ 332 TSK_Anf_Antriebsmoment "No";
BA_ "GenSigSendType" SG_ 332 TSK_Status_ARA "OnChange";
BA_ "GenSigStartValue" SG_ 332 TSK_Status_ARA 1;
BA_ "GenSigSwitchedByIgnition" SG_ 332 TSK_Status_ARA "No";
BA_ "Fehlerwert" SG_ 332 TSK_Status_ARA 7;
BA_ "GenSigSendType" SG_ 332 TSK_Status_IPA "OnChange";
BA_ "GenSigStartValue" SG_ 332 TSK_Status_IPA 1;
BA_ "GenSigSwitchedByIgnition" SG_ 332 TSK_Status_IPA "No";
BA_ "Fehlerwert" SG_ 332 TSK_Status_IPA 7;
BA_ "GenSigSendType" SG_ 332 MO_Fahrbereitschaft "OnChange";
BA_ "GenSigSwitchedByIgnition" SG_ 332 MO_Fahrbereitschaft "No";
BA_ "GenSigSendType" SG_ 332 MO_Freilauf_Info "OnChange";
BA_ "GenSigSwitchedByIgnition" SG_ 332 MO_Freilauf_Info "No";
BA_ "GenSigSendType" SG_ 332 MO_Krit_Heckobjekt "Cyclic";
BA_ "GenSigSwitchedByIgnition" SG_ 332 MO_Krit_Heckobjekt "No";
BA_ "Fehlerwert" SG_ 332 MO_Krit_Heckobjekt 7;
BA_ "GenSigSendType" SG_ 332 MO_NGS_Gangpos "OnChange";
BA_ "GenSigSwitchedByIgnition" SG_ 332 MO_NGS_Gangpos "No";
BA_ "Fehlerwert" SG_ 332 MO_NGS_Gangpos 7;
BA_ "GenSigSendType" SG_ 332 MO_Freilauf_Status "OnChange";
BA_ "GenSigSwitchedByIgnition" SG_ 332 MO_Freilauf_Status "No";
BA_ "Fehlerwert" SG_ 332 MO_Freilauf_Status 7;
BA_ "GenSigSendType" SG_ 332 MO_EBoost_verf_praed "Cyclic";
BA_ "GenSigSwitchedByIgnition" SG_ 332 MO_EBoost_verf_praed "No";
BA_ "GenSigSendType" SG_ 332 MO_Heckspoiler_Anf "Cyclic";
BA_ "GenSigSwitchedByIgnition" SG_ 332 MO_Heckspoiler_Anf "No";
BA_ "GenSigSendType" SG_ 332 MO_eLaunch_verf "Cyclic";
BA_ "GenSigSwitchedByIgnition" SG_ 332 MO_eLaunch_verf "No";
BA_ "GenSigSendType" SG_ 332 MO_Positionierung_aktiv "Cyclic";
BA_ "GenSigSwitchedByIgnition" SG_ 332 MO_Positionierung_aktiv "No";
BA_ "GenSigSendType" SG_ 332 MO_Freilauf_Typ "Cyclic";
BA_ "GenSigSwitchedByIgnition" SG_ 332 MO_Freilauf_Typ "No";
BA_ "GenSigSendType" SG_ 332 MO_Startwunsch "OnChange";
BA_ "GenSigSwitchedByIgnition" SG_ 332 MO_Startwunsch "No";
BA_ "GenSigSendType" SG_ 332 OBD_Calc_Load_Val "Cyclic";
BA_ "GenSigStartValue" SG_ 332 OBD_Calc_Load_Val 255;
BA_ "GenSigSwitchedByIgnition" SG_ 332 OBD_Calc_Load_Val "No";
BA_ "GenSigSendType" SG_ 332 OBD_Eng_Cool_Temp "Cyclic";
BA_ "GenSigStartValue" SG_ 332 OBD_Eng_Cool_Temp 255;
BA_ "GenSigSwitchedByIgnition" SG_ 332 OBD_Eng_Cool_Temp "No";
BA_ "GenSigSendType" SG_ 332 OBD_Abs_Throttle_Pos "Cyclic";
BA_ "GenSigStartValue" SG_ 332 OBD_Abs_Throttle_Pos 255;
BA_ "GenSigSwitchedByIgnition" SG_ 332 OBD_Abs_Throttle_Pos "No";
BA_ "GenSigSendType" SG_ 332 OBD_Abs_Load_Val "Cyclic";
BA_ "GenSigStartValue" SG_ 332 OBD_Abs_Load_Val 65535;
BA_ "GenSigSwitchedByIgnition" SG_ 332 OBD_Abs_Load_Val "No";
BA_ "GenSigSendType" SG_ 332 OBD_Abs_Pedal_Pos "Cyclic";
BA_ "GenSigStartValue" SG_ 332 OBD_Abs_Pedal_Pos 255;
BA_ "GenSigSwitchedByIgnition" SG_ 332 OBD_Abs_Pedal_Pos "No";
BA_ "GenSigSendType" SG_ 332 MO_Servicemodus "Cyclic";
BA_ "GenSigSwitchedByIgnition" SG_ 332 MO_Servicemodus "No";
BA_ "GenSigSendType" SG_ 332 OBD_ClearMem_Inhibit "Cyclic";
BA_ "GenSigSwitchedByIgnition" SG_ 332 OBD_ClearMem_Inhibit "No";
BA_ "GenSigSendType" SG_ 332 OBD_Sperrung_Kaltstart_Denom "Cyclic";
BA_ "GenSigSwitchedByIgnition" SG_ 332 OBD_Sperrung_Kaltstart_Denom "No";
BA_ "GenSigSendType" SG_ 332 MO_QBit_Aussen_Temp "Cyclic";
BA_ "GenSigStartValue" SG_ 332 MO_QBit_Aussen_Temp 1;
BA_ "GenSigSwitchedByIgnition" SG_ 332 MO_QBit_Aussen_Temp "No";
BA_ "GenSigSendType" SG_ 332 OBD_Sperrung_IUMPR "Cyclic";
BA_ "GenSigSwitchedByIgnition" SG_ 332 OBD_Sperrung_IUMPR "No";
BA_ "GenSigSendType" SG_ 332 OBD_Kaltstart_Denominator "Cyclic";
BA_ "GenSigSwitchedByIgnition" SG_ 332 OBD_Kaltstart_Denominator "No";
BA_ "GenSigSendType" SG_ 332 OBD_Minimum_Trip "Cyclic";
BA_ "GenSigSwitchedByIgnition" SG_ 332 OBD_Minimum_Trip "No";
BA_ "GenSigSendType" SG_ 332 OBD_Driving_Cycle "Cyclic";
BA_ "GenSigSwitchedByIgnition" SG_ 332 OBD_Driving_Cycle "No";
BA_ "GenSigSendType" SG_ 332 OBD_Warm_Up_Cycle "Cyclic";
BA_ "GenSigSwitchedByIgnition" SG_ 332 OBD_Warm_Up_Cycle "No";
BA_ "GenSigSendType" SG_ 332 OBD_Normed_Trip "Cyclic";
BA_ "GenSigSwitchedByIgnition" SG_ 332 OBD_Normed_Trip "No";
BA_ "GenSigSendType" SG_ 332 OBD_Aussen_Temp_gef "Cyclic";
BA_ "GenSigStartValue" SG_ 332 OBD_Aussen_Temp_gef 254;
BA_ "GenSigSwitchedByIgnition" SG_ 332 OBD_Aussen_Temp_gef "No";
BA_ "Fehlerwert" SG_ 332 OBD_Aussen_Temp_gef 255;
BA_ "GenSigSendType" SG_ 246 Motor_55_CRC "Cyclic";
BA_ "GenSigFuncType" SG_ 246 Motor_55_CRC "CRC-8";
BA_ "GenSigSwitchedByIgnition" SG_ 246 Motor_55_CRC "No";
BA_ "GenSigSendType" SG_ 246 Motor_55_BZ "Cyclic";
BA_ "GenSigFuncType" SG_ 246 Motor_55_BZ "MsgCounter";
BA_ "GenSigSwitchedByIgnition" SG_ 246 Motor_55_BZ "No";
BA_ "GenSigSendType" SG_ 246 TS_Faktor_Radmomente "Cyclic";
BA_ "GenSigSwitchedByIgnition" SG_ 246 TS_Faktor_Radmomente "No";
BA_ "GenSigSendType" SG_ 246 TS_Status_MomRad_Ist "Cyclic";
BA_ "GenSigStartValue" SG_ 246 TS_Status_MomRad_Ist 2;
BA_ "GenSigSwitchedByIgnition" SG_ 246 TS_Status_MomRad_Ist "No";
BA_ "GenSigSendType" SG_ 246 TS_MomRad_verfuegb_maxReku_Summe "Cyclic";
BA_ "GenSigStartValue" SG_ 246 TS_MomRad_verfuegb_maxReku_Summe 4094;
BA_ "GenSigSwitchedByIgnition" SG_ 246 TS_MomRad_verfuegb_maxReku_Summe "No";
BA_ "Fehlerwert" SG_ 246 TS_MomRad_verfuegb_maxReku_Summe 4095;
BA_ "GenSigSendType" SG_ 246 TS_MomRad_Ist "Cyclic";
BA_ "GenSigStartValue" SG_ 246 TS_MomRad_Ist 8190;
BA_ "GenSigSwitchedByIgnition" SG_ 246 TS_MomRad_Ist "No";
BA_ "GenSigSendType" SG_ 246 TS_MomRad_Soll_Summe "Cyclic";
BA_ "GenSigStartValue" SG_ 246 TS_MomRad_Soll_Summe 8190;
BA_ "GenSigSwitchedByIgnition" SG_ 246 TS_MomRad_Soll_Summe "No";
BA_ "GenSigSendType" SG_ 246 TS_MomRad_Wunsch "Cyclic";
BA_ "GenSigStartValue" SG_ 246 TS_MomRad_Wunsch 8190;
BA_ "GenSigSwitchedByIgnition" SG_ 246 TS_MomRad_Wunsch "No";
BA_ "GenSigSendType" SG_ 246 TS_MomRad_Wunsch_sek "Cyclic";
BA_ "GenSigStartValue" SG_ 246 TS_MomRad_Wunsch_sek 8190;
BA_ "GenSigSwitchedByIgnition" SG_ 246 TS_MomRad_Wunsch_sek "No";
BA_ "Fehlerwert" SG_ 246 TS_MomRad_Wunsch_sek 8191;
BA_ "GenSigSendType" SG_ 246 TS_MomRad_verfuegb_max "Cyclic";
BA_ "GenSigStartValue" SG_ 246 TS_MomRad_verfuegb_max 4094;
BA_ "GenSigSwitchedByIgnition" SG_ 246 TS_MomRad_verfuegb_max "No";
BA_ "GenSigSendType" SG_ 246 TS_MomRad_verfuegb_max_sek "Cyclic";
BA_ "GenSigStartValue" SG_ 246 TS_MomRad_verfuegb_max_sek 4094;
BA_ "GenSigSwitchedByIgnition" SG_ 246 TS_MomRad_verfuegb_max_sek "No";
BA_ "Fehlerwert" SG_ 246 TS_MomRad_verfuegb_max_sek 4095;
BA_ "GenSigSendType" SG_ 246 TS_MomRad_verfuegb_maxReku "Cyclic";
BA_ "GenSigStartValue" SG_ 246 TS_MomRad_verfuegb_maxReku 4094;
BA_ "GenSigSwitchedByIgnition" SG_ 246 TS_MomRad_verfuegb_maxReku "No";
BA_ "GenSigSendType" SG_ 246 TS_MomRad_verfuegb_maxReku_sek "Cyclic";
BA_ "GenSigStartValue" SG_ 246 TS_MomRad_verfuegb_maxReku_sek 4094;
BA_ "GenSigSwitchedByIgnition" SG_ 246 TS_MomRad_verfuegb_maxReku_sek "No";
BA_ "Fehlerwert" SG_ 246 TS_MomRad_verfuegb_maxReku_sek 4095;
BA_ "GenSigSendType" SG_ 246 TS_MomRad_Ist_sek "Cyclic";
BA_ "GenSigStartValue" SG_ 246 TS_MomRad_Ist_sek 8190;
BA_ "GenSigSwitchedByIgnition" SG_ 246 TS_MomRad_Ist_sek "No";
BA_ "Fehlerwert" SG_ 246 TS_MomRad_Ist_sek 8191;
BA_ "GenSigSendType" SG_ 246 TS_Allrad_Anteil_sek "Cyclic";
BA_ "GenSigStartValue" SG_ 246 TS_Allrad_Anteil_sek 510;
BA_ "GenSigSwitchedByIgnition" SG_ 246 TS_Allrad_Anteil_sek "No";
BA_ "Fehlerwert" SG_ 246 TS_Allrad_Anteil_sek 511;
BA_ "GenSigSendType" SG_ 246 FDR_Allrad_Anteil_max_sek "Cyclic";
BA_ "GenSigStartValue" SG_ 246 FDR_Allrad_Anteil_max_sek 510;
BA_ "Fehlerwert" SG_ 246 FDR_Allrad_Anteil_max_sek 511;
BA_ "GenSigSendType" SG_ 246 FDR_Allrad_Anteil_min_sek "Cyclic";
BA_ "GenSigStartValue" SG_ 246 FDR_Allrad_Anteil_min_sek 510;
BA_ "Fehlerwert" SG_ 246 FDR_Allrad_Anteil_min_sek 511;
BA_ "GenSigSendType" SG_ 246 FDR_MomRad_Eingriff "Cyclic";
BA_ "GenSigStartValue" SG_ 246 FDR_MomRad_Eingriff 8190;
BA_ "GenSigSwitchedByIgnition" SG_ 246 FDR_MomRad_Eingriff "No";
BA_ "Fehlerwert" SG_ 246 FDR_MomRad_Eingriff 8191;
BA_ "GenSigSendType" SG_ 246 FDR_Status_Eingriff "Cyclic";
BA_ "GenSigSwitchedByIgnition" SG_ 246 FDR_Status_Eingriff "No";
BA_ "GenSigSendType" SG_ 246 FDR_MomRad_Eingriff_sek "Cyclic";
BA_ "GenSigStartValue" SG_ 246 FDR_MomRad_Eingriff_sek 8190;
BA_ "GenSigSwitchedByIgnition" SG_ 246 FDR_MomRad_Eingriff_sek "No";
BA_ "Fehlerwert" SG_ 246 FDR_MomRad_Eingriff_sek 8191;
BA_ "GenSigSendType" SG_ 246 FDR_Status_Eingriff_sek "Cyclic";
BA_ "GenSigSwitchedByIgnition" SG_ 246 FDR_Status_Eingriff_sek "No";
BA_ "GenSigSendType" SG_ 190 Motor_56_CRC "Cyclic";
BA_ "GenSigFuncType" SG_ 190 Motor_56_CRC "CRC-8";
BA_ "GenSigSwitchedByIgnition" SG_ 190 Motor_56_CRC "No";
BA_ "GenSigSendType" SG_ 190 Motor_56_BZ "Cyclic";
BA_ "GenSigFuncType" SG_ 190 Motor_56_BZ "MsgCounter";
BA_ "GenSigSwitchedByIgnition" SG_ 190 Motor_56_BZ "No";
BA_ "GenSigSendType" SG_ 190 MO_EM1_MinDrehzahl "Cyclic";
BA_ "GenSigStartValue" SG_ 190 MO_EM1_MinDrehzahl 16383;
BA_ "GenSigSwitchedByIgnition" SG_ 190 MO_EM1_MinDrehzahl "No";
BA_ "GenSigSendType" SG_ 190 MO_EM1_MaxDrehzahl "Cyclic";
BA_ "GenSigStartValue" SG_ 190 MO_EM1_MaxDrehzahl 16383;
BA_ "GenSigSwitchedByIgnition" SG_ 190 MO_EM1_MaxDrehzahl "No";
BA_ "GenSigSendType" SG_ 190 MO_EM1_DynLimit_AR "Cyclic";
BA_ "GenSigStartValue" SG_ 190 MO_EM1_DynLimit_AR 255;
BA_ "GenSigSwitchedByIgnition" SG_ 190 MO_EM1_DynLimit_AR "No";
BA_ "GenSigSendType" SG_ 190 MO_EM1_Periode_AR "Cyclic";
BA_ "GenSigStartValue" SG_ 190 MO_EM1_Periode_AR 255;
BA_ "GenSigSwitchedByIgnition" SG_ 190 MO_EM1_Periode_AR "No";
BA_ "GenSigSendType" SG_ 190 MO_EM1_SollMoment "Cyclic";
BA_ "GenSigStartValue" SG_ 190 MO_EM1_SollMoment 4094;
BA_ "GenSigSwitchedByIgnition" SG_ 190 MO_EM1_SollMoment "No";
BA_ "GenSigSendType" SG_ 190 MO_EM1_Sollmodus "Cyclic";
BA_ "GenSigStartValue" SG_ 190 MO_EM1_Sollmodus 15;
BA_ "GenSigSwitchedByIgnition" SG_ 190 MO_EM1_Sollmodus "No";
BA_ "GenSigSendType" SG_ 190 MO_EM1_Min_Leistung "Cyclic";
BA_ "GenSigStartValue" SG_ 190 MO_EM1_Min_Leistung 16382;
BA_ "GenSigSwitchedByIgnition" SG_ 190 MO_EM1_Min_Leistung "No";
BA_ "GenSigSendType" SG_ 190 MO_EM1_Max_Leistung "Cyclic";
BA_ "GenSigStartValue" SG_ 190 MO_EM1_Max_Leistung 16382;
BA_ "GenSigSwitchedByIgnition" SG_ 190 MO_EM1_Max_Leistung "No";
BA_ "GenSigSendType" SG_ 190 MO_EM1_Min_Strom_Lim "Cyclic";
BA_ "GenSigStartValue" SG_ 190 MO_EM1_Min_Strom_Lim 8190;
BA_ "GenSigSwitchedByIgnition" SG_ 190 MO_EM1_Min_Strom_Lim "No";
BA_ "GenSigSendType" SG_ 190 MO_EM1_Max_Strom_Lim "Cyclic";
BA_ "GenSigStartValue" SG_ 190 MO_EM1_Max_Strom_Lim 8190;
BA_ "GenSigSwitchedByIgnition" SG_ 190 MO_EM1_Max_Strom_Lim "No";
BA_ "GenSigSendType" SG_ 190 MO_EM1_AR_Anf "Cyclic";
BA_ "GenSigSwitchedByIgnition" SG_ 190 MO_EM1_AR_Anf "No";
BA_ "GenSigSendType" SG_ 190 MO_EM1_Kp_AR "Cyclic";
BA_ "GenSigStartValue" SG_ 190 MO_EM1_Kp_AR 511;
BA_ "GenSigSwitchedByIgnition" SG_ 190 MO_EM1_Kp_AR "No";
BA_ "GenSigSendType" SG_ 190 MO_EM1_SollSpannung "Cyclic";
BA_ "GenSigStartValue" SG_ 190 MO_EM1_SollSpannung 4095;
BA_ "GenSigSwitchedByIgnition" SG_ 190 MO_EM1_SollSpannung "No";
BA_ "GenSigSendType" SG_ 190 MO_EM2_MinDrehzahl "Cyclic";
BA_ "GenSigStartValue" SG_ 190 MO_EM2_MinDrehzahl 16383;
BA_ "GenSigSwitchedByIgnition" SG_ 190 MO_EM2_MinDrehzahl "No";
BA_ "GenSigSendType" SG_ 190 MO_EM2_MaxDrehzahl "Cyclic";
BA_ "GenSigStartValue" SG_ 190 MO_EM2_MaxDrehzahl 16383;
BA_ "GenSigSwitchedByIgnition" SG_ 190 MO_EM2_MaxDrehzahl "No";
BA_ "GenSigSendType" SG_ 190 MO_EM2_DynLimit_AR "Cyclic";
BA_ "GenSigStartValue" SG_ 190 MO_EM2_DynLimit_AR 255;
BA_ "GenSigSwitchedByIgnition" SG_ 190 MO_EM2_DynLimit_AR "No";
BA_ "GenSigSendType" SG_ 190 MO_EM2_Periode_AR "Cyclic";
BA_ "GenSigStartValue" SG_ 190 MO_EM2_Periode_AR 255;
BA_ "GenSigSwitchedByIgnition" SG_ 190 MO_EM2_Periode_AR "No";
BA_ "GenSigSendType" SG_ 190 MO_EM2_SollMoment "Cyclic";
BA_ "GenSigStartValue" SG_ 190 MO_EM2_SollMoment 4094;
BA_ "GenSigSwitchedByIgnition" SG_ 190 MO_EM2_SollMoment "No";
BA_ "Fehlerwert" SG_ 190 MO_EM2_SollMoment 4095;
BA_ "GenSigSendType" SG_ 190 MO_EM2_Sollmodus "Cyclic";
BA_ "GenSigStartValue" SG_ 190 MO_EM2_Sollmodus 15;
BA_ "GenSigSwitchedByIgnition" SG_ 190 MO_EM2_Sollmodus "No";
BA_ "GenSigSendType" SG_ 190 MO_EM2_Min_Leistung "Cyclic";
BA_ "GenSigStartValue" SG_ 190 MO_EM2_Min_Leistung 16382;
BA_ "GenSigSwitchedByIgnition" SG_ 190 MO_EM2_Min_Leistung "No";
BA_ "GenSigSendType" SG_ 190 MO_EM2_Max_Leistung "Cyclic";
BA_ "GenSigStartValue" SG_ 190 MO_EM2_Max_Leistung 16382;
BA_ "GenSigSwitchedByIgnition" SG_ 190 MO_EM2_Max_Leistung "No";
BA_ "GenSigSendType" SG_ 190 MO_EM2_Min_Strom_Lim "Cyclic";
BA_ "GenSigStartValue" SG_ 190 MO_EM2_Min_Strom_Lim 8190;
BA_ "GenSigSwitchedByIgnition" SG_ 190 MO_EM2_Min_Strom_Lim "No";
BA_ "GenSigSendType" SG_ 190 MO_EM2_Max_Strom_Lim "Cyclic";
BA_ "GenSigStartValue" SG_ 190 MO_EM2_Max_Strom_Lim 8190;
BA_ "GenSigSwitchedByIgnition" SG_ 190 MO_EM2_Max_Strom_Lim "No";
BA_ "GenSigSendType" SG_ 190 MO_EM2_AR_Anf "Cyclic";
BA_ "GenSigSwitchedByIgnition" SG_ 190 MO_EM2_AR_Anf "No";
BA_ "GenSigSendType" SG_ 190 MO_EM2_SollSpannung "Cyclic";
BA_ "GenSigStartValue" SG_ 190 MO_EM2_SollSpannung 4095;
BA_ "GenSigSwitchedByIgnition" SG_ 190 MO_EM2_SollSpannung "No";
BA_ "GenSigSendType" SG_ 190 MO_DC_Max_Strom_HV "Cyclic";
BA_ "GenSigStartValue" SG_ 190 MO_DC_Max_Strom_HV 255;
BA_ "GenSigSwitchedByIgnition" SG_ 190 MO_DC_Max_Strom_HV "No";
BA_ "GenSigSendType" SG_ 190 MO_DC_SollSpannung_HV "Cyclic";
BA_ "GenSigStartValue" SG_ 190 MO_DC_SollSpannung_HV 255;
BA_ "GenSigSwitchedByIgnition" SG_ 190 MO_DC_SollSpannung_HV "No";
BA_ "GenSigSendType" SG_ 190 MO_EM1_Max_Moment "Cyclic";
BA_ "GenSigStartValue" SG_ 190 MO_EM1_Max_Moment 4094;
BA_ "GenSigSwitchedByIgnition" SG_ 190 MO_EM1_Max_Moment "No";
BA_ "GenSigSendType" SG_ 190 MO_EM1_Min_Moment "Cyclic";
BA_ "GenSigStartValue" SG_ 190 MO_EM1_Min_Moment 4094;
BA_ "GenSigSwitchedByIgnition" SG_ 190 MO_EM1_Min_Moment "No";
BA_ "GenSigSendType" SG_ 190 MO_EM2_Max_Moment "Cyclic";
BA_ "GenSigStartValue" SG_ 190 MO_EM2_Max_Moment 4094;
BA_ "GenSigSwitchedByIgnition" SG_ 190 MO_EM2_Max_Moment "No";
BA_ "Fehlerwert" SG_ 190 MO_EM2_Max_Moment 4095;
BA_ "GenSigSendType" SG_ 190 MO_EM2_Min_Moment "Cyclic";
BA_ "GenSigStartValue" SG_ 190 MO_EM2_Min_Moment 4094;
BA_ "GenSigSwitchedByIgnition" SG_ 190 MO_EM2_Min_Moment "No";
BA_ "Fehlerwert" SG_ 190 MO_EM2_Min_Moment 4095;
BA_ "GenSigSendType" SG_ 2463978666 MO_EM1_Min_Spannung_Lim "Cyclic";
BA_ "GenSigStartValue" SG_ 2463978666 MO_EM1_Min_Spannung_Lim 1022;
BA_ "GenSigSwitchedByIgnition" SG_ 2463978666 MO_EM1_Min_Spannung_Lim "No";
BA_ "GenSigSendType" SG_ 2463978666 MO_EM1_Max_Spannung_Lim "Cyclic";
BA_ "GenSigStartValue" SG_ 2463978666 MO_EM1_Max_Spannung_Lim 1022;
BA_ "GenSigSwitchedByIgnition" SG_ 2463978666 MO_EM1_Max_Spannung_Lim "No";
BA_ "GenSigSendType" SG_ 2463978666 MO_EM1_Min_Leistung_Gesamt "Cyclic";
BA_ "GenSigStartValue" SG_ 2463978666 MO_EM1_Min_Leistung_Gesamt 8190;
BA_ "GenSigSwitchedByIgnition" SG_ 2463978666 MO_EM1_Min_Leistung_Gesamt "No";
BA_ "GenSigSendType" SG_ 2463978666 MO_EM1_Max_Leistung_Gesamt "Cyclic";
BA_ "GenSigStartValue" SG_ 2463978666 MO_EM1_Max_Leistung_Gesamt 8190;
BA_ "GenSigSwitchedByIgnition" SG_ 2463978666 MO_EM1_Max_Leistung_Gesamt "No";
BA_ "GenSigSendType" SG_ 2463978666 MO_EM2_Min_Leistung_Gesamt "Cyclic";
BA_ "GenSigStartValue" SG_ 2463978666 MO_EM2_Min_Leistung_Gesamt 8190;
BA_ "GenSigSwitchedByIgnition" SG_ 2463978666 MO_EM2_Min_Leistung_Gesamt "No";
BA_ "GenSigSendType" SG_ 2463978666 MO_EM2_Max_Leistung_Gesamt "Cyclic";
BA_ "GenSigStartValue" SG_ 2463978666 MO_EM2_Max_Leistung_Gesamt 8190;
BA_ "GenSigSwitchedByIgnition" SG_ 2463978666 MO_EM2_Max_Leistung_Gesamt "No";
BA_ "GenSigSendType" SG_ 2463978666 MO_EM2_Min_Spannung_Lim "Cyclic";
BA_ "GenSigStartValue" SG_ 2463978666 MO_EM2_Min_Spannung_Lim 1022;
BA_ "GenSigSwitchedByIgnition" SG_ 2463978666 MO_EM2_Min_Spannung_Lim "No";
BA_ "GenSigSendType" SG_ 2463978666 MO_EM2_Max_Spannung_Lim "Cyclic";
BA_ "GenSigStartValue" SG_ 2463978666 MO_EM2_Max_Spannung_Lim 1022;
BA_ "GenSigSwitchedByIgnition" SG_ 2463978666 MO_EM2_Max_Spannung_Lim "No";
BA_ "GenSigSendType" SG_ 2463978666 MO_EM1_Generator_Leistung "Cyclic";
BA_ "GenSigStartValue" SG_ 2463978666 MO_EM1_Generator_Leistung 254;
BA_ "GenSigSwitchedByIgnition" SG_ 2463978666 MO_EM1_Generator_Leistung "No";
BA_ "Fehlerwert" SG_ 2463978666 MO_EM1_Generator_Leistung 255;
BA_ "GenSigSendType" SG_ 2463978666 MO_Verbrauch_EM_Ges "Cyclic";
BA_ "GenSigSwitchedByIgnition" SG_ 2463978666 MO_Verbrauch_EM_Ges "No";
BA_ "GenSigSendType" SG_ 2463978666 MO_Verbrauch_EM_Ges_Ueberlauf "Cyclic";
BA_ "GenSigSwitchedByIgnition" SG_ 2463978666 MO_Verbrauch_EM_Ges_Ueberlauf "No";
BA_ "GenSigSendType" SG_ 2463978666 MO_Rekuperation_Ges_EM "Cyclic";
BA_ "GenSigSwitchedByIgnition" SG_ 2463978666 MO_Rekuperation_Ges_EM "No";
BA_ "GenSigSendType" SG_ 2463978666 MO_Rekuperation_EM_Ges_Ueberlauf "Cyclic";
BA_ "GenSigSwitchedByIgnition" SG_ 2463978666 MO_Rekuperation_EM_Ges_Ueberlauf "No";
BA_ "GenSigSendType" SG_ 2463978666 MO_Drehzahl_EM "Cyclic";
BA_ "GenSigStartValue" SG_ 2463978666 MO_Drehzahl_EM 8190;
BA_ "GenSigSwitchedByIgnition" SG_ 2463978666 MO_Drehzahl_EM "No";
BA_ "Fehlerwert" SG_ 2463978666 MO_Drehzahl_EM 8191;
BA_ "GenSigSendType" SG_ 2463978666 MO_Uebersetzung_EM "Cyclic";
BA_ "GenSigStartValue" SG_ 2463978666 MO_Uebersetzung_EM 1022;
BA_ "GenSigSwitchedByIgnition" SG_ 2463978666 MO_Uebersetzung_EM "No";
BA_ "Fehlerwert" SG_ 2463978666 MO_Uebersetzung_EM 1023;
BA_ "GenSigSendType" SG_ 2463978666 MO_Drehzahl_EM_sek "Cyclic";
BA_ "GenSigStartValue" SG_ 2463978666 MO_Drehzahl_EM_sek 8190;
BA_ "GenSigSwitchedByIgnition" SG_ 2463978666 MO_Drehzahl_EM_sek "No";
BA_ "Fehlerwert" SG_ 2463978666 MO_Drehzahl_EM_sek 8191;
BA_ "GenSigSendType" SG_ 2463978666 MO_Uebersetzung_EM_sek "Cyclic";
BA_ "GenSigStartValue" SG_ 2463978666 MO_Uebersetzung_EM_sek 1022;
BA_ "GenSigSwitchedByIgnition" SG_ 2463978666 MO_Uebersetzung_EM_sek "No";
BA_ "Fehlerwert" SG_ 2463978666 MO_Uebersetzung_EM_sek 1023;
BA_ "GenSigSendType" SG_ 1601 Motor_Code_01_CRC "Cyclic";
BA_ "GenSigFuncType" SG_ 1601 Motor_Code_01_CRC "CRC-8";
BA_ "GenSigSwitchedByIgnition" SG_ 1601 Motor_Code_01_CRC "No";
BA_ "GenSigSendType" SG_ 1601 Motor_Code_01_BZ "Cyclic";
BA_ "GenSigFuncType" SG_ 1601 Motor_Code_01_BZ "MsgCounter";
BA_ "GenSigSwitchedByIgnition" SG_ 1601 Motor_Code_01_BZ "No";
BA_ "GenSigSendType" SG_ 1601 MO_Faktor_Momente_02 "Cyclic";
BA_ "GenSigFuncType" SG_ 1601 MO_Faktor_Momente_02 "Constant";
BA_ "GenSigSwitchedByIgnition" SG_ 1601 MO_Faktor_Momente_02 "No";
BA_ "GenSigSendType" SG_ 1601 MO_Hybridfahrzeug "Cyclic";
BA_ "GenSigFuncType" SG_ 1601 MO_Hybridfahrzeug "Constant";
BA_ "GenSigSwitchedByIgnition" SG_ 1601 MO_Hybridfahrzeug "No";
BA_ "GenSigSendType" SG_ 1601 MO_Code "Cyclic";
BA_ "GenSigSwitchedByIgnition" SG_ 1601 MO_Code "No";
BA_ "GenSigSendType" SG_ 1601 MO_Getriebe_Code "Cyclic";
BA_ "GenSigSwitchedByIgnition" SG_ 1601 MO_Getriebe_Code "No";
BA_ "GenSigSendType" SG_ 1601 MO_StartStopp_Codiert "Cyclic";
BA_ "GenSigFuncType" SG_ 1601 MO_StartStopp_Codiert "Constant";
BA_ "GenSigSwitchedByIgnition" SG_ 1601 MO_StartStopp_Codiert "No";
BA_ "GenSigSendType" SG_ 1601 MO_Anzeige_StSt_gueltig "Cyclic";
BA_ "GenSigSwitchedByIgnition" SG_ 1601 MO_Anzeige_StSt_gueltig "No";
BA_ "GenSigSendType" SG_ 1601 MO_Anzahl_Zyl "Cyclic";
BA_ "GenSigFuncType" SG_ 1601 MO_Anzahl_Zyl "Constant";
BA_ "GenSigSwitchedByIgnition" SG_ 1601 MO_Anzahl_Zyl "No";
BA_ "GenSigSendType" SG_ 1601 MO_Kraftstoffart "Cyclic";
BA_ "GenSigFuncType" SG_ 1601 MO_Kraftstoffart "Constant";
BA_ "GenSigSwitchedByIgnition" SG_ 1601 MO_Kraftstoffart "No";
BA_ "GenSigSendType" SG_ 1601 MO_Hubraum "Cyclic";
BA_ "GenSigFuncType" SG_ 1601 MO_Hubraum "Constant";
BA_ "GenSigSwitchedByIgnition" SG_ 1601 MO_Hubraum "No";
BA_ "GenSigSendType" SG_ 1601 MO_Ansaugsystem "Cyclic";
BA_ "GenSigFuncType" SG_ 1601 MO_Ansaugsystem "Constant";
BA_ "GenSigSwitchedByIgnition" SG_ 1601 MO_Ansaugsystem "No";
BA_ "GenSigSendType" SG_ 1601 MO_Leistung "Cyclic";
BA_ "GenSigFuncType" SG_ 1601 MO_Leistung "Constant";
BA_ "GenSigSwitchedByIgnition" SG_ 1601 MO_Leistung "No";
BA_ "GenSigSendType" SG_ 1601 MO_OBD_Typ "Cyclic";
BA_ "GenSigFuncType" SG_ 1601 MO_OBD_Typ "Constant";
BA_ "GenSigSwitchedByIgnition" SG_ 1601 MO_OBD_Typ "No";
BA_ "GenSigSendType" SG_ 1601 MO_DPF_verbaut "Cyclic";
BA_ "GenSigFuncType" SG_ 1601 MO_DPF_verbaut "Constant";
BA_ "GenSigSwitchedByIgnition" SG_ 1601 MO_DPF_verbaut "No";
BA_ "GenSigSendType" SG_ 1601 TSK_Codierung "Cyclic";
BA_ "GenSigStartValue" SG_ 1601 TSK_Codierung 7;
BA_ "GenSigSwitchedByIgnition" SG_ 1601 TSK_Codierung "No";
BA_ "GenSigSendType" SG_ 1155 Mo_Powermeter_Grenze "OnChange";
BA_ "GenSigStartValue" SG_ 1155 Mo_Powermeter_Grenze 4093;
BA_ "GenSigSwitchedByIgnition" SG_ 1155 Mo_Powermeter_Grenze "No";
BA_ "GenSigSendType" SG_ 1155 MO_Text_Aktivierung_Antrieb "OnChange";
BA_ "GenSigStartValue" SG_ 1155 MO_Text_Aktivierung_Antrieb 15;
BA_ "GenSigSwitchedByIgnition" SG_ 1155 MO_Text_Aktivierung_Antrieb "No";
BA_ "GenSigSendType" SG_ 1155 MO_Powermeter_Inszenierung_aktiv "OnChange";
BA_ "GenSigSwitchedByIgnition" SG_ 1155 MO_Powermeter_Inszenierung_aktiv "No";
BA_ "GenSigSendType" SG_ 1155 MO_Powermeter_Charge_Grenze "OnChange";
BA_ "GenSigStartValue" SG_ 1155 MO_Powermeter_Charge_Grenze 1022;
BA_ "GenSigSwitchedByIgnition" SG_ 1155 MO_Powermeter_Charge_Grenze "No";
BA_ "Fehlerwert" SG_ 1155 MO_Powermeter_Charge_Grenze 1023;
BA_ "GenSigSendType" SG_ 1155 MO_Powermeter_Grenze_strategisch "OnChange";
BA_ "GenSigStartValue" SG_ 1155 MO_Powermeter_Grenze_strategisch 4094;
BA_ "GenSigSwitchedByIgnition" SG_ 1155 MO_Powermeter_Grenze_strategisch "No";
BA_ "Fehlerwert" SG_ 1155 MO_Powermeter_Grenze_strategisch 4095;
BA_ "GenSigSendType" SG_ 1155 MO_Powermeter_untere_E_Grenze "OnChange";
BA_ "GenSigStartValue" SG_ 1155 MO_Powermeter_untere_E_Grenze 4094;
BA_ "GenSigSwitchedByIgnition" SG_ 1155 MO_Powermeter_untere_E_Grenze "No";
BA_ "Fehlerwert" SG_ 1155 MO_Powermeter_untere_E_Grenze 4095;
BA_ "GenSigSendType" SG_ 1155 MO_Powermeter_obere_E_Grenze "OnChange";
BA_ "GenSigStartValue" SG_ 1155 MO_Powermeter_obere_E_Grenze 4094;
BA_ "GenSigSwitchedByIgnition" SG_ 1155 MO_Powermeter_obere_E_Grenze "No";
BA_ "Fehlerwert" SG_ 1155 MO_Powermeter_obere_E_Grenze 4095;
BA_ "GenSigSendType" SG_ 2527679686 MRR_HR_ASM_Ereignis "OnChange";
BA_ "GenSigSendType" SG_ 2527679686 MRR_HR_ASM_Zeitstempel "OnChange";
BA_ "GenSigStartValue" SG_ 2527679686 MRR_HR_ASM_Zeitstempel 255;
BA_ "GenSigSendType" SG_ 2527679686 MRR_HR_ASM_Data_1 "Cyclic";
BA_ "GenSigSendType" SG_ 2527679686 MRR_HR_ASM_Data_2 "Cyclic";
BA_ "GenSigSendType" SG_ 2527679686 MRR_HR_ASM_Data_3 "Cyclic";
BA_ "GenSigSendType" SG_ 2527679686 MRR_HR_ASM_Data_4 "Cyclic";
BA_ "GenSigSendType" SG_ 2527679686 MRR_HR_ASM_Data_5 "Cyclic";
BA_ "GenSigSendType" SG_ 2527679686 MRR_HR_ASM_Data_6 "Cyclic";
BA_ "GenSigSendType" SG_ 22 WFS_MSG3_RND "OnWrite";
BA_ "GenSigSwitchedByIgnition" SG_ 22 WFS_MSG3_RND "No";
BA_ "GenSigSwitchedByIgnition" SG_ 22 WFS_MSG3_CRC "No";
BA_ "GenSigSendType" SG_ 24 WFS_MSG4_RND "OnWrite";
BA_ "GenSigSwitchedByIgnition" SG_ 24 WFS_MSG4_RND "No";
BA_ "GenSigSwitchedByIgnition" SG_ 24 WFS_MSG4_CRC "No";
BA_ "GenSigSendType" SG_ 339 MSG_HYB_30_CRC "Cyclic";
BA_ "GenSigFuncType" SG_ 339 MSG_HYB_30_CRC "CRC-8";
BA_ "GenSigSwitchedByIgnition" SG_ 339 MSG_HYB_30_CRC "No";
BA_ "GenSigSendType" SG_ 339 MSG_HYB_30_BZ "Cyclic";
BA_ "GenSigFuncType" SG_ 339 MSG_HYB_30_BZ "MsgCounter";
BA_ "GenSigSwitchedByIgnition" SG_ 339 MSG_HYB_30_BZ "No";
BA_ "GenSigSendType" SG_ 339 MO_HVEM_Eskalation "OnChange";
BA_ "GenSigSwitchedByIgnition" SG_ 339 MO_HVEM_Eskalation "No";
BA_ "GenSigSendType" SG_ 339 MO_ErwGrenzen_Anf "OnChange";
BA_ "GenSigSwitchedByIgnition" SG_ 339 MO_ErwGrenzen_Anf "No";
BA_ "GenSigSendType" SG_ 339 MO_Fehler_Notentladung_Anf "OnChange";
BA_ "GenSigSwitchedByIgnition" SG_ 339 MO_Fehler_Notentladung_Anf "No";
BA_ "GenSigSendType" SG_ 339 MO_HVEM_MaxLeistung "Cyclic";
BA_ "GenSigStartValue" SG_ 339 MO_HVEM_MaxLeistung 510;
BA_ "GenSigSwitchedByIgnition" SG_ 339 MO_HVEM_MaxLeistung "No";
BA_ "GenSigSendType" SG_ 339 MO_HVK_EmIstzustand "OnChange";
BA_ "GenSigStartValue" SG_ 339 MO_HVK_EmIstzustand 255;
BA_ "GenSigSwitchedByIgnition" SG_ 339 MO_HVK_EmIstzustand "No";
BA_ "GenSigSendType" SG_ 339 MO_HVK_AntriebFehlerstatus "OnChange";
BA_ "GenSigStartValue" SG_ 339 MO_HVK_AntriebFehlerstatus 7;
BA_ "GenSigSwitchedByIgnition" SG_ 339 MO_HVK_AntriebFehlerstatus "No";
BA_ "GenSigSendType" SG_ 339 MO_MVK_Bordnetz_Anf "OnChange";
BA_ "GenSigSwitchedByIgnition" SG_ 339 MO_MVK_Bordnetz_Anf "No";
BA_ "GenSigSendType" SG_ 339 MO_HVK_AntriebZustand "OnChange";
BA_ "GenSigStartValue" SG_ 339 MO_HVK_AntriebZustand 7;
BA_ "GenSigSwitchedByIgnition" SG_ 339 MO_HVK_AntriebZustand "No";
BA_ "GenSigSendType" SG_ 339 MO_HVK_EmFehlerstatus "OnChange";
BA_ "GenSigStartValue" SG_ 339 MO_HVK_EmFehlerstatus 7;
BA_ "GenSigSwitchedByIgnition" SG_ 339 MO_HVK_EmFehlerstatus "No";
BA_ "GenSigSendType" SG_ 339 MO_MVK_AntriebFehlerstatus "OnChange";
BA_ "GenSigStartValue" SG_ 339 MO_MVK_AntriebFehlerstatus 7;
BA_ "GenSigSwitchedByIgnition" SG_ 339 MO_MVK_AntriebFehlerstatus "No";
BA_ "GenSigSendType" SG_ 339 MO_MVK_AntriebZustand "OnChange";
BA_ "GenSigStartValue" SG_ 339 MO_MVK_AntriebZustand 7;
BA_ "GenSigSwitchedByIgnition" SG_ 339 MO_MVK_AntriebZustand "No";
BA_ "GenSigSendType" SG_ 339 MO_MVK_EmFehlerstatus "OnChange";
BA_ "GenSigStartValue" SG_ 339 MO_MVK_EmFehlerstatus 7;
BA_ "GenSigSwitchedByIgnition" SG_ 339 MO_MVK_EmFehlerstatus "No";
BA_ "GenSigSendType" SG_ 339 MO_MVK_EmIstzustand "OnChange";
BA_ "GenSigStartValue" SG_ 339 MO_MVK_EmIstzustand 255;
BA_ "GenSigSwitchedByIgnition" SG_ 339 MO_MVK_EmIstzustand "No";
VAL_ 1648 MO_ANC_Kennfeld_Anf 0 "Kennfeld_1" 1 "Uebergang_Kennfeld_2_nach_1" 2 "Uebergang_Kennfeld_1_nach_2" 3 "Kennfeld_2";
VAL_ 1648 MO_Bremslicht_Reku 0 "Aus" 1 "Ein";
VAL_ 1648 MO_StartStopp_PopUp 0 "Statuswechsel_ohne_Taster (Init)" 1 "StSt_per_Taster_deaktiviert" 2 "StSt_per_Taster_aktiviert" 3 "nicht verwendet";
VAL_ 1648 MO1_Sperr_Info_WFS 0 "nicht_gesperrt" 1 "gesperrt";
VAL_ 1648 MO1_Freigabe_Info_WFS 0 "ungueltig" 1 "gueltig";
VAL_ 1648 MO_EPCL 0 "EPCL_aus_kein_Text" 1 "EPCL_gelb_Stoerung" 2 "EPCL_gelb_Leistungsbeschraenkung" 3 "EPCL_rot_Fzg_sicher_abstellen";
VAL_ 1648 MO_Zylabsch_Texte_02 0 "ein_ZAS_generell_keine_ZAS_Anzeigen" 1 "ZAS_im_VMB" 2 "ZAS_im_ASB_1_Zyl_aktiv" 3 "ZAS_im_ASB_2_Zyl_aktiv" 4 "ZAS_im_ASB_3_Zyl_aktiv" 5 "ZAS_im_ASB_4_Zyl_aktiv" 6 "ZAS_im_ASB_5_Zyl_aktiv" 7 "ZAS_im_ASB_6_Zyl_aktiv" 8 "ZAS_im_ASB_8_Zyl_aktiv" 9 "ZAS_im_ASB_12_Zyl_aktiv" 13 "Uebergangsbetrieb" 14 "keine_ZAS_Anzeige_ggf_Stopp_Schub_Betrieb" 15 "ZAS_Stoerungs_Anzeige";
VAL_ 1648 MO_Fahrzeugtyp 0 "Verbrenner_Fahrzeug" 1 "Hybrid" 2 "E_Fahrzeug" 3 "E_Fahrzeug_mit_Range_Extender" 4 "Brennstoffzellenfahrzeug" 5 "tbd" 6 "tbd" 7 "tbd";
VAL_ 1648 MO_Abstellzeit 254 "Init" 255 "reserviert";
VAL_ 1648 MO_Abstellzeit_Status 0 "Abstellzeit_nicht_berechnet" 1 "Abstellzeit_berechnet" 2 "Abstellzeit_Minimalwert" 3 "Abstellzeit_ungueltig";
VAL_ 1648 MO1_Freigabe_Verfallsinfo_WFS 0 "verfaellt_nicht" 1 "verfaellt";
VAL_ 1648 MO_Hybrid_StartStopp_LED 0 "LED_aus_und_Blinken_aus" 1 "LED_ein_und_Blinken_aus" 2 "LED_ein_und_Blinken_ein_50_percent" 3 "reserviert";
VAL_ 1648 MO_Fehler_Zylabsch 0 "kein_Fehler" 1 "Notlauf_Vollmotorbetrieb" 2 "Notlauf_mindestens_einem_abgesch_Zylinder";
VAL_ 1648 MO_Anzahl_Abgesch_Zyl 0 "Vollmotorbetrieb" 1 "1_Zylinder_abgeschaltet" 2 "2_Zylinder_abgeschaltet" 3 "3_Zylinder_abgeschaltet" 4 "4_Zylinder_abgeschaltet" 5 "5_Zylinder_abgeschaltet" 6 "6_Zylinder_abgeschaltet" 7 "8_Zylinder_abgeschaltet";
VAL_ 1648 MO_Zylabsch_Texte 0 "keine_Texte" 1 "Zylinderabschaltung_deaktivieren" 2 "Zylinderabschaltung_aktivieren" 3 "Zylinderabschaltung_unruhig";
VAL_ 1648 MO_Ethanol_BS_Texte 0 "kein_Text" 1 "E85_Warm_Up" 2 "FlexFuel_Warnung_Stufe_3" 3 "Warmfahrempfehlung_MQB__FlexFuel_Warnung_Stufe_1" 4 "FlexFuel_Warnung_Stufe_2" 5 "FlexFuel_Warnung_Stufe_4" 6 "E25_Warm_Up";
VAL_ 1648 MO_Drehzahl_Warnung 0 "keinen_Warnhinweis_anzeigen" 1 "Warnhinweis_anzeigen";
VAL_ 1648 MO_obere_Drehzahlgrenze 0 "Init";
VAL_ 967 MO_Kuehlerluefter_MUX 0 "Kuehlerluefter_1" 1 "Kuehlerluefter_2";
VAL_ 967 MO_Kuehlerluefter_1 126 "Init" 127 "Fehler";
VAL_ 967 MO_Kuehlerluefter_2 126 "Init" 127 "Fehler";
VAL_ 967 MO_EFLEX_Lampe 0 "Lampe_aus" 1 "Lampe_ein" 2 "Lampe_blinkend" 3 "Lampe_blinkend_mit_Akustik";
VAL_ 967 MO_KJS_nicht_bereit 0 "kein_Fehler" 1 "Fehler";
VAL_ 967 MO_ITM_Warnung_Pumpe 0 "keine_Warnung" 1 "ITM_Warnung";
VAL_ 967 WIV_Anzeige_aktiv 0 "Anzeige aus" 1 "WIV Anzeige aktiv";
VAL_ 967 WIV_Oelmin_Warn 0 "in_Ordnung" 1 "Warnung";
VAL_ 967 WIV_Sensorfehler 0 "in_Ordnung" 1 "Sensor_defekt";
VAL_ 967 WIV_Schieflage 0 "Fahrzeug_gerade" 1 "Fahrzeug_in_Schieflage";
VAL_ 967 MO_Zustand_HWP 0 "HWP_nicht_schaltbar" 1 "HWP_foerdert_nicht" 2 "HWP_foerdert" 3 "reserviert";
VAL_ 967 OLEV_Systemstoerung 0 "Ölsystem i.O." 1 "Systemstörung Ölsystem";
VAL_ 967 MO_Oelwarnung_max 0 "keine_Warnung" 1 "Warnfall_aktiv";
VAL_ 967 WIV_Oelsystem_aktiv 0 "Anzeige_aus" 1 "Anzeige_aktiv";
VAL_ 967 WIV_nicht_betriebswarm 0 "Motor_warm" 1 "Motor_nicht_betriebswarm";
VAL_ 967 WIV_Ueberfuell_Warn 0 "in_Ordnung" 1 "Ueberfuellwarnung";
VAL_ 967 WIV_laufender_Motor 0 "Messung_moeglich" 1 "Messung_nicht_moeglich";
VAL_ 967 MO_E_Warnungen 0 "keine_Anzeige" 1 "Fehler_Elektrosystem_Anhalten" 2 "Fehler_Elektrosystem_Werkstatt" 3 "Elektrosystem_ueberhitzt_Stopp" 4 "Fehler_Hybridsystem_Anhalten" 5 "Fehler_Hybridsystem_Werkstatt" 6 "Fehler_Wasserstoffsystem_Anhalte" 7 "Fehler_Wasserstoffsystem_Werksta" 8 "reserviert_keine_Anzeige" 9 "reserviert_keine_Anzeige" 10 "reserviert_keine_Anzeige" 11 "reserviert_keine_Anzeige" 12 "reserviert_keine_Anzeige" 13 "reserviert_keine_Anzeige" 14 "reserviert_keine_Anzeige" 15 "reserviert_keine_Anzeige";
VAL_ 967 MO_Text_Motorstart 0 "keine_Anzeige" 9 "Unerwuenschter_Motorstillstand" 1 "Motor_im_Stoppbetrieb" 2 "StartStopp_sicherheitsbedingt_deaktiviert" 3 "System_fordert_Wiederstart" 4 "Aufforderung_Motorstart" 5 "Motorlauf_noetig" 6 "Motorlaufwarnung" 10 "Motorstart_nicht_moeglich" 11 "Fehler_Kupplungsschalter" 12 "Motor_startet" 13 "Kupplung_betaetigen" 14 "Waehlhebel_in_PN_Position" 15 "Bremse_treten";
VAL_ 967 MO_E_Texte 0 "keine_Anzeige" 1 "Batterie_fast_leer" 2 "Ladestecker_nicht_fahrbereit" 3 "VM_Betrieb_erforderlich" 4 "Batterie_laedt_Nicht_ausschalten" 5 "Bitte_Bremse_treten" 6 "manueller_Neustart_erforderlich" 7 "Stopp_Fahrzeug_nicht_abschleppen" 8 "kein_Neustart_Haube_nicht_oeffnen" 9 "Motorstart_im_naechsten_Zyklus" 10 "VM_erforderlich_EVMode_abwaehlen" 11 "laengerer_VMBetrieb_Bordbuch" 12 "Tank_leer_VM_nicht_verfuegbar" 13 "Bitte_warten_Motor_startet" 14 "kein_Start_Batterietemperatur" 15 "Ende_elektrische_Reichweite_erreicht";
VAL_ 967 WIV_Oeldyn_avl 0 "Oeldyn_nicht_vorhanden" 1 "Oeldyn_vorhanden";
VAL_ 967 OLEV_Oelstand_nicht_vorhanden 0 "Ölstand vorhanden" 1 "Ölstand nicht vorhanden";
VAL_ 967 MO_Systemlampe 0 "Lampe aus" 1 "Lampe ein";
VAL_ 967 MO_OBD2_Lampe 0 "Lampe aus" 1 "Lampe ein";
VAL_ 967 MO_Heissleuchte 0 "Lampe aus" 1 "Lampe ein";
VAL_ 967 MO_Partikel_Lampe 0 "Lampe aus" 1 "Lampe ein";
VAL_ 967 MO_RedFahrleistung_Lampe 0 "Lampe_aus" 1 "Lampe_ein";
VAL_ 967 WIV_Oelstand_nicht_vorhanden 0 "Ölstand vorhanden" 1 "Ölstand nicht vorhanden";
VAL_ 967 WIV_nachfuellanzeige_ein 0 "keine_Nachfuellanzeige" 1 "Nachfuellanzeige";
VAL_ 967 WIV_Ueberfuell_deaktiv 0 "Ueberfuellwarnung_am_Kombi_aktiv" 1 "Ueberfuellwarnung_am_Kombi_deaktiv";
VAL_ 967 WIV_Unterfuell_Warn 0 "in_Ordnung" 1 "Unterfuellwarnung";
VAL_ 967 MO_Tankdeckel_Lampe 0 "Lampe aus" 1 "Lampe ein";
VAL_ 967 MO_Text_Tankdeckelwarn 0 "kein_Text" 1 "Anzeige_Text_Tankdeckelwarnung_im_Kombi";
VAL_ 967 MO_Vorglueh_Lampe 0 "Lampe_aus" 1 "Lampe_ein";
VAL_ 967 WIV_Oeldr_Warn_Motor 0 "keine_Warnung" 1 "niedrige_Oeldruckstufe_nicht_erreicht";
VAL_ 967 MO_E_Mode 0 "keine_Anzeige" 1 "E_Mode_passiv" 2 "E_Mode_aktiv" 3 "E_Mode_inaktiv_nicht_verfuegbar" 4 "E_Mode_aktiv_nicht_verfuegbar" 5 "reserviert_keine_Anzeige" 6 "reserviert_keine_Anzeige" 7 "reserviert_keine_Anzeige";
VAL_ 706 MO_Anzeige_StSt_Text 0 "keine_Anzeige" 1 "Systemfehler" 2 "Motor_manuell_starten" 3 "Rueckmeldung_durch_Fahrstufe_einlegen" 4 "Zuendungsabschaltwarnung_Timerstart" 5 "Zum_Motorstart_Bremse_treten" 6 "StSt_Aktivierung_nicht_moeglich_auf_Grund_Fahrprogramm";
VAL_ 706 MO_Anzeige_StSt_Symbol 0 "keine_Anzeige" 1 "StSt_aktiv" 2 "Motorlauf_noetig" 3 "Fahrer_temporaer_abwesend";
VAL_ 706 MO_ADR_Status 0 "nicht_aktiv" 1 "ADR_angefordert" 2 "ADR_aktiv" 3 "ADR_Fehler";
VAL_ 706 MO_AGA_Sound_Texte 0 "keine_Anzeige" 1 "Sound_off" 2 "Sound_on";
VAL_ 706 MO_Anzeige_FMAus_Text 0 "keine_Anzeige" 1 "FMAus_Systemfehler";
VAL_ 706 PEA_Texte 0 "Keine_Anzeige" 1 "PEA_Fahreruebernahme_noetig" 2 "PEA_Reku_nicht_verfuegbar";
VAL_ 706 TSK_Ueberstimmt_vMax_FahrerInfo 0 "nicht_ueberstimmbar" 1 "ueberstimmbar" 2 "ueberstimmt";
VAL_ 706 MO_Rekuperationsstufe 0 "keine_Anzeige" 1 "Rekuperationsstufe_1" 2 "Rekuperationsstufe_2" 3 "Rekuperationsstufe_3" 4 "Rekuperationsstufe_4" 5 "Rekuperationsstufe_5" 6 "Rekuperationsstufe_auto" 7 "Init";
VAL_ 706 TSK_Einheit_vMax_FahrerInfo 0 "km_h" 1 "mph";
VAL_ 706 TSK_Status_vMax_FahrerInfo 0 "keine_Anzeige" 1 "Anzeige_im_Fahrzeugstatus" 2 "PopUp_ohne_Gong__Eintrag_FhzStat" 3 "PopUp_mit_Gong__Eintrag_FhzStat";
VAL_ 706 MO_Anz_Kuehlerluefter 0 "Kein_KuehlerluefterNachlauf" 1 "Text_Luefternachlauf_aktiv" 2 "Text_Luefternachlauf_DPF_aktiv" 3 "Platzhalter_weitere_Signale" 4 "Platzhalter_weitere_Signale" 5 "Platzhalter_weitere_Signale" 6 "Platzhalter_weitere_Signale" 7 "Platzhalter_weitere_Signale";
VAL_ 706 FDR_Warnung_ALR 0 "keine_Anzeige" 1 "Text_Stoerung_Allradverteilung" 2 "Text_Ausfall_Allradverteilung" 3 "reserved";
VAL_ 706 TSK_vMax_FahrerInfo 0 "Init___kein_Wert";
VAL_ 267 MO_Fahrpedalrohwert_01 255 "Fehler";
VAL_ 267 MO_QBit_Fahrpedalwerte_01 0 "gueltiger_Wert" 1 "Ersatz_Init_oder_Fehlerwert";
VAL_ 267 MO_Fahrpedalgradient 255 "Fehler";
VAL_ 267 MO_Sig_Fahrpedalgradient 0 "Fahrpedalgradient positiv" 1 "Fahrpedalgradient negativ";
VAL_ 267 MO_rel_Saugrohrdruck 0 "Init_Ueberdruck" 63 "Fehler";
VAL_ 267 MO_rel_Saugrohrdruck_gem_err 0 "errechnet" 1 "gemessen";
VAL_ 267 MO_Moment_im_Leerlauf 0 "kein_Leergas" 1 "Leergas";
VAL_ 267 MO_Schubabschaltung 0 "keine_Schubabschaltung" 1 "Schubabschaltung_aktiv";
VAL_ 267 MO_Entkopplung_Sollschlupf 125 "Notoeffnen_Anfahrelement" 126 "Init";
VAL_ 267 MO_temporaere_Fahrerabwesenheit 0 "nicht_erkannt" 1 "erkannt";
VAL_ 267 TSK_a_Soll_gradientenbegrenzt 127 "Init_oder_nicht_aktiv";
VAL_ 267 TSK_Status 0 "Hauptschalter_aus" 1 "Init" 2 "passiv" 3 "aktiv" 4 "Uebertreten" 5 "brake_only_Mode" 6 "reversibel_aus" 7 "irreversibel_aus";
VAL_ 267 TSK_v_Begrenzung_aktiv 0 "inaktiv" 1 "aktiv";
VAL_ 267 TSK_Standby_Anf_ESP 0 "keine_Standby_Anforderung" 1 "Standby_Anforderung";
VAL_ 267 TSK_Freig_WU 0 "TSK_Uebersetzungswunsch_nicht_freigegeben" 1 "TSK_Uebersetzungswunsch_freigegeben";
VAL_ 267 TSK_Freig_Verzoeg_Anf 0 "Verzoegerungsanforderung_nicht_freigegeben" 1 "Verzoegerungsanforderung_freigegeben";
VAL_ 267 TSK_Limiter_ausgewaehlt 0 "kein_Limiter_ausgewaehlt" 1 "Limiter_ausgewaehlt";
VAL_ 267 TSK_Wunsch_Uebersetz 0 "Init";
VAL_ 267 TSK_Hauptschalter_GRA_ACC 0 "Init" 1 "Aus" 2 "Ein" 3 "Fehler";
VAL_ 267 TSK_SRBM_Anf_ASIL 0 "keine_SRBM_Anforderung" 1 "SRBM_Anforderung_in_ASIL_QM" 2 "SRBM_Anforderung_in_ASIL_A" 3 "SRBM_Anforderung_in_ASIL_B" 4 "SRBM_Anforderung_in_ASIL_C";
VAL_ 267 TSK_ax_Getriebe_02 511 "Neutralwert";
VAL_ 267 TSK_Zwangszusch_ESP 0 "keine_ESP_ASR_Beeinflussung" 1 "ESP_ASR_Beeinflussung";
VAL_ 267 MO_Status_MinDrzEingriff 0 "kein_Eingriff" 1 "Schalteingriff" 2 "ESP_Eingriff" 3 "Achsdifferenzdrehzahl" 4 "Bauteilschutz" 5 "Rennstart";
VAL_ 267 MO_Status_MaxDrzEingriff 0 "kein_Eingriff" 1 "Schalteingriff" 2 "ESP_Eingriff" 3 "Achsdifferenzdrehzahl" 4 "Bauteilschutz" 5 "Rennstart";
VAL_ 267 MO_Status_MinDrzEingriff_sek 0 "kein_Eingriff" 1 "Schalteingriff" 2 "ESP_Eingriff" 3 "Achsdifferenzdrehzahl" 4 "Bauteilschutz" 5 "Rennstart";
VAL_ 267 MO_Status_MaxDrzEingriff_sek 0 "kein_Eingriff" 1 "Schalteingriff" 2 "ESP_Eingriff" 3 "Achsdifferenzdrehzahl" 4 "Bauteilschutz" 5 "Rennstart";
VAL_ 267 GRA_KuFu_aktiv 0 "inaktiv" 1 "aktiv";
VAL_ 267 TSK_SRBM_max_Gradient 126 "Init" 127 "Fehler";
VAL_ 267 LIM_KuFu_aktiv 0 "inaktiv" 1 "aktiv";
VAL_ 330 MO_Hochschaltdrehz 0 "keine_manuelle_Hochschaltung" 4095 "Fehler";
VAL_ 330 MO_Anzeige_Verbr_Einheit 0 "l_h" 1 "kg_h";
VAL_ 330 MO_Schaltblitz_Anz 101 "blinkende_Anzeige" 126 "Init_Funktion_nicht_aktiv" 127 "Fehler";
VAL_ 330 MO_Anzeige_Drehmoment 2046 "nicht_verbaut" 2047 "Fehler";
VAL_ 330 MO_Anzeige_Leistung 2046 "nicht_verbaut" 2047 "Fehler";
VAL_ 330 MO_rel_Ladedruck 255 "Fehler";
VAL_ 330 MO_Istgang 0 "kein_Gang_eingelegt" 1 "Gang_1" 2 "Gang_2" 3 "Gang_3" 4 "Gang_4" 5 "Gang_5" 6 "Gang_6" 7 "Gang_7" 8 "Gang_8" 9 "Gang_9";
VAL_ 330 MO_Sollgang 0 "keine_Empfehlung" 1 "Gang_1" 2 "Gang_2" 3 "Gang_3" 4 "Gang_4" 5 "Gang_5" 6 "Gang_6" 7 "Gang_7" 8 "Gang_8" 9 "Gang_9" 15 "Neutralgang";
VAL_ 330 MO_Oeldruck 254 "Init" 255 "Fehler";
VAL_ 330 MO_Anzeigedrehz 4095 "reserviert";
VAL_ 330 MO_Effizienzmodus 0 "nicht_im_Effizienz_Modus" 1 "Effizienz_Modus";
VAL_ 330 MO_Fehler_Oeldrucksensor 0 "kein_Fehler" 1 "Fehler";
VAL_ 330 MO_Schaltempf_verfbar 0 "nicht_verfuegbar" 1 "verfuegbar";
VAL_ 330 MO_Ladedruck 511 "Fehler";
VAL_ 330 MO_KVS_Ueberlauf 0 "kein Ueberlauf" 1 "Kraftstoffverbrauchsignale mindestens 1x übergelaufen";
VAL_ 330 MO_ePowermeter 0 "Init_keine_Anzeige" 254 "Funktion_deaktiv_Anzeige_ausgegraut" 255 "Fehler_keine_Anzeige";
VAL_ 330 MO_ePerformance 0 "Init" 254 "Funktion_deaktiv_Anz_ausgegraut" 255 "Fehler";
VAL_ 330 MO_Zust_Antrieb 0 "VKM aktiv" 1 "EM aktiv" 2 "VKM und EM aktiv" 3 "Segeln oder Reku aktiv";
VAL_ 330 MO_Zust_Betriebsstrategie 0 "Kein Hybrid" 1 "Depleting" 2 "Soft-Depleting " 3 "Sustaining" 4 "Increasing" 5 "Fremdgesteuert";
VAL_ 330 Ladezustand_02 254 "Init" 255 "Fehler";
VAL_ 330 MO_Powermeter_Elm_02 0 "nicht_verbaut" 4094 "Init";
VAL_ 330 MO_Powermeter 4093 "Off";
VAL_ 512 TSK_Wunschgeschw 1022 "keine_Anzeige" 1023 "kein_Wert_im_Speicher";
VAL_ 512 TSK_praediktiver_Hinweis 0 "keine_Anzeige" 1 "Vorschlag_zur_Bestaetigung" 2 "Hinweis_neuer_Setzwert" 3 "Regelung_im_Uebergang";
VAL_ 512 TSK_naechstes_Event 0 "Init" 1 "Tempolimit_5" 2 "Tempolimit_10" 3 "Tempolimit_15" 4 "Tempolimit_20" 5 "Tempolimit_25" 6 "Tempolimit_30" 7 "Tempolimit_35" 8 "Tempolimit_40" 9 "Tempolimit_45" 10 "Tempolimit_50" 11 "Tempolimit_55" 12 "Tempolimit_60" 13 "Tempolimit_65" 14 "Tempolimit_70" 15 "Tempolimit_75" 16 "Tempolimit_80" 17 "Tempolimit_90" 18 "Tempolimit_100" 19 "Tempolimit_110" 20 "Tempolimit_120" 21 "Tempolimit_130" 22 "Tempolimit_140" 23 "Tempolimit_150" 24 "Tempolimit_160" 25 "Tempolimit_unbegrenzt" 26 "Linkskurve" 27 "Rechtskurve" 28 "Kuppe" 29 "Steigung" 30 "Gefaelle" 31 "Kreuzung" 32 "Ampel" 33 "Bahnuebergang" 34 "Ortsanfang" 35 "Kreisverkehr" 36 "naechstes_Limit_ausserh_Verfueg";
VAL_ 512 TSK_Fahrzeugstatus_praed_Fkt 0 "init" 1 "Praed_Fkt_verfuegbar" 2 "Praed_Fkt_eingeschraenkt_verfueg" 3 "Praed_Fkt_nicht_verfuegbar" 4 "Praed_Fkt_Land_nicht_verfuegbar";
VAL_ 512 TSK_Texte 0 "kein_Text" 1 "GRA_Modus_ausgewaehlt" 2 "ACC_Modus_ausgewaehlt" 3 "Lim_Modus_ausgewaehlt" 4 "Lim_nicht_verfuegbar_ESC_passiv" 5 "GRA_nicht_verfuegbar_ESC_passiv" 6 "Lim_nicht_verfuegbar_Charisma" 7 "GRA_nicht_verfuegbar_Charisma" 8 "Lim_nicht_verfuegbar_HDC" 9 "GRA_nicht_verfuegbar_HDC" 10 "P_GRA_Modus_ausgewaehlt" 11 "P_LIM_Modus_ausgewaehlt" 12 "Bremse_ueberhitzt";
VAL_ 512 TSK_Akustik 0 "keine_Akustik" 1 "einzelner_Warnton" 2 "dauerhafter_Warnton";
VAL_ 512 TSK_Texte_Primaeranz 0 "keine_Anzeige" 1 "GRA_Symbol_passiv_xxx_kmh_mph" 2 "GRA_Symbol_aktiv_xxx_kmh_mph" 3 "Bremse_ueberhitzt" 4 "Limiter_Modus_aktiviert" 5 "GRA_Modus_aktiviert" 6 "ACC_Modus_aktiviert" 7 "Opt_Geschwindigkeitswarnung" 8 "Opt_und_akustische_GeschwWarnung" 9 "Opt_GeschwWarnung_dauerhaft_mit_einmal_Akustik" 10 "Limiter_passiv_mit_Akustik" 11 "Limiter_Fehler_mit_Akustik" 12 "Limiter_Symbol_passiv_xxx_kmh_mph" 13 "Limiter_Symbol_aktiv_xxx_kmh_mph" 14 "Popup_Geschw_zu_hoch__Resume_unzulaessig";
VAL_ 512 TSK_Limiter_Fahrerinfo 0 "keine_Info" 1 "Limit_erreicht" 2 "Ueberschritten" 3 "Vom_Fahrer_Ueberstimmt";
VAL_ 512 TSK_Limiter_Anzeige 0 "Display_Anzeige_GRA_ACC" 1 "Display_Anzeige_Limiter";
VAL_ 512 TSK_Fahrzeugstatus_GRA 0 "GRA_verfuegbar" 1 "GRA_nicht_verfuegbar";
VAL_ 512 TSK_Fahrzeugstatus_Limiter 0 "Limiter_verfuegbar" 1 "Limiter_nicht_verfuegbar";
VAL_ 512 MO_Motorlaufwarnung 0 "keine_Anzeige" 1 "Anforderung_Motorlaufwarnung";
VAL_ 512 TSK_naechstes_Event_Einheit 0 "kmh" 1 "mph";
VAL_ 512 TSK_Status_Anzeige 0 "Hauptschalter_aus" 1 "Init" 2 "passiv" 3 "aktiv" 4 "Uebertreten" 5 "Limitiierung_aktiv" 6 "reversibel_aus" 7 "irreversibel_aus";
VAL_ 512 MO_Sperrung_FahrPr_BZS 128 "Sperrung BZS8" 0 "keine Sperrung" 64 "Sperrung BZS7" 32 "Sperrung BZS6" 16 "Sperrung BZS5" 8 "Sperrung BZS4" 1 "Sperrung BZS1" 2 "Sperrung BZS2" 4 "Sperrung BZS3";
VAL_ 512 MO_Rampenzeit_Generator_Anf 0 "0_sec" 1 "1_sec" 2 "2_sec" 3 "3_sec" 4 "4_sec" 5 "5_sec" 6 "6_sec" 7 "7_sec" 8 "8_sec" 9 "9_sec" 10 "reserviert" 11 "reserviert" 12 "reserviert" 13 "reserviert" 14 "reserviert" 15 "keine_Anforderung";
VAL_ 512 MO_Prio_MAX_Wunschdrehzahl 0 "Wunsch" 1 "Zwang";
VAL_ 512 MO_Prio_MIN_Wunschdrehzahl 0 "Wunsch" 1 "Zwang";
VAL_ 512 MO_Luftpfad_aktiv 0 "kein Eingriff oder nur Eingriff über Zündpfad" 1 "Eingriff über Luftpfad";
VAL_ 512 MO_v_Begrenz_Aktivierbar 0 "V-Begrenzung nicht möglich" 1 "V-Begrenzung möglich";
VAL_ 512 MO_Charisma_FahrPr 0 "keine_Funktion" 1 "Programm_1" 2 "Programm_2" 3 "Programm_3" 4 "Programm_4" 5 "Programm_5" 6 "Programm_6" 7 "Programm_7" 8 "Programm_8" 9 "Programm_9" 10 "Programm_10" 11 "Programm_11" 12 "Programm_12" 13 "Programm_13" 14 "Programm_14" 15 "Programm_15";
VAL_ 512 MO_Charisma_Status 0 "Init" 1 "verfuegbar" 2 "nicht_verfuegbar" 3 "asynchron_durch_Fahrerwunsch";
VAL_ 512 MO_StSt_Charisma_FahrPr 0 "keine_Funktion" 1 "Programm_1" 2 "Programm_2" 3 "Programm_3" 4 "Programm_4" 5 "Programm_5" 6 "Programm_6" 7 "Programm_7" 8 "Programm_8" 9 "Programm_9" 10 "Programm_10" 11 "Programm_11" 12 "Programm_12" 13 "Programm_13" 14 "Programm_14" 15 "Programm_15";
VAL_ 512 MO_StSt_Charisma_Status 0 "Init" 1 "verfuegbar" 2 "nicht_verfuegbar" 3 "asynchron_durch_Fahrerwunsch";
VAL_ 512 MO_BZS_Charisma_FahrPr 0 "keine_Funktion" 1 "Programm_1" 2 "Programm_2" 3 "Programm_3" 4 "Programm_4" 5 "Programm_5" 6 "Programm_6" 7 "Programm_7" 8 "Programm_8" 9 "Programm_9" 10 "Programm_10" 11 "Programm_11" 12 "Programm_12" 13 "Programm_13" 14 "Programm_14" 15 "Programm_15";
VAL_ 512 MO_BZS_Charisma_Status 0 "Init" 1 "verfuegbar" 2 "nicht_verfuegbar" 3 "asynchron_durch_Fahrerwunsch";
VAL_ 512 MO_NGS_Position 0 "Neutralposition_nicht_erkannt" 1 "Neutralposition_erkannt";
VAL_ 512 MO_NGS_Status 0 "nicht_verbaut" 1 "nicht_plausibilisiert" 2 "plausibilisiert" 3 "Fehler";
VAL_ 512 MO_v_Begrenzung_Niveau 0 "keine_Begrenzung_aktiv" 1 "Sicherheitsbegrenzung_1_aktiv" 2 "Sicherheitsbegrenzung_2_aktiv" 3 "Komfortbegrenzung_aktiv";
VAL_ 512 MO_Anzeige_Rekuperation 0 "Init_und_nicht_verbaut";
VAL_ 512 PEA_Fortschrittsanzeige 127 "Neutralwert";
VAL_ 512 MO_Anzeige_Fahrbereitschaft 0 "OFF" 1 "READY";
VAL_ 512 MO_Boost_verfuegbar 0 "Init" 253 "Nicht_verbaut" 254 "Funktion_deaktiv" 255 "Fehler";
VAL_ 512 MO_Overboost 0 "inaktiv" 1 "aktiv";
VAL_ 512 MO_Boost_aktiv 0 "kein_Boost_aktiv" 1 "Boost_aktiv";
VAL_ 512 MO_Anzeige_Betriebsmodus 0 "Init_keine_Anzeige" 1 "EV" 2 "Auto" 3 "Hold" 4 "Charge" 5 "GTE" 6 "ECO" 7 "SPORT" 8 "Auto_praediktiv" 9 "Manuell_SOC_erhoehen" 10 "Manuell_SOC_halten" 11 "Manuell_SOC_verringern";
VAL_ 512 PEA_Hinweis 0 "keine_Anzeige" 1 "Anzeige_Fusssymbol_1" 2 "Anzeige_Fusssymbol_2" 3 "Anzeige_Auskuppeln";
VAL_ 512 PEA_Ereignisanzeige 0 "keine_Anzeige" 1 "Linkskurve_voraus" 2 "Rechtskurve_voraus" 3 "Kreuzung_voraus" 4 "Gefaelle_voraus" 5 "Kreisverkehr_voraus" 6 "Fahrzeug_voraus" 7 "Tempolimit_voraus" 8 "Ereignis_voraus" 9 "Autobahnabfahrt_voraus" 10 "Autobahnauffahrt_voraus" 11 "Abbiegung_links_voraus" 12 "Abbiegung_rechts_voraus" 13 "Ortseinfahrt_voraus" 14 "Autobahnabfahrt_links_voraus";
VAL_ 512 PEA_Ereignisanzeige_temporaer 0 "keine_Anzeige" 1 "Anzeige_temporaer";
VAL_ 512 PEA_Abschalttexte 0 "keine_Anzeige" 1 "PEA_ausserhalb_Einsatzgebiet" 2 "PEA_temporaer_nicht_verfuegbar" 3 "PEA_vom_Fahrer_deaktiviert";
VAL_ 512 PEA_Zielgeschw_Einheit 0 "km_h" 1 "mph";
VAL_ 512 PEA_Zielgeschw 0 "keine_Anzeige" 1 "Wert_5" 2 "Wert_10" 3 "Wert_15" 4 "Wert_20" 5 "Wert_25" 6 "Wert_30" 7 "Wert_35" 8 "Wert_40" 9 "Wert_45" 10 "50" 11 "Wert_55" 12 "Wert_60" 13 "Wert_65" 14 "Wert_70" 15 "Wert_75" 16 "Wert_80" 17 "Wert_85" 18 "Wert_90" 19 "Wert_95" 20 "Wert_100" 21 "Wert_105" 22 "Wert_110" 23 "Wert_115" 24 "Wert_120" 25 "Wert_125" 26 "Wert_130" 27 "Wert_140" 28 "Wert_150" 29 "Wert_160";
VAL_ 512 MO_Antriebsstrang_Warnung_HS 0 "Keine_Anzeige" 1 "Fehlereskalationsstufe_I" 2 "Fehlereskalationsstufe_II" 3 "Fehlereskalationsstufe_III";
VAL_ 332 MO_Anforderung_HMS 0 "keine_Anforderung" 1 "halten" 2 "parken" 3 "halten_Standby" 4 "anfahren" 5 "Loesen_ueber_Rampe";
VAL_ 332 FoD_DTC_TSK_GRA 0 "Kein_DTC" 1 "DTC_vorhanden_oder_in_Quali";
VAL_ 332 TSK_vMax_aktuell 254 "kein_Limit_aktiv" 255 "Init";
VAL_ 332 TSK_Status_EA 0 "Aus" 1 "Init_oder_nicht_verbaut" 3 "Aktiv" 4 "Uebertreten" 5 "Abschaltung_laeuft" 6 "Reversibel_aus" 7 "Fehler";
VAL_ 332 FoD_DTC_TSK_ACC 0 "Kein_DTC" 1 "DTC_vorhanden_oder_in_Quali";
VAL_ 332 TSK_ACC_FoD_Status 0 "default" 1 "nicht_aktiv" 2 "aktiv" 3 "nicht_genutzt";
VAL_ 332 TSK_GRA_FoD_Status 0 "default" 1 "nicht_aktiv" 2 "aktiv" 3 "nicht_genutzt";
VAL_ 332 TSK_vMax_Fahrerassistenz 511 "Init_ungueltig_keine_Beschraenkung";
VAL_ 332 TSK_Einheit_vMax_Fahrerassistenz 0 "kmh" 1 "mph";
VAL_ 332 TSK_Status_PLA 0 "Aus_Funktionsbereit" 1 "Init_oder_nicht_verbaut" 2 "aktivierbar" 3 "aktiv" 5 "Abschaltung_laeuft" 6 "reversibel_aus" 7 "Fehler";
VAL_ 332 TSK_aktives_System 0 "keine_Funktion_aktiv" 1 "GRA_ACC" 2 "ARA" 3 "Speedlimiter" 4 "IPA" 5 "PLA" 6 "PEA_Ausrollassistent" 7 "EA";
VAL_ 332 TSK_erhoehter_Fahrwiderstand 0 "kein_erhoehter_Fahrwiderstand" 1 "erhoehter_Fahrwiderstand";
VAL_ 332 TSK_Anf_Antriebsmoment 0 "keine_Anforderung" 1 "Anforderung_aktiv";
VAL_ 332 TSK_Status_ARA 0 "Aus" 1 "Init_oder_nicht_verbaut" 2 "aktivierbar" 3 "aktiv" 5 "abschaltung_laeuft" 6 "reversibel_aus" 7 "Fehler";
VAL_ 332 TSK_Status_IPA 0 "Aus_Funktionsbereit" 1 "Init_oder_nicht_verbaut" 2 "aktivierbar" 3 "aktiv" 4 "Fahreruebernahme_angefordert" 5 "Abschaltung_laueft" 6 "reversibel_aus" 7 "Fehler";
VAL_ 332 MO_Fahrbereitschaft 0 "Fahrzykl_inaktiv__kein_Antrieb" 1 "Fahrzykl_aktiv__kein_Antrieb" 2 "Fahrzykl_aktiv__Antrieb_moeglich";
VAL_ 332 MO_Freilauf_Info 0 "Freilauf_freigegeben" 1 "Uebergang_in_Freilauf_unzulaessig" 2 "Freilauf_nicht_freigegeben_Abbruch" 3 "Freilauf_Anforderung";
VAL_ 332 MO_Krit_Heckobjekt 0 "Init_kein_relevantes_Objekt" 1 "Entfernung_grosser_Abstand" 2 "Annaeherung_grosser_Abstand" 3 "Entfernung_geringer_Abstand" 4 "Annaeherung_geringer_Abstand" 7 "Fehler";
VAL_ 332 MO_NGS_Gangpos 0 "nicht_bedient" 1 "1_3_oder_5" 2 "2_4_6_oder_R" 3 "R" 4 "Neutralposition" 5 "Zwischenposition" 6 "Sensor_temp_nicht_verfuegbar" 7 "Fehler";
VAL_ 332 MO_Freilauf_Status 0 "Freilauf_inaktiv_aber_moeglich" 1 "Freilauf_aktiv" 2 "Freilauf_nicht_moegl_1Verhinderer" 3 "Freilauf_nicht_moegl_gr_1Verhinderer" 7 "Fehler";
VAL_ 332 MO_EBoost_verf_praed 0 "Init_oder_nicht_verfuegbar" 1 "EBoost_kurzzeit_verfuegbar" 2 "EBoost_langzeit_verfuegbar";
VAL_ 332 MO_Heckspoiler_Anf 0 "nicht_angefordert" 1 "angefordert";
VAL_ 332 MO_eLaunch_verf 0 "Init" 1 "nicht_verfuegbar" 2 "verfuegbar";
VAL_ 332 MO_Positionierung_aktiv 0 "keine_Positionierung_aktiv" 1 "Positionierung_aktiv";
VAL_ 332 MO_Freilauf_Typ 0 "Koordinator_GSG" 1 "Koordinator_MSG" 2 "Koordinator_GSG_mit_FP_Grad";
VAL_ 332 MO_Startwunsch 0 "kein_Startwunsch" 1 "Startwunsch";
VAL_ 332 MO_Servicemodus 0 "nicht_aktiv" 1 "Service_Mode_1" 2 "Service_Mode_2" 3 "Service_Mode_3" 4 "Service_Mode_4" 5 "Service_Mode_5" 6 "Service_Mode_6" 7 "Service_Mode_7" 8 "Service_Mode_8" 9 "Service_Mode_9" 10 "Service_Mode_10" 11 "Service_Mode_11" 12 "Service_Mode_12" 13 "Service_Mode_13" 14 "Service_Mode_14" 15 "Service_Mode_15";
VAL_ 332 OBD_ClearMem_Inhibit 0 "FSP_Loeschen_zulaessig" 1 "FSP_Loeschen_nicht_zulaessig";
VAL_ 332 OBD_Sperrung_Kaltstart_Denom 0 "EVAP_Berechnung_freigegeben" 1 "EVAP_Berechnung_gesperrt";
VAL_ 332 MO_QBit_Aussen_Temp 0 "gueltiger_Wert" 1 "Ersatz_Init_oder_Fehlerwert";
VAL_ 332 OBD_Sperrung_IUMPR 0 "IUMPR_Berechnung_freigegeben" 1 "IUMPR_Berechnung_gesperrt";
VAL_ 332 OBD_Kaltstart_Denominator 0 "Denominator_nicht_hochzaehlen" 1 "Bedingungen_zum_Inkr_des_Kaltstart_Denom_erf";
VAL_ 332 OBD_Minimum_Trip 0 "kein_Min_Normed_Trip" 1 "Min_Normed_Trip";
VAL_ 332 OBD_Driving_Cycle 0 "kein Driving Cycle erkannt" 1 "DC erkannt";
VAL_ 332 OBD_Warm_Up_Cycle 0 "kein Warm Up Cycle erkannt" 1 "Warm Up Cycle erkannt";
VAL_ 332 OBD_Normed_Trip 0 "kein Normed Trip" 1 "Normed Trip erfüllt";
VAL_ 332 OBD_Aussen_Temp_gef 254 "Init" 255 "Fehler";
VAL_ 246 TS_Faktor_Radmomente 0 "Faktor_1NM" 1 "Faktor_2NM" 2 "Faktor_3NM" 3 "Faktor_4NM";
VAL_ 246 TS_Status_MomRad_Ist 0 "FuSi_hohe_Genauigkeit" 1 "FuSi_niedrige_Genauigkeit" 2 "QM_fehlerfrei" 3 "QM_mit_Fehlern";
VAL_ 246 TS_MomRad_verfuegb_maxReku_Summe 4094 "Init" 4095 "Fehler";
VAL_ 246 TS_MomRad_Ist 8190 "Init";
VAL_ 246 TS_MomRad_Soll_Summe 8190 "Init";
VAL_ 246 TS_MomRad_Wunsch 8190 "Init";
VAL_ 246 TS_MomRad_Wunsch_sek 8190 "Init" 8191 "Fehler";
VAL_ 246 TS_MomRad_verfuegb_max 4094 "Init";
VAL_ 246 TS_MomRad_verfuegb_max_sek 4094 "Init" 4095 "Fehler";
VAL_ 246 TS_MomRad_verfuegb_maxReku 4094 "Init";
VAL_ 246 TS_MomRad_verfuegb_maxReku_sek 4094 "Init" 4095 "Fehler";
VAL_ 246 TS_MomRad_Ist_sek 8190 "Init" 8191 "Fehler";
VAL_ 246 TS_Allrad_Anteil_sek 510 "Init" 511 "Fehler";
VAL_ 246 FDR_Allrad_Anteil_max_sek 510 "Init" 511 "Fehler";
VAL_ 246 FDR_Allrad_Anteil_min_sek 510 "Init" 511 "Fehler";
VAL_ 246 FDR_MomRad_Eingriff 8190 "Init" 8191 "Fehler";
VAL_ 246 FDR_Status_Eingriff 0 "kein_Eingriff" 1 "Eingriff";
VAL_ 246 FDR_MomRad_Eingriff_sek 8190 "Init" 8191 "Fehler";
VAL_ 246 FDR_Status_Eingriff_sek 0 "kein_Eingriff" 1 "Eingriff";
VAL_ 190 MO_EM1_MinDrehzahl 16383 "Init";
VAL_ 190 MO_EM1_MaxDrehzahl 16383 "Init";
VAL_ 190 MO_EM1_DynLimit_AR 255 "Init";
VAL_ 190 MO_EM1_Periode_AR 255 "Init";
VAL_ 190 MO_EM1_SollMoment 4094 "Init";
VAL_ 190 MO_EM1_Sollmodus 8 "Freilauf" 0 "Standby" 1 "Momentenreg" 2 "Int_Drehzahlreg" 3 "Spannungsreg" 4 "Ext_Drehzahlreg" 6 "Kalibrierung" 7 "Sonderbremsbetrieb" 15 "Initialisierung";
VAL_ 190 MO_EM1_Min_Leistung 16382 "Init";
VAL_ 190 MO_EM1_Max_Leistung 16382 "Init";
VAL_ 190 MO_EM1_Min_Strom_Lim 8190 "Init";
VAL_ 190 MO_EM1_Max_Strom_Lim 8190 "Init";
VAL_ 190 MO_EM1_AR_Anf 0 "AR_aus" 2 "AR_D2T2" 3 "AR_RDR" 4 "AR_IRDR";
VAL_ 190 MO_EM1_Kp_AR 511 "Init";
VAL_ 190 MO_EM1_SollSpannung 4095 "Init";
VAL_ 190 MO_EM2_MinDrehzahl 16383 "Init";
VAL_ 190 MO_EM2_MaxDrehzahl 16383 "Init";
VAL_ 190 MO_EM2_DynLimit_AR 255 "Init";
VAL_ 190 MO_EM2_Periode_AR 255 "Init";
VAL_ 190 MO_EM2_SollMoment 4094 "Init" 4095 "Fehler";
VAL_ 190 MO_EM2_Sollmodus 8 "Freilauf" 0 "Standby" 1 "Momentenreg" 2 "Int_Drehzahlreg" 3 "Spannungsreg" 4 "Ext_Drehzahlreg" 6 "Kalibrierung" 7 "Sonderbremsbetrieb" 15 "Initialisierung";
VAL_ 190 MO_EM2_Min_Leistung 16382 "Init";
VAL_ 190 MO_EM2_Max_Leistung 16382 "Init";
VAL_ 190 MO_EM2_Min_Strom_Lim 8190 "Init";
VAL_ 190 MO_EM2_Max_Strom_Lim 8190 "Init";
VAL_ 190 MO_EM2_AR_Anf 0 "AR_aus" 2 "AR_D2T2" 3 "AR_RDR" 4 "AR_IRDR";
VAL_ 190 MO_EM2_SollSpannung 4095 "Init";
VAL_ 190 MO_DC_Max_Strom_HV 255 "Init";
VAL_ 190 MO_DC_SollSpannung_HV 255 "Init";
VAL_ 190 MO_EM1_Max_Moment 4094 "Init";
VAL_ 190 MO_EM1_Min_Moment 4094 "Init";
VAL_ 190 MO_EM2_Max_Moment 4094 "Init" 4095 "Fehler";
VAL_ 190 MO_EM2_Min_Moment 4094 "Init" 4095 "Fehler";
VAL_ 2463978666 MO_EM1_Min_Spannung_Lim 1022 "Init";
VAL_ 2463978666 MO_EM1_Max_Spannung_Lim 1022 "Init";
VAL_ 2463978666 MO_EM1_Min_Leistung_Gesamt 8190 "Init";
VAL_ 2463978666 MO_EM1_Max_Leistung_Gesamt 8190 "Init";
VAL_ 2463978666 MO_EM2_Min_Leistung_Gesamt 8190 "Init";
VAL_ 2463978666 MO_EM2_Max_Leistung_Gesamt 8190 "Init";
VAL_ 2463978666 MO_EM2_Min_Spannung_Lim 1022 "Init";
VAL_ 2463978666 MO_EM2_Max_Spannung_Lim 1022 "Init";
VAL_ 2463978666 MO_EM1_Generator_Leistung 254 "Init" 255 "Fehler";
VAL_ 2463978666 MO_Verbrauch_EM_Ges_Ueberlauf 0 "kein_Ueberlauf" 1 "Ueberlauf_Verbrauchssignal";
VAL_ 2463978666 MO_Rekuperation_EM_Ges_Ueberlauf 0 "kein_Ueberlauf" 1 "Ueberlauf_Reku_Leistungssignal";
VAL_ 2463978666 MO_Drehzahl_EM 8190 "Init_nichtverbaut" 8191 "Fehler";
VAL_ 2463978666 MO_Uebersetzung_EM 0 "keine_sichere_Uebertragung" 1022 "Init_nichtverbaut" 1023 "Fehler";
VAL_ 2463978666 MO_Drehzahl_EM_sek 8190 "Init_nichtverbaut" 8191 "Fehler";
VAL_ 2463978666 MO_Uebersetzung_EM_sek 0 "keine_sichere_Uebertragung" 1022 "Init" 1023 "Fehler";
VAL_ 1601 MO_Faktor_Momente_02 0 "nicht_belegt";
VAL_ 1601 MO_Hybridfahrzeug 0 "kein_Hybridfahrzeug" 1 "Mild_Hybrid" 2 "Full_Hybrid" 3 "PlugIn_Hybrid";
VAL_ 1601 MO_Getriebe_Code 8 "AL552_Allrad" 0 "Init" 2 "DL501" 3 "DL800" 4 "VL381" 5 "DL382_Front" 6 "DL382_Allrad" 7 "DL702" 9 "AL552_Front" 10 "AL651" 11 "AL551__AL951__AL1000_8A" 12 "PDK_PAG" 13 "AL551_Hybrid" 15 "Handschalter_konventionell" 16 "AQ250_160" 17 "AQ450" 18 "DQ200" 19 "DQ250" 20 "DQ500" 21 "SQ100" 22 "SQ200" 23 "DQ400E" 24 "DQ381" 25 "AL550" 26 "AQ300" 31 "DL800E" 32 "Single_Gear__ohne_GSG_WH_am_MSG" 33 "EQ550_2P";
VAL_ 1601 MO_StartStopp_Codiert 0 "Start_Stopp_nicht_verbaut" 1 "Start_Stopp_verbaut";
VAL_ 1601 MO_Anzeige_StSt_gueltig 0 "MO_Text_Motorstart_gueltig" 1 "Signale_MO_Anzeige_StSt_gueltig";
VAL_ 1601 MO_Anzahl_Zyl 0 "kein_Zylinder" 1 "1_Zylinder" 2 "2_Zylinder" 3 "3_Zylinder" 4 "4_Zylinder" 5 "5_Zylinder" 6 "6_Zylinder" 7 "7_Zylinder" 8 "8_Zylinder" 9 "9_Zylinder" 10 "10_Zylinder" 11 "11_Zylinder" 12 "12_Zylinder" 13 "15_Zylinder" 14 "16_Zylinder" 15 "18_Zylinder";
VAL_ 1601 MO_Kraftstoffart 0 "Diesel" 1 "Benzin_inkl_E25_E85" 2 "CNG" 3 "LPG" 4 "Wasserstoff" 5 "E100_Ethanol" 15 "kein_Verbrennungskraftstoff";
VAL_ 1601 MO_Ansaugsystem 0 "Turbo" 1 "Sauger";
VAL_ 1601 MO_OBD_Typ 0 "NoOBD_RdW" 1 "EOBD" 2 "US_OBD" 3 "reserviert";
VAL_ 1601 MO_DPF_verbaut 0 "kein_DPF_verbaut" 1 "DPF_verbaut";
VAL_ 1601 TSK_Codierung 0 "kein_Fahrgeschwindigkeitsregler" 1 "GRA" 2 "GRA_Plus" 3 "Basis_ACC" 4 "ACC_Follow_to_Stop" 5 "ACC_Stop_and_Go" 7 "Codierung_in_Plausibilisierungsphase";
VAL_ 1155 Mo_Powermeter_Grenze 4093 "OFF";
VAL_ 1155 MO_Text_Aktivierung_Antrieb 0 "keine_Anzeige" 1 "Ladestecker_nicht_fahrbereit" 2 "erneute_Aktivierung_erforderlich" 3 "Warten_Antrieb_wird_aktiviert" 4 "zum_Fahren_Bremse_und_Fahrstufe" 15 "Init";
VAL_ 1155 MO_Powermeter_Inszenierung_aktiv 0 "keine_Anzeige" 1 "Inszenierung_aktiv";
VAL_ 1155 MO_Powermeter_Charge_Grenze 1022 "Init" 1023 "Fehler";
VAL_ 1155 MO_Powermeter_Grenze_strategisch 4094 "Init" 4095 "Fehler";
VAL_ 1155 MO_Powermeter_untere_E_Grenze 4094 "Init" 4095 "Fehler";
VAL_ 1155 MO_Powermeter_obere_E_Grenze 4094 "Init" 4095 "Fehler";
VAL_ 2527679686 MRR_HR_ASM_Ereignis 0 "No_Event" 255 "ASM_Trigger";
VAL_ 2527679686 MRR_HR_ASM_Zeitstempel 255 "Init";
VAL_ 339 MO_HVEM_Eskalation 0 "keine_Eskalation_HVEM" 1 "Eskalation_HVEM";
VAL_ 339 MO_ErwGrenzen_Anf 0 "normal" 1 "erweitert";
VAL_ 339 MO_Fehler_Notentladung_Anf 0 "Init";
VAL_ 339 MO_HVEM_MaxLeistung 510 "Init";
VAL_ 339 MO_HVK_EmIstzustand 128 "HvFailBattOffReq" 0 "HvOff" 129 "HvFailBattOffOk" 1 "HvStbyReq" 18 "HvOnDrvReq" 138 "HvFailUCtlReq" 10 "HvOnIdle" 130 "HvFailBattOff" 2 "HvStbyOk" 19 "HvOnDrvOk" 67 "HvChOffReq" 3 "HvBattOnReq" 68 "HvChOffOk" 4 "HvBattOnOk" 20 "HvOnDrvRdy" 28 "HvStepUpReq" 29 "HvStepUpOk" 30 "HvStepUp" 38 "HvStepDownReq" 39 "HvStepDownOk" 40 "HvStepDown" 110 "HvDcDcFail" 46 "HvAcChPreReq" 47 "HvAcChPreOk" 48 "HvAcChReq" 49 "HvAcChOk" 50 "HvAcCh" 120 "HvElmOff" 56 "HvDcChPreReq" 57 "HvDcChPreOk" 58 "HvDcChReq" 59 "HvDcChOk" 60 "HvDcCh" 69 "HvOnIdleReq" 70 "HvOnIdleOk" 96 "HvCpntOffReq" 97 "HvCpntOffOk" 98 "HvBattOffReq" 99 "HvBattOffOk" 109 "HvDcDcFailOffReq" 119 "HvElmOffReq" 126 "HvFailCpntOffReq" 255 "Init" 127 "HvFailCpntOffOk" 139 "HvFailUCtlOk" 140 "HvFailUCtl" 150 "HvEmgcyOff";
VAL_ 339 MO_HVK_AntriebFehlerstatus 0 "Komponente_IO" 6 "Keine_Komponentenfunktion" 7 "Init";
VAL_ 339 MO_MVK_Bordnetz_Anf 0 "keine_Anforderung" 1 "Bordnetzaktivitaet_gefordert";
VAL_ 339 MO_HVK_AntriebZustand 0 "Antrieb_AUS" 1 "Antrieb_Startphase" 2 "E_Fahren" 3 "Hybrid_Fahren" 7 "Init";
VAL_ 339 MO_HVK_EmFehlerstatus 0 "Komponente_IO" 1 "Eingeschr_KompFkt_Teilbetrieb" 3 "Eingeschr_KompFkt_Interlock" 6 "Keine_Komponentenfunktion" 7 "Init";
VAL_ 339 MO_MVK_AntriebFehlerstatus 0 "Komponente_IO" 6 "Keine_Komponentenfunktion" 7 "Init";
VAL_ 339 MO_MVK_AntriebZustand 0 "Antrieb_AUS" 1 "Antrieb_Startphase" 2 "FreilaufMotorAus" 7 "Init";
VAL_ 339 MO_MVK_EmFehlerstatus 0 "Komponente_IO" 1 "Eingeschr_KompFkt_Teilbetrieb" 6 "Keine_Komponentenfunktion" 7 "Init";
VAL_ 339 MO_MVK_EmIstzustand 128 "MvFailBattOffReq" 0 "MvOff" 129 "MvFailBattOffOk" 1 "MvStbyReq" 18 "MvOnDrvReq" 138 "MvFailUCtlReq" 10 "MvOnIdle" 130 "MvFailBattOff" 2 "MvStbyOk" 19 "MvOnDrvOk" 3 "MvBattOnReq" 4 "MvBattOnOk" 20 "MvOnDrv" 28 "MvStepUpReq" 29 "MvStepUpOk" 30 "MvStepUp" 38 "MvStepDownReq" 39 "MvStepDownOk" 40 "MvStepDown" 96 "MvCpntOffReq" 97 "MvCpntOffOk" 98 "MvBattOffReq" 99 "MvBattOffOk" 109 "MvDcDcFailOffReq" 110 "MvDcDcFail" 119 "MvElmFailOffReq" 120 "MvElmFail" 126 "MvFailCpntOffReq" 255 "Init" 127 "MvFailCpntOffOk" 139 "MvFailUCtlOk" 140 "MvFailUCtl" 150 "MvEmgcyOff";
